VERSION ""

NS_ :

BS_:

BU_: WSGW VCM TBIOM RCIOM FCIOM CCIOM BPMU

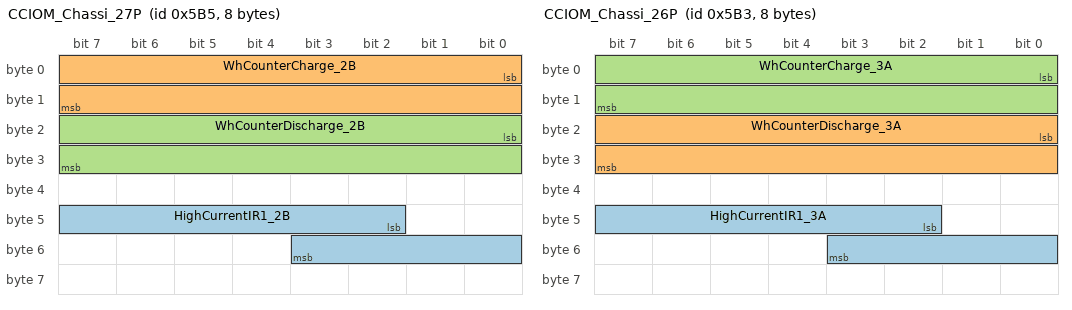
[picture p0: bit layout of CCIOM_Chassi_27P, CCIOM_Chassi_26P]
BO_ 1461 CCIOM_Chassi_27P: 8 CCIOM
 SG_ HighCurrentIR1_2B : 42|10@1+ (1E-005,0) [0|0.01023] "Ohm"  VCM
 SG_ WhCounterCharge_2B : 0|16@1+ (50,0) [0|3276750] "Wh"  VCM
 SG_ WhCounterDischarge_2B : 16|16@1+ (50,0) [0|3276750] "Wh"  VCM

BO_ 1459 CCIOM_Chassi_26P: 8 CCIOM
 SG_ HighCurrentIR1_3A : 42|10@1+ (1E-005,0) [0|0.01023] "Ohm"  VCM
 SG_ WhCounterDischarge_3A : 16|16@1+ (50,0) [0|3276750] "Wh"  VCM
 SG_ WhCounterCharge_3A : 0|16@1+ (50,0) [0|3276750] "Wh"  VCM

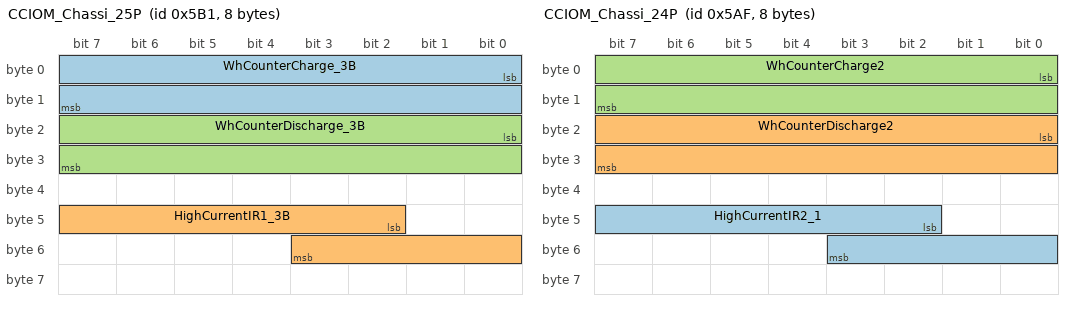
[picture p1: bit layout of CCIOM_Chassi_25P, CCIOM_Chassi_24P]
BO_ 1457 CCIOM_Chassi_25P: 8 CCIOM
 SG_ WhCounterCharge_3B : 0|16@1+ (50,0) [0|3276750] "Wh"  VCM
 SG_ HighCurrentIR1_3B : 42|10@1+ (1E-005,0) [0|0.01023] "Ohm"  VCM
 SG_ WhCounterDischarge_3B : 16|16@1+ (50,0) [0|3276750] "Wh"  VCM

BO_ 1455 CCIOM_Chassi_24P: 8 CCIOM
 SG_ HighCurrentIR2_1 : 42|10@1+ (1E-005,0) [0|0.01023] "Ohm"  VCM
 SG_ WhCounterDischarge2 : 16|16@1+ (50,0) [0|3276750] "Wh"  VCM
 SG_ WhCounterCharge2 : 0|16@1+ (50,0) [0|3276750] "Wh"  VCM

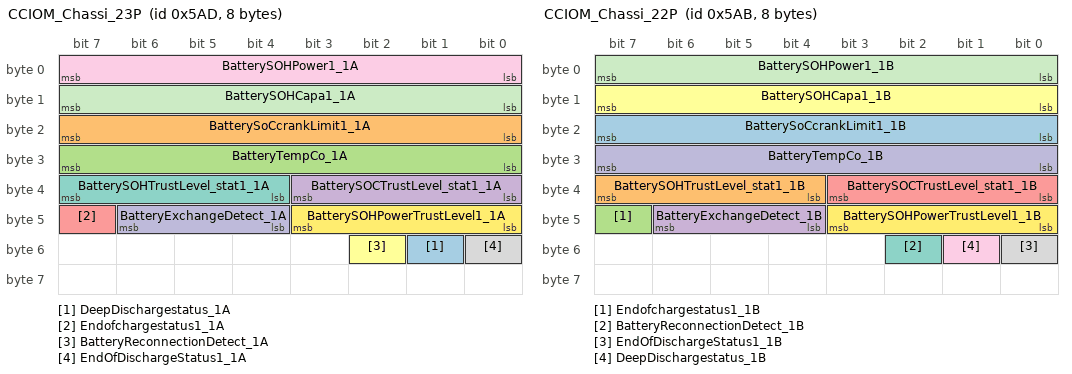
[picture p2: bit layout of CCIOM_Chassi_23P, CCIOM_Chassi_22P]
BO_ 1453 CCIOM_Chassi_23P: 8 CCIOM
 SG_ DeepDischargestatus_1A : 49|1@1+ (1,0) [0|0] ""  VCM
 SG_ BatterySoCcrankLimit1_1A : 16|8@1+ (1,0) [0|255] "Percent"  VCM
 SG_ BatteryTempCo_1A : 24|8@1+ (1,0) [0|255] "Percent"  VCM
 SG_ BatterySOCTrustLevel_stat1_1A : 32|4@1+ (1,0) [0|0] ""  VCM
 SG_ Endofchargestatus1_1A : 47|1@1+ (1,0) [0|0] ""  VCM
 SG_ BatteryReconnectionDetect_1A : 50|1@1+ (1,0) [0|0] ""  VCM
 SG_ BatterySOHTrustLevel_stat1_1A : 36|4@1+ (1,0) [0|0] ""  VCM
 SG_ EndOfDischargeStatus1_1A : 48|1@1+ (1,0) [0|0] ""  VCM
 SG_ BatterySOHPower1_1A : 0|8@1+ (0.1,0) [0|25.5] "V"  VCM
 SG_ BatteryExchangeDetect_1A : 44|3@1+ (1,0) [0|0] ""  VCM
 SG_ BatterySOHCapa1_1A : 8|8@1+ (0.5,0) [0|127.5] "Percent"  VCM
 SG_ BatterySOHPowerTrustLevel1_1A : 40|4@1+ (1,0) [0|0] ""  VCM

BO_ 1451 CCIOM_Chassi_22P: 8 CCIOM
 SG_ BatterySoCcrankLimit1_1B : 16|8@1+ (1,0) [0|255] "Percent"  VCM
 SG_ BatterySOHTrustLevel_stat1_1B : 36|4@1+ (1,0) [0|0] ""  VCM
 SG_ Endofchargestatus1_1B : 47|1@1+ (1,0) [0|0] ""  VCM
 SG_ BatteryExchangeDetect_1B : 44|3@1+ (1,0) [0|0] ""  VCM
 SG_ BatterySOCTrustLevel_stat1_1B : 32|4@1+ (1,0) [0|0] ""  VCM
 SG_ BatterySOHCapa1_1B : 8|8@1+ (0.5,0) [0|127.5] "Percent"  VCM
 SG_ BatteryReconnectionDetect_1B : 50|1@1+ (1,0) [0|0] ""  VCM
 SG_ EndOfDischargeStatus1_1B : 48|1@1+ (1,0) [0|0] ""  VCM
 SG_ DeepDischargestatus_1B : 49|1@1+ (1,0) [0|0] ""  VCM
 SG_ BatteryTempCo_1B : 24|8@1+ (1,0) [0|255] "Percent"  VCM
 SG_ BatterySOHPower1_1B : 0|8@1+ (0.1,0) [0|25.5] "V"  VCM
 SG_ BatterySOHPowerTrustLevel1_1B : 40|4@1+ (1,0) [0|0] ""  VCM

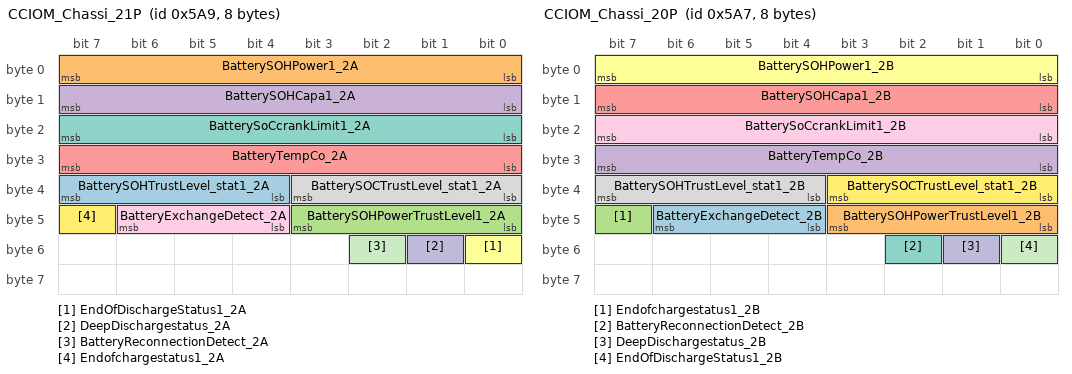
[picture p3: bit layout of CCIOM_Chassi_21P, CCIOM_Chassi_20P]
BO_ 1449 CCIOM_Chassi_21P: 8 CCIOM
 SG_ BatterySOHTrustLevel_stat1_2A : 36|4@1+ (1,0) [0|0] ""  VCM
 SG_ BatterySOHPower1_2A : 0|8@1+ (0.1,0) [0|25.5] "V"  VCM
 SG_ BatterySOHPowerTrustLevel1_2A : 40|4@1+ (1,0) [0|0] ""  VCM
 SG_ BatterySOHCapa1_2A : 8|8@1+ (0.5,0) [0|127.5] "Percent"  VCM
 SG_ BatteryTempCo_2A : 24|8@1+ (1,0) [0|255] "Percent"  VCM
 SG_ EndOfDischargeStatus1_2A : 48|1@1+ (1,0) [0|0] ""  VCM
 SG_ BatterySoCcrankLimit1_2A : 16|8@1+ (1,0) [0|255] "Percent"  VCM
 SG_ BatterySOCTrustLevel_stat1_2A : 32|4@1+ (1,0) [0|0] ""  VCM
 SG_ BatteryExchangeDetect_2A : 44|3@1+ (1,0) [0|0] ""  VCM
 SG_ DeepDischargestatus_2A : 49|1@1+ (1,0) [0|0] ""  VCM
 SG_ BatteryReconnectionDetect_2A : 50|1@1+ (1,0) [0|0] ""  VCM
 SG_ Endofchargestatus1_2A : 47|1@1+ (1,0) [0|0] ""  VCM

BO_ 1447 CCIOM_Chassi_20P: 8 CCIOM
 SG_ BatteryExchangeDetect_2B : 44|3@1+ (1,0) [0|0] ""  VCM
 SG_ BatterySOHPowerTrustLevel1_2B : 40|4@1+ (1,0) [0|0] ""  VCM
 SG_ Endofchargestatus1_2B : 47|1@1+ (1,0) [0|0] ""  VCM
 SG_ BatteryTempCo_2B : 24|8@1+ (1,0) [0|255] "Percent"  VCM
 SG_ BatterySOHCapa1_2B : 8|8@1+ (0.5,0) [0|127.5] "Percent"  VCM
 SG_ BatterySOHPower1_2B : 0|8@1+ (0.1,0) [0|25.5] "V"  VCM
 SG_ BatteryReconnectionDetect_2B : 50|1@1+ (1,0) [0|0] ""  VCM
 SG_ BatterySOHTrustLevel_stat1_2B : 36|4@1+ (1,0) [0|0] ""  VCM
 SG_ BatterySoCcrankLimit1_2B : 16|8@1+ (1,0) [0|255] "Percent"  VCM
 SG_ DeepDischargestatus_2B : 49|1@1+ (1,0) [0|0] ""  VCM
 SG_ EndOfDischargeStatus1_2B : 48|1@1+ (1,0) [0|0] ""  VCM
 SG_ BatterySOCTrustLevel_stat1_2B : 32|4@1+ (1,0) [0|0] ""  VCM

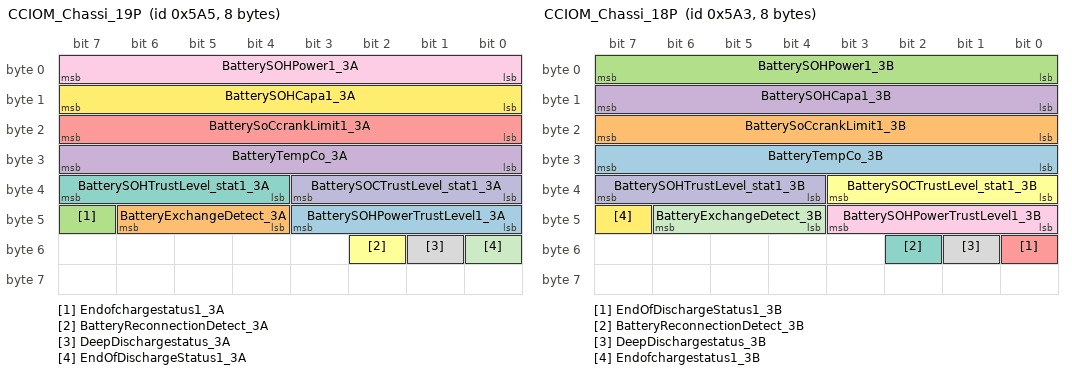
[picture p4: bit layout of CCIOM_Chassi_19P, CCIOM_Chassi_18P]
BO_ 1445 CCIOM_Chassi_19P: 8 CCIOM
 SG_ BatterySOHPowerTrustLevel1_3A : 40|4@1+ (1,0) [0|0] ""  VCM
 SG_ BatteryExchangeDetect_3A : 44|3@1+ (1,0) [0|0] ""  VCM
 SG_ Endofchargestatus1_3A : 47|1@1+ (1,0) [0|0] ""  VCM
 SG_ BatteryTempCo_3A : 24|8@1+ (1,0) [0|255] "Percent"  VCM
 SG_ BatterySoCcrankLimit1_3A : 16|8@1+ (1,0) [0|255] "Percent"  VCM
 SG_ BatteryReconnectionDetect_3A : 50|1@1+ (1,0) [0|0] ""  VCM
 SG_ BatterySOHTrustLevel_stat1_3A : 36|4@1+ (1,0) [0|0] ""  VCM
 SG_ DeepDischargestatus_3A : 49|1@1+ (1,0) [0|0] ""  VCM
 SG_ BatterySOHPower1_3A : 0|8@1+ (0.1,0) [0|25.5] "V"  VCM
 SG_ BatterySOCTrustLevel_stat1_3A : 32|4@1+ (1,0) [0|0] ""  VCM
 SG_ EndOfDischargeStatus1_3A : 48|1@1+ (1,0) [0|0] ""  VCM
 SG_ BatterySOHCapa1_3A : 8|8@1+ (0.5,0) [0|127.5] "Percent"  VCM

BO_ 1443 CCIOM_Chassi_18P: 8 CCIOM
 SG_ BatteryTempCo_3B : 24|8@1+ (1,0) [0|255] "Percent"  VCM
 SG_ BatterySoCcrankLimit1_3B : 16|8@1+ (1,0) [0|255] "Percent"  VCM
 SG_ BatterySOHPower1_3B : 0|8@1+ (0.1,0) [0|25.5] "V"  VCM
 SG_ BatterySOHCapa1_3B : 8|8@1+ (0.5,0) [0|127.5] "Percent"  VCM
 SG_ EndOfDischargeStatus1_3B : 48|1@1+ (1,0) [0|0] ""  VCM
 SG_ BatterySOCTrustLevel_stat1_3B : 32|4@1+ (1,0) [0|0] ""  VCM
 SG_ BatteryReconnectionDetect_3B : 50|1@1+ (1,0) [0|0] ""  VCM
 SG_ DeepDischargestatus_3B : 49|1@1+ (1,0) [0|0] ""  VCM
 SG_ BatterySOHPowerTrustLevel1_3B : 40|4@1+ (1,0) [0|0] ""  VCM
 SG_ BatterySOHTrustLevel_stat1_3B : 36|4@1+ (1,0) [0|0] ""  VCM
 SG_ BatteryExchangeDetect_3B : 44|3@1+ (1,0) [0|0] ""  VCM
 SG_ Endofchargestatus1_3B : 47|1@1+ (1,0) [0|0] ""  VCM

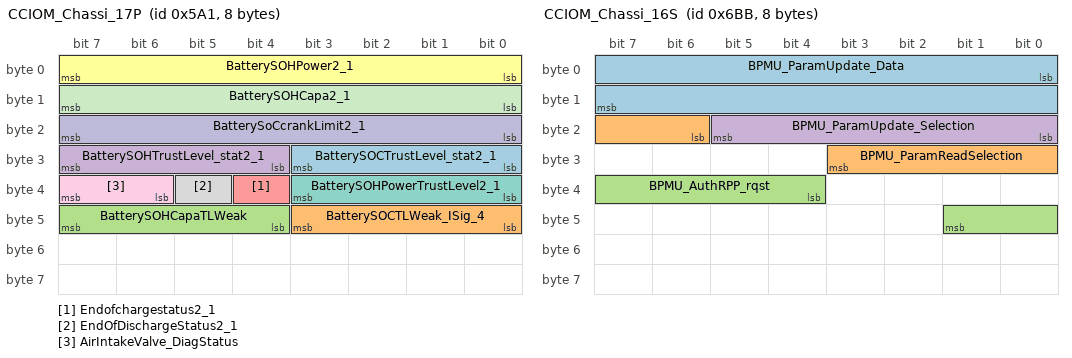
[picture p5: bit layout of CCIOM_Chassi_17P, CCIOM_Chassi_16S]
BO_ 1441 CCIOM_Chassi_17P: 8 CCIOM
 SG_ BatterySOCTrustLevel_stat2_1 : 24|4@1+ (1,0) [0|0] ""  VCM
 SG_ BatterySOCTLWeak_ISig_4 : 40|4@1+ (1,0) [0|0] ""  VCM
 SG_ BatterySOHCapaTLWeak : 44|4@1+ (1,0) [0|0] ""  VCM
 SG_ BatterySOHTrustLevel_stat2_1 : 28|4@1+ (1,0) [0|0] ""  VCM
 SG_ Endofchargestatus2_1 : 36|1@1+ (1,0) [0|0] ""  VCM
 SG_ BatterySOHPower2_1 : 0|8@1+ (0.1,0) [0|25.5] "V"  VCM
 SG_ BatterySOHPowerTrustLevel2_1 : 32|4@1+ (1,0) [0|0] ""  VCM
 SG_ EndOfDischargeStatus2_1 : 37|1@1+ (1,0) [0|0] ""  VCM
 SG_ AirIntakeValve_DiagStatus : 38|2@1+ (1,0) [0|0] ""  VCM
 SG_ BatterySoCcrankLimit2_1 : 16|8@1+ (1,0) [0|255] "Percent"  VCM
 SG_ BatterySOHCapa2_1 : 8|8@1+ (0.5,0) [0|127.5] "Percent"  VCM

BO_ 1723 CCIOM_Chassi_16S: 8 CCIOM
 SG_ BPMU_ParamUpdate_Data : 0|16@1+ (1,0) [0|0] ""  BPMU
 SG_ BPMU_ParamReadSelection : 22|6@1+ (1,0) [0|0] ""  BPMU
 SG_ BPMU_AuthRPP_rqst : 36|6@1+ (1,0) [0|0] ""  BPMU
 SG_ BPMU_ParamUpdate_Selection : 16|6@1+ (1,0) [0|0] ""  BPMU

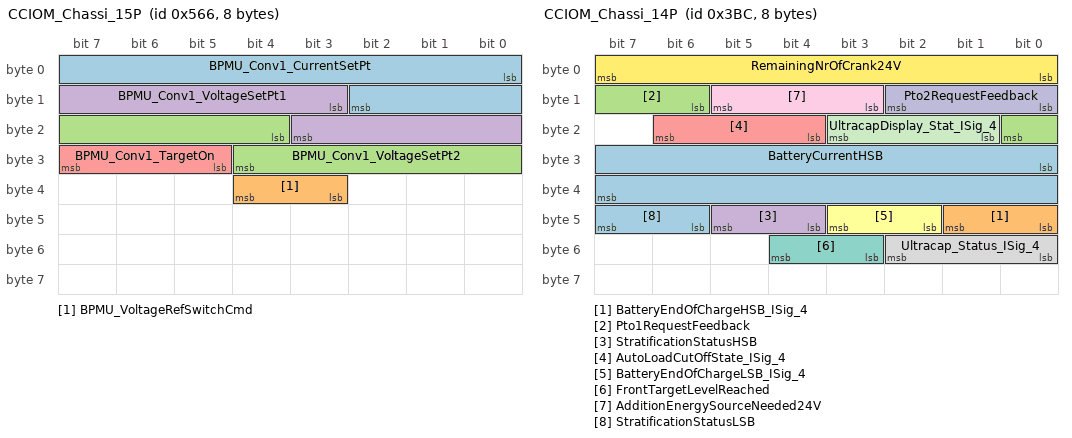
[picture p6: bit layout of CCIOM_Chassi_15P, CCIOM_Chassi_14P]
BO_ 1382 CCIOM_Chassi_15P: 8 CCIOM
 SG_ BPMU_Conv1_CurrentSetPt : 0|11@1+ (0.1,-100) [-100|104.7] "A"  BPMU
 SG_ BPMU_VoltageRefSwitchCmd : 35|2@1+ (1,0) [0|0] ""  BPMU
 SG_ BPMU_Conv1_VoltageSetPt2 : 20|9@1+ (0.1,0) [0|51.1] "V"  BPMU
 SG_ BPMU_Conv1_VoltageSetPt1 : 11|9@1+ (0.1,0) [0|51.1] "V"  BPMU
 SG_ BPMU_Conv1_TargetOn : 29|3@1+ (1,0) [0|0] ""  BPMU

BO_ 956 CCIOM_Chassi_14P: 8 CCIOM
 SG_ BatteryCurrentHSB : 24|16@1+ (0.05,-2000) [-2000|1276.75] "A"  VCM
 SG_ BatteryEndOfChargeHSB_ISig_4 : 40|2@1+ (1,0) [0|0] ""  VCM
 SG_ Pto1RequestFeedback : 14|3@1+ (1,0) [0|0] ""  VCM
 SG_ StratificationStatusHSB : 44|2@1+ (1,0) [0|0] ""  VCM
 SG_ AutoLoadCutOffState_ISig_4 : 20|3@1+ (1,0) [0|0] ""  VCM
 SG_ BatteryEndOfChargeLSB_ISig_4 : 42|2@1+ (1,0) [0|0] ""  VCM
 SG_ FrontTargetLevelReached : 51|2@1+ (1,0) [0|0] ""  RCIOM,VCM
 SG_ Ultracap_Status_ISig_4 : 48|3@1+ (1,0) [0|0] ""  VCM
 SG_ AdditionEnergySourceNeeded24V : 11|3@1+ (1,0) [0|0] ""  VCM
 SG_ Pto2RequestFeedback : 8|3@1+ (1,0) [0|0] ""  VCM
 SG_ UltracapDisplay_Stat_ISig_4 : 17|3@1+ (1,0) [0|0] ""  VCM
 SG_ RemainingNrOfCrank24V : 0|8@1+ (1,0) [0|255] "Count"  VCM
 SG_ StratificationStatusLSB : 46|2@1+ (1,0) [0|0] ""  VCM

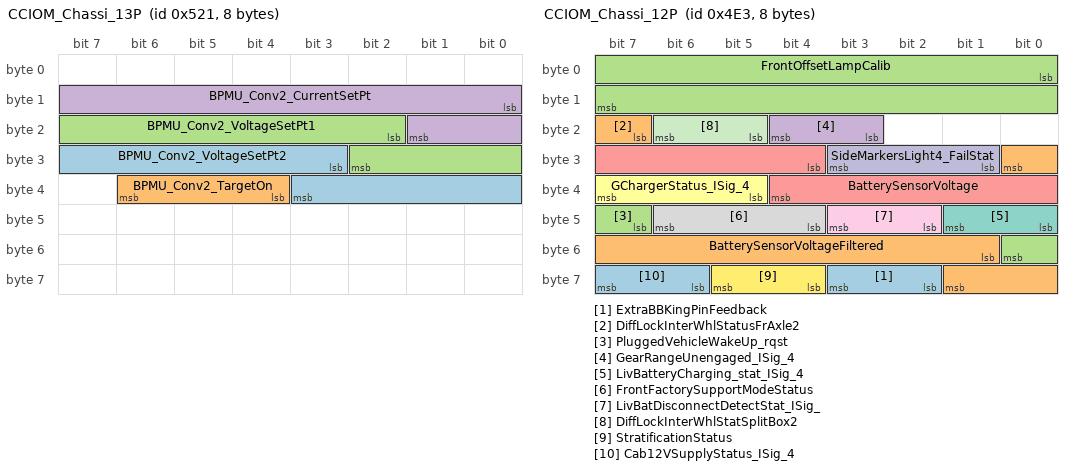
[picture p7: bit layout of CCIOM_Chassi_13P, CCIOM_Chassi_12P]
BO_ 1313 CCIOM_Chassi_13P: 8 CCIOM
 SG_ BPMU_Conv2_VoltageSetPt2 : 27|9@1+ (0.1,0) [0|51.1] "V"  BPMU
 SG_ BPMU_Conv2_TargetOn : 36|3@1+ (1,0) [0|0] ""  BPMU
 SG_ BPMU_Conv2_VoltageSetPt1 : 18|9@1+ (0.1,0) [0|51.1] "V"  BPMU
 SG_ BPMU_Conv2_CurrentSetPt : 8|10@1+ (0.1,-30) [-30|72.3] "A"  BPMU

BO_ 1251 CCIOM_Chassi_12P: 8 CCIOM
 SG_ ExtraBBKingPinFeedback : 58|2@1+ (1,0) [0|0] ""  VCM
 SG_ DiffLockInterWhlStatusFrAxle2 : 23|2@1+ (1,0) [0|0] ""  VCM
 SG_ PluggedVehicleWakeUp_rqst : 47|2@1+ (1,0) [0|0] ""  VCM
 SG_ GearRangeUnengaged_ISig_4 : 19|2@1+ (1,0) [0|0] ""  VCM
 SG_ BatterySensorVoltage : 28|9@1+ (0.1,0) [0|51.1] "V"  VCM
 SG_ GChargerStatus_ISig_4 : 37|3@1+ (1,0) [0|0] ""  VCM
 SG_ LivBatteryCharging_stat_ISig_4 : 40|2@1+ (1,0) [0|0] ""  VCM
 SG_ FrontFactorySupportModeStatus : 44|3@1+ (1,0) [0|0] ""  RCIOM,VCM
 SG_ LivBatDisconnectDetectStat_ISig_ : 42|2@1+ (1,0) [0|0] ""  VCM
 SG_ SideMarkersLight4_FailStat : 25|3@1+ (1,0) [0|0] ""  VCM
 SG_ DiffLockInterWhlStatSplitBox2 : 21|2@1+ (1,0) [0|0] ""  VCM
 SG_ StratificationStatus : 60|2@1+ (1,0) [0|0] ""  VCM
 SG_ Cab12VSupplyStatus_ISig_4 : 62|2@1+ (1,0) [0|0] ""  VCM
 SG_ BatterySensorVoltageFiltered : 49|9@1+ (0.1,0) [0|51.1] "V"  VCM
 SG_ FrontOffsetLampCalib : 0|16@1+ (0.1,-3200) [-3200|3353.5] "mm"  RCIOM,VCM

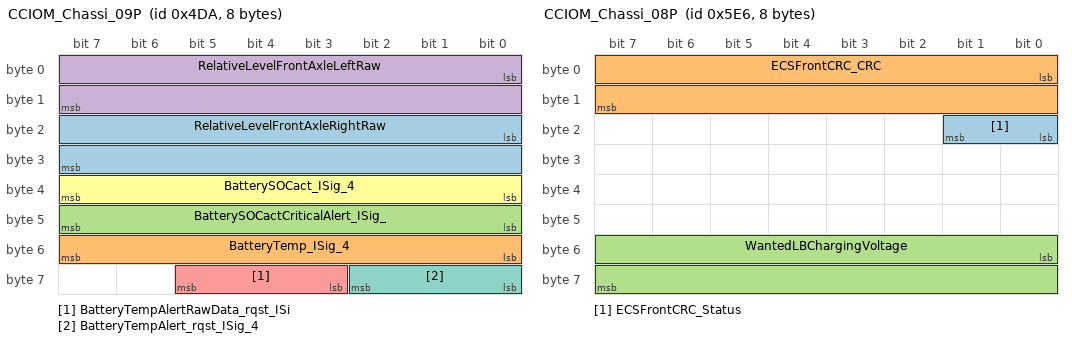
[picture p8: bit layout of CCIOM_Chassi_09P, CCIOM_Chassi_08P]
BO_ 1242 CCIOM_Chassi_09P: 8 CCIOM
 SG_ RelativeLevelFrontAxleRightRaw : 16|16@1+ (0.1,-3200) [-3200|3353.5] "mm"  VCM,RCIOM
 SG_ BatteryTemp_ISig_4 : 48|8@1+ (1,-45) [-45|210] "DegreeC"  VCM
 SG_ BatterySOCactCriticalAlert_ISig_ : 40|8@1+ (0.5,0) [0|127.5] "Percent"  VCM
 SG_ RelativeLevelFrontAxleLeftRaw : 0|16@1+ (0.1,-3200) [-3200|3353.5] "mm"  RCIOM,VCM
 SG_ BatteryTempAlertRawData_rqst_ISi : 59|3@1+ (1,0) [0|0] ""  VCM
 SG_ BatterySOCact_ISig_4 : 32|8@1+ (0.5,0) [0|127.5] "Percent"  VCM
 SG_ BatteryTempAlert_rqst_ISig_4 : 56|3@1+ (1,0) [0|0] ""  VCM

BO_ 1510 CCIOM_Chassi_08P: 8 CCIOM
 SG_ ECSFrontCRC_Status : 16|2@1+ (1,0) [0|0] ""  VCM,RCIOM
 SG_ ECSFrontCRC_CRC : 0|16@1+ (1,0) [0|65535] "NotApplicable"  VCM,RCIOM
 SG_ WantedLBChargingVoltage : 48|16@1+ (0.01,0) [0|655.35] "V"  VCM

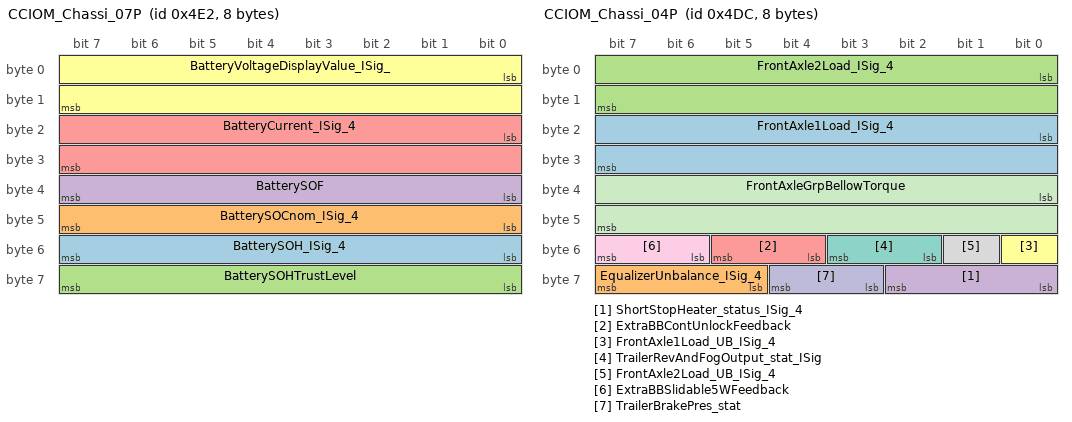
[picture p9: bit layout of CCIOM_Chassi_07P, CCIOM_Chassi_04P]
BO_ 1250 CCIOM_Chassi_07P: 8 CCIOM
 SG_ BatterySOH_ISig_4 : 48|8@1+ (0.5,0) [0|127.5] "Percent"  VCM
 SG_ BatterySOCnom_ISig_4 : 40|8@1+ (0.5,0) [0|127.5] "Percent"  VCM
 SG_ BatterySOHTrustLevel : 56|8@1+ (0.5,0) [0|127.5] "Percent"  VCM
 SG_ BatterySOF : 32|8@1+ (1,0) [0|255] "h"  VCM
 SG_ BatteryCurrent_ISig_4 : 16|16@1+ (0.05,-1600) [-1600|1676.75] "A"  VCM
 SG_ BatteryVoltageDisplayValue_ISig_ : 0|16@1+ (0.05,0) [0|3276.75] "V"  VCM

BO_ 823 CCIOM_Chassi_06P: 8 CCIOM
 SG_ DifferentialLockStateFrAxle1_UB_ : 31|1@1+ (1,0) [0|0] ""  VCM
 SG_ FrontLimpHomeTrigger : 24|3@1+ (1,0) [0|0] ""  VCM,RCIOM
 SG_ TransmLowRangeSenseSwitch_ISig_4 : 8|2@1+ (1,0) [0|0] ""  VCM
 SG_ ElectricalLoadReduction_rqst_ISi : 21|3@1+ (1,0) [0|0] ""  VCM,RCIOM
 SG_ TransmReverseDirectionSw_stat : 56|2@1+ (1,0) [0|0] ""  VCM
 SG_ FifthWheelLockingInformation_UB_ : 53|1@1+ (1,0) [0|0] ""  VCM,RCIOM
 SG_ ManTransmiOilTemp_ISig_4 : 32|16@1+ (0.03125,-273) [-273|1774.96875] "DegreeC"  VCM
 SG_ DirInd_MiddleSide_Status : 58|3@1+ (1,0) [0|0] ""  VCM
 SG_ BatterySOCAlert_rqst_ISig_4 : 16|3@1+ (1,0) [0|0] ""  VCM
 SG_ DoubleFrontAxleSteeringWarning_I : 2|2@1+ (1,0) [0|0] ""  VCM
 SG_ DifferentialLockStateCentral_ISi : 0|2@1+ (1,0) [0|0] ""  VCM
 SG_ FifthWheelLockingInformation_ISi : 12|4@1+ (1,0) [0|0] ""  RCIOM,VCM
 SG_ ElectricalLoadReduction_rqst_UB_ : 30|1@1+ (1,0) [0|0] ""  VCM,RCIOM
 SG_ DiffLockInterWhlStatusSplitBox : 54|2@1+ (1,0) [0|0] ""  VCM
 SG_ WrknLghtChassisOutpFalr_stat : 48|3@1+ (1,0) [0|0] ""  VCM
 SG_ DifferentialLockStateFrAxle1_ISi : 6|2@1+ (1,0) [0|0] ""  VCM
 SG_ GearSplit_Status_ISig_4 : 10|2@1+ (1,0) [0|0] ""  VCM
 SG_ ManTransmiOilTemp_UB_ISig_4 : 51|1@1+ (1,0) [0|0] ""  VCM
 SG_ LoadCutOffIndication_cmd_ISig_4 : 4|2@1+ (1,0) [0|0] ""  VCM
 SG_ FifthWheelHandleLock_ind : 27|2@1+ (1,0) [0|0] ""  VCM
 SG_ GearSplit_Status_UB_ISig_4 : 52|1@1+ (1,0) [0|0] ""  VCM
 SG_ BatteryCapacity_Ack_ISig_4 : 19|2@1+ (1,0) [0|0] ""  VCM

BO_ 1244 CCIOM_Chassi_04P: 8 CCIOM
 SG_ FrontAxle1Load_ISig_4 : 16|16@1+ (0.5,0) [0|32767.5] "kg"  RCIOM,VCM
 SG_ EqualizerUnbalance_ISig_4 : 61|3@1+ (1,0) [0|0] ""  VCM
 SG_ FrontAxle2Load_ISig_4 : 0|16@1+ (0.5,0) [0|32767.5] "kg"  RCIOM,VCM
 SG_ ShortStopHeater_status_ISig_4 : 56|3@1+ (1,0) [0|0] ""  VCM
 SG_ ExtraBBContUnlockFeedback : 52|2@1+ (1,0) [0|0] ""  VCM
 SG_ FrontAxle1Load_UB_ISig_4 : 48|1@1+ (1,0) [0|0] ""  RCIOM,VCM
 SG_ TrailerRevAndFogOutput_stat_ISig : 50|2@1+ (1,0) [0|0] ""  VCM,RCIOM
 SG_ FrontAxle2Load_UB_ISig_4 : 49|1@1+ (1,0) [0|0] ""  VCM,RCIOM
 SG_ ExtraBBSlidable5WFeedback : 54|2@1+ (1,0) [0|0] ""  VCM
 SG_ TrailerBrakePres_stat : 59|2@1+ (1,0) [0|0] ""  VCM
 SG_ FrontAxleGrpBellowTorque : 32|16@1+ (1000,-10000000) [-10000000|55535000] "Nm"  VCM,RCIOM

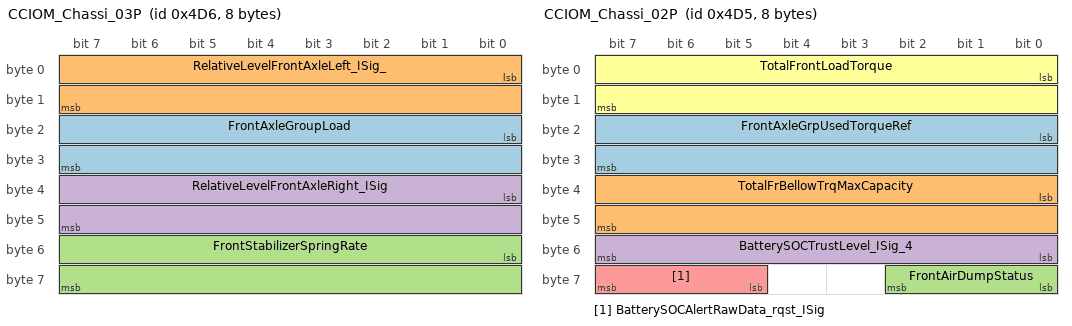
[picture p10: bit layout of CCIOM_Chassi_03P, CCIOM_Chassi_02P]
BO_ 1238 CCIOM_Chassi_03P: 8 CCIOM
 SG_ FrontAxleGroupLoad : 16|16@1+ (2,0) [0|131070] "kg"  RCIOM,VCM
 SG_ RelativeLevelFrontAxleLeft_ISig_ : 0|16@1+ (0.1,-3200) [-3200|3353.5] "mm"  RCIOM,VCM
 SG_ FrontStabilizerSpringRate : 48|16@1+ (1,0) [0|65535] "kNm_per_rad"  RCIOM,VCM
 SG_ RelativeLevelFrontAxleRight_ISig : 32|16@1+ (0.1,-3200) [-3200|3353.5] "mm"  VCM,RCIOM

BO_ 1237 CCIOM_Chassi_02P: 8 CCIOM
 SG_ FrontAxleGrpUsedTorqueRef : 16|16@1+ (1000,-10000000) [-10000000|55535000] "Nm"  VCM,RCIOM
 SG_ TotalFrBellowTrqMaxCapacity : 32|16@1+ (1000,-10000000) [-10000000|55535000] "Nm"  RCIOM,VCM
 SG_ FrontAirDumpStatus : 56|3@1+ (1,0) [0|0] ""  RCIOM,VCM
 SG_ BatterySOCTrustLevel_ISig_4 : 48|8@1+ (0.5,0) [0|127.5] "Percent"  VCM
 SG_ BatterySOCAlertRawData_rqst_ISig : 61|3@1+ (1,0) [0|0] ""  VCM
 SG_ TotalFrontLoadTorque : 0|16@1+ (1000,-10000000) [-10000000|55535000] "Nm"  RCIOM,VCM

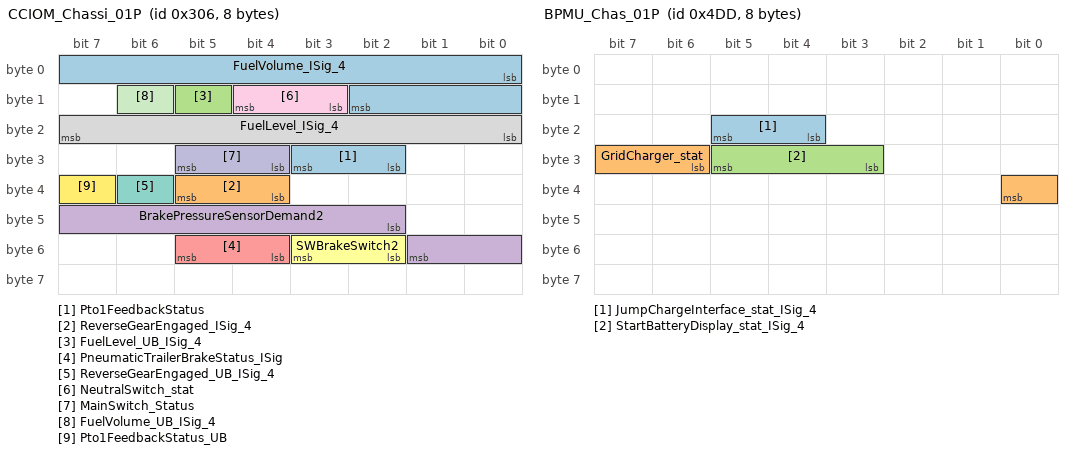
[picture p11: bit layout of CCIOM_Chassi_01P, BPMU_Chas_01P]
BO_ 774 CCIOM_Chassi_01P: 8 CCIOM
 SG_ Pto1FeedbackStatus : 26|2@1+ (1,0) [0|0] ""  VCM
 SG_ ReverseGearEngaged_ISig_4 : 36|2@1+ (1,0) [0|0] ""  VCM,WSGW,RCIOM
 SG_ FuelLevel_UB_ISig_4 : 13|1@1+ (1,0) [0|0] ""  VCM
 SG_ BrakePressureSensorDemand2 : 42|8@1+ (1,0) [0|255] "Percent"  RCIOM,VCM
 SG_ PneumaticTrailerBrakeStatus_ISig : 52|2@1+ (1,0) [0|0] ""  VCM,RCIOM
 SG_ SWBrakeSwitch2 : 50|2@1+ (1,0) [0|0] ""  VCM,RCIOM
 SG_ ReverseGearEngaged_UB_ISig_4 : 38|1@1+ (1,0) [0|0] ""  VCM,RCIOM
 SG_ FuelLevel_ISig_4 : 16|8@1+ (0.4,0) [0|102] "Percent"  VCM
 SG_ NeutralSwitch_stat : 11|2@1+ (1,0) [0|0] ""  VCM
 SG_ MainSwitch_Status : 28|2@1+ (1,0) [0|0] ""  VCM
 SG_ FuelVolume_UB_ISig_4 : 14|1@1+ (1,0) [0|0] ""  VCM
 SG_ Pto1FeedbackStatus_UB : 39|1@1+ (1,0) [0|0] ""  VCM
 SG_ FuelVolume_ISig_4 : 0|11@1+ (1,0) [0|2047] "l"  VCM

BO_ 1245 BPMU_Chas_01P: 8 VCM
 SG_ JumpChargeInterface_stat_ISig_4 : 20|2@1+ (1,0) [0|0] ""  CCIOM
 SG_ GridCharger_stat : 30|3@1+ (1,0) [0|0] ""  CCIOM
 SG_ StartBatteryDisplay_stat_ISig_4 : 27|3@1+ (1,0) [0|0] ""  CCIOM

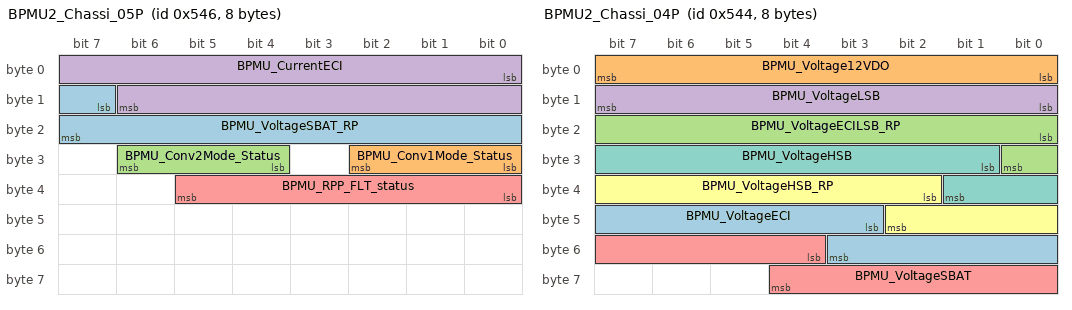
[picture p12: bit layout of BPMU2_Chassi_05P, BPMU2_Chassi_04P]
BO_ 1350 BPMU2_Chassi_05P: 8 BPMU
 SG_ BPMU_VoltageSBAT_RP : 15|9@1+ (0.1,0) [0|51.1] "V"  CCIOM
 SG_ BPMU_Conv1Mode_Status : 24|3@1+ (1,0) [0|0] ""  CCIOM
 SG_ BPMU_Conv2Mode_Status : 28|3@1+ (1,0) [0|0] ""  CCIOM
 SG_ BPMU_CurrentECI : 0|15@1+ (0.01,-150) [-150|177.67] "A"  CCIOM
 SG_ BPMU_RPP_FLT_status : 32|6@1+ (1,0) [0|63] "NotApplicable"  CCIOM

BO_ 1348 BPMU2_Chassi_04P: 8 BPMU
 SG_ BPMU_VoltageECI : 43|9@1+ (0.1,0) [0|51.1] "V"  CCIOM
 SG_ BPMU_Voltage12VDO : 0|8@1+ (0.1,0) [0|25.5] "V"  CCIOM
 SG_ BPMU_VoltageECILSB_RP : 16|9@1+ (0.1,0) [0|51.1] "V"  CCIOM
 SG_ BPMU_VoltageLSB : 8|8@1+ (0.1,0) [0|25.5] "V"  CCIOM
 SG_ BPMU_VoltageSBAT : 52|9@1+ (0.1,0) [0|51.1] "V"  CCIOM
 SG_ BPMU_VoltageHSB_RP : 34|9@1+ (0.1,0) [0|51.1] "V"  CCIOM
 SG_ BPMU_VoltageHSB : 25|9@1+ (0.1,0) [0|51.1] "V"  CCIOM

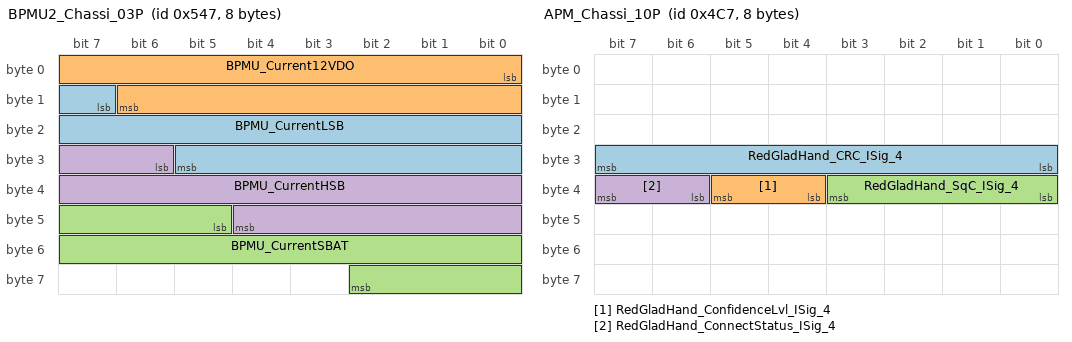
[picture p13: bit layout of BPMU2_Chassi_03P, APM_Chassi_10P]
BO_ 1351 BPMU2_Chassi_03P: 8 BPMU
 SG_ BPMU_CurrentLSB : 15|15@1+ (0.01,-150) [-150|177.67] "A"  CCIOM
 SG_ BPMU_Current12VDO : 0|15@1+ (0.01,-150) [-150|177.67] "A"  CCIOM
 SG_ BPMU_CurrentSBAT : 45|14@1+ (0.01,-50) [-50|113.83] "A"  CCIOM
 SG_ BPMU_CurrentHSB : 30|15@1+ (0.01,-150) [-150|177.67] "A"  CCIOM

BO_ 1252 BPMU2_Chassi_02P: 8 BPMU
 SG_ BPMU_FaultDiag2 : 32|32@1+ (1,0) [0|4294967295] "NotApplicable"  CCIOM
 SG_ BPMU_FaultDiag1 : 0|32@1+ (1,0) [0|4294967295] "NotApplicable"  CCIOM

BO_ 831 BPMU2_Chassi_01S: 8 BPMU
 SG_ BPMU_ParamRead_Data : 0|16@1+ (1,0) [0|0] ""  CCIOM
 SG_ BPMU_ParamRead_Selection : 16|6@1+ (1,0) [0|0] ""  CCIOM

BO_ 1730 AnmMsg_WSGW_C04: 8 WSGW
 SG_ AnmSig_WSGW_C04 : 0|32@1+ (1,0) [0|0] ""  VCM,RCIOM,FCIOM,CCIOM,TBIOM,BPMU

BO_ 1726 AnmMsg_VCM_C04: 8 VCM
 SG_ AnmSig_VCM_CAN04 : 0|32@1+ (1,0) [0|0] ""  FCIOM,CCIOM,BPMU,WSGW,TBIOM,RCIOM

BO_ 1725 AnmMsg_TBIOM_C04: 8 TBIOM
 SG_ AnmSig_TBIOM_CAN04 : 0|32@1+ (1,0) [0|0] ""  VCM,FCIOM,CCIOM,BPMU,RCIOM,WSGW

BO_ 1724 AnmMsg_RCIOM_C04: 8 RCIOM
 SG_ AnmSig_RCIOM_CAN04 : 0|32@1+ (1,0) [0|0] ""  VCM,WSGW,BPMU,FCIOM,CCIOM,TBIOM

BO_ 1729 AnmMsg_FCIOM_C04: 8 FCIOM
 SG_ AnmSig_FCIOM_CAN04 : 0|32@1+ (1,0) [0|0] ""  VCM,BPMU,CCIOM,WSGW,TBIOM,RCIOM

BO_ 1727 AnmMsg_CCIOM_C04: 8 CCIOM
 SG_ AnmSig_CCIOM_CAN04 : 0|32@1+ (1,0) [0|0] ""  BPMU,RCIOM,TBIOM,VCM,FCIOM,WSGW

BO_ 1728 AnmMsg_BPMU_C04: 8 BPMU
 SG_ AnmSig_BPMU_CAN04 : 0|32@1+ (1,0) [0|0] ""  TBIOM,FCIOM,WSGW,CCIOM,RCIOM,VCM

BO_ 1223 APM_Chassi_10P: 8 VCM
 SG_ RedGladHand_CRC_ISig_4 : 24|8@1+ (1,0) [0|255] ""  RCIOM
 SG_ RedGladHand_ConfidenceLvl_ISig_4 : 36|2@1+ (1,0) [0|0] ""  RCIOM
 SG_ RedGladHand_SqC_ISig_4 : 32|4@1+ (1,0) [0|14] "NotApplicable"  RCIOM
 SG_ RedGladHand_ConnectStatus_ISig_4 : 38|2@1+ (1,0) [0|0] ""  RCIOM

BO_ 822 APM_Chassi_04P: 8 VCM
 SG_ EPBPowerFeedRequest_ISig_4 : 32|2@1+ (1,0) [0|0] ""  CCIOM

BO_ 1345 APM_Chassi_02P: 8 VCM
 SG_ ServiceBrakeAirPrsCircuit1_ISig_ : 8|8@1+ (8,0) [0|2040] "kPa"  RCIOM

BO_ 949 APM_Chassi_01P: 8 VCM
 SG_ LowAirPressureAlert_ISig_4 : 18|2@1+ (1,0) [0|0] ""  RCIOM
 SG_ ParkBrakeActuationStatus_ISig_4 : 32|3@1+ (1,0) [0|0] ""  RCIOM,CCIOM

BA_DEF_ BO_  "GenMsgStartDelayTime" INT 0 0;
BA_DEF_ BO_  "GenMsgDelayTime" INT 0 0;
BA_DEF_ BO_  "GenMsgCycleTime" INT 0 0;
BA_DEF_ BO_  "GenMsgSendType" ENUM  "Cyclic","NotUsed","NotUsed","NotUsed","NotUsed","NotUsed","NotUsed","IfActive","NoMsgSendType","NotUsed";
BA_DEF_ SG_  "GenSigStartValue" INT 0 0;
BA_DEF_ SG_  "GenSigInactiveValue" INT 0 0;
BA_DEF_ SG_  "GenSigCycleTimeActive" INT 0 0;
BA_DEF_ SG_  "GenSigCycleTime" INT 0 0;
BA_DEF_ SG_  "GenSigSendType" ENUM  "Cyclic","OnWrite","OnWriteWithRepetition","OnChange","OnChangeWithRepetition","IfActive","IfActiveWithRepetition","NoSigSendType","NotUsed","NotUsed","NotUsed","NotUsed","NotUsed";
BA_DEF_ BO_  "VFrameFormat" ENUM  "StandardCAN","ExtendedCAN","reserved","J1939PG","reserved","reserved","reserved","reserved","reserved","reserved","reserved","reserved","reserved","reserved","StandardCAN_FD","ExtendedCAN_FD";
BA_DEF_ SG_  "SigType" ENUM  "Default","Range","RangeSigned","ASCII","Discrete","Control","ReferencePGN","DTC","StringDelimiter","StringLength","StringLengthControl";
BA_DEF_ SG_  "Platform_Vivis2_Sig" ENUM  "No","Yes";
BA_DEF_ SG_  "Platform_VMCU1_Sig" ENUM  "No","Yes";
BA_DEF_ BO_  "NmAsrMessage" ENUM  "No","Yes";
BA_DEF_ SG_  "NeedsUpdateBit" ENUM  "No","Yes";
BA_DEF_ SG_  "MmAnSignal" ENUM  "No","Yes";
BA_DEF_ SG_  "GenSigMaxLatency" INT 0 65535;
BA_DEF_ SG_  "GenSigILSupport" ENUM  "Yes","No";
BA_DEF_ BO_  "GenMsgILSupport" ENUM  "No","Yes";
BA_DEF_ SG_  "E2EProfile" STRING ;
BA_DEF_ SG_  "E2EDataLength" INT 0 65535;
BA_DEF_ SG_  "E2EDataId" INT 0 65535;
BA_DEF_ BO_  "DiagUUDTResponse" ENUM  "No","Yes";
BA_DEF_ BO_  "DiagState" ENUM  "No","Yes";
BA_DEF_ BO_  "DiagResponse" ENUM  "No","Yes";
BA_DEF_ BO_  "DiagRequest" ENUM  "No","Yes";
BA_DEF_ BO_  "DiagConnection" HEX 0 65535;
BA_DEF_ BO_  "CanTpFcFrameId" HEX 0 2147483647;
BA_DEF_ BO_  "CanTpBs" INT 0 255;
BA_DEF_ SG_  "SystemSignalLongSymbol" STRING ;
BA_DEF_REL_ BU_SG_REL_  "GenSigTimeoutTime" INT 0 65535;
BA_DEF_REL_ BU_SG_REL_  "GenSigFirstTimeoutTime" INT 0 65535;
BA_DEF_DEF_  "GenMsgStartDelayTime" 0;
BA_DEF_DEF_  "GenMsgDelayTime" 0;
BA_DEF_DEF_  "GenMsgCycleTime" 0;
BA_DEF_DEF_  "GenMsgSendType" "Cyclic";
BA_DEF_DEF_  "GenSigStartValue" 0;
BA_DEF_DEF_  "GenSigInactiveValue" 0;
BA_DEF_DEF_  "GenSigCycleTimeActive" 0;
BA_DEF_DEF_  "GenSigCycleTime" 0;
BA_DEF_DEF_  "GenSigSendType" "Cyclic";
BA_DEF_DEF_  "VFrameFormat" "ExtendedCAN";
BA_DEF_DEF_  "SigType" "Default";
BA_DEF_DEF_  "Platform_Vivis2_Sig" "No";
BA_DEF_DEF_  "Platform_VMCU1_Sig" "No";
BA_DEF_DEF_  "NmAsrMessage" "No";
BA_DEF_DEF_  "NeedsUpdateBit" "No";
BA_DEF_DEF_  "MmAnSignal" "No";
BA_DEF_DEF_  "GenSigMaxLatency" 0;
BA_DEF_DEF_  "GenSigILSupport" "Yes";
BA_DEF_DEF_  "GenMsgILSupport" "Yes";
BA_DEF_DEF_  "E2EProfile" "none";
BA_DEF_DEF_  "E2EDataLength" 0;
BA_DEF_DEF_  "E2EDataId" 0;
BA_DEF_DEF_  "DiagUUDTResponse" "No";
BA_DEF_DEF_  "DiagState" "No";
BA_DEF_DEF_  "DiagResponse" "No";
BA_DEF_DEF_  "DiagRequest" "No";
BA_DEF_DEF_  "DiagConnection" 0;
BA_DEF_DEF_  "CanTpFcFrameId" 2147483647;
BA_DEF_DEF_  "CanTpBs" 255;
BA_DEF_DEF_REL_ "GenSigTimeoutTime" 0;
BA_DEF_DEF_REL_ "GenSigFirstTimeoutTime" 0;
BA_DEF_DEF_  "SystemSignalLongSymbol" "";
BA_ "VFrameFormat" BO_ 1461 0;
BA_ "GenMsgCycleTime" BO_ 1461 1000;
BA_ "GenMsgStartDelayTime" BO_ 1461 195;
BA_ "VFrameFormat" BO_ 1459 0;
BA_ "GenMsgCycleTime" BO_ 1459 1000;
BA_ "GenMsgStartDelayTime" BO_ 1459 180;
BA_ "VFrameFormat" BO_ 1457 0;
BA_ "GenMsgCycleTime" BO_ 1457 1000;
BA_ "GenMsgStartDelayTime" BO_ 1457 165;
BA_ "VFrameFormat" BO_ 1455 0;
BA_ "GenMsgCycleTime" BO_ 1455 1000;
BA_ "GenMsgStartDelayTime" BO_ 1455 150;
BA_ "VFrameFormat" BO_ 1453 0;
BA_ "GenMsgCycleTime" BO_ 1453 1000;
BA_ "GenMsgStartDelayTime" BO_ 1453 135;
BA_ "VFrameFormat" BO_ 1451 0;
BA_ "GenMsgCycleTime" BO_ 1451 1000;
BA_ "GenMsgStartDelayTime" BO_ 1451 120;
BA_ "VFrameFormat" BO_ 1449 0;
BA_ "GenMsgCycleTime" BO_ 1449 1000;
BA_ "GenMsgStartDelayTime" BO_ 1449 105;
BA_ "VFrameFormat" BO_ 1447 0;
BA_ "GenMsgCycleTime" BO_ 1447 1000;
BA_ "GenMsgStartDelayTime" BO_ 1447 90;
BA_ "VFrameFormat" BO_ 1445 0;
BA_ "GenMsgCycleTime" BO_ 1445 1000;
BA_ "GenMsgStartDelayTime" BO_ 1445 75;
BA_ "VFrameFormat" BO_ 1443 0;
BA_ "GenMsgCycleTime" BO_ 1443 1000;
BA_ "GenMsgStartDelayTime" BO_ 1443 60;
BA_ "VFrameFormat" BO_ 1441 0;
BA_ "GenMsgCycleTime" BO_ 1441 1000;
BA_ "GenMsgStartDelayTime" BO_ 1441 50;
BA_ "VFrameFormat" BO_ 1723 0;
BA_ "GenMsgSendType" BO_ 1723 8;
BA_ "GenMsgDelayTime" BO_ 1723 50;
BA_ "VFrameFormat" BO_ 1382 0;
BA_ "GenMsgCycleTime" BO_ 1382 200;
BA_ "GenMsgStartDelayTime" BO_ 1382 120;
BA_ "VFrameFormat" BO_ 956 0;
BA_ "GenMsgCycleTime" BO_ 956 100;
BA_ "GenMsgStartDelayTime" BO_ 956 50;
BA_ "VFrameFormat" BO_ 1313 0;
BA_ "GenMsgCycleTime" BO_ 1313 200;
BA_ "GenMsgStartDelayTime" BO_ 1313 15;
BA_ "VFrameFormat" BO_ 1251 0;
BA_ "GenMsgCycleTime" BO_ 1251 100;
BA_ "GenMsgStartDelayTime" BO_ 1251 40;
BA_ "VFrameFormat" BO_ 1242 0;
BA_ "GenMsgCycleTime" BO_ 1242 50;
BA_ "GenMsgStartDelayTime" BO_ 1242 25;
BA_ "VFrameFormat" BO_ 1510 0;
BA_ "GenMsgCycleTime" BO_ 1510 2000;
BA_ "GenMsgStartDelayTime" BO_ 1510 230;
BA_ "VFrameFormat" BO_ 1250 0;
BA_ "GenMsgCycleTime" BO_ 1250 100;
BA_ "GenMsgStartDelayTime" BO_ 1250 30;
BA_ "VFrameFormat" BO_ 823 0;
BA_ "GenMsgCycleTime" BO_ 823 30;
BA_ "GenMsgStartDelayTime" BO_ 823 5;
BA_ "VFrameFormat" BO_ 1244 0;
BA_ "GenMsgCycleTime" BO_ 1244 100;
BA_ "GenMsgStartDelayTime" BO_ 1244 10;
BA_ "VFrameFormat" BO_ 1238 0;
BA_ "GenMsgCycleTime" BO_ 1238 50;
BA_ "GenMsgStartDelayTime" BO_ 1238 15;
BA_ "VFrameFormat" BO_ 1237 0;
BA_ "GenMsgCycleTime" BO_ 1237 50;
BA_ "GenMsgStartDelayTime" BO_ 1237 5;
BA_ "VFrameFormat" BO_ 774 0;
BA_ "GenMsgCycleTime" BO_ 774 25;
BA_ "GenMsgStartDelayTime" BO_ 774 5;
BA_ "VFrameFormat" BO_ 1245 0;
BA_ "GenMsgCycleTime" BO_ 1245 100;
BA_ "GenMsgStartDelayTime" BO_ 1245 30;
BA_ "VFrameFormat" BO_ 1350 0;
BA_ "GenMsgCycleTime" BO_ 1350 250;
BA_ "GenMsgStartDelayTime" BO_ 1350 50;
BA_ "VFrameFormat" BO_ 1348 0;
BA_ "GenMsgCycleTime" BO_ 1348 250;
BA_ "GenMsgStartDelayTime" BO_ 1348 35;
BA_ "VFrameFormat" BO_ 1351 0;
BA_ "GenMsgCycleTime" BO_ 1351 250;
BA_ "GenMsgStartDelayTime" BO_ 1351 10;
BA_ "VFrameFormat" BO_ 1252 0;
BA_ "GenMsgCycleTime" BO_ 1252 100;
BA_ "GenMsgStartDelayTime" BO_ 1252 5;
BA_ "VFrameFormat" BO_ 831 0;
BA_ "GenMsgSendType" BO_ 831 8;
BA_ "GenMsgStartDelayTime" BO_ 831 50;
BA_ "VFrameFormat" BO_ 1730 0;
BA_ "GenMsgCycleTime" BO_ 1730 100;
BA_ "VFrameFormat" BO_ 1726 0;
BA_ "GenMsgCycleTime" BO_ 1726 100;
BA_ "VFrameFormat" BO_ 1725 0;
BA_ "GenMsgCycleTime" BO_ 1725 100;
BA_ "VFrameFormat" BO_ 1724 0;
BA_ "GenMsgCycleTime" BO_ 1724 100;
BA_ "VFrameFormat" BO_ 1729 0;
BA_ "GenMsgCycleTime" BO_ 1729 100;
BA_ "VFrameFormat" BO_ 1727 0;
BA_ "GenMsgCycleTime" BO_ 1727 100;
BA_ "VFrameFormat" BO_ 1728 0;
BA_ "GenMsgCycleTime" BO_ 1728 100;
BA_ "VFrameFormat" BO_ 1223 0;
BA_ "GenMsgCycleTime" BO_ 1223 100;
BA_ "GenMsgStartDelayTime" BO_ 1223 25;
BA_ "VFrameFormat" BO_ 822 0;
BA_ "GenMsgCycleTime" BO_ 822 30;
BA_ "GenMsgStartDelayTime" BO_ 822 10;
BA_ "VFrameFormat" BO_ 1345 0;
BA_ "GenMsgCycleTime" BO_ 1345 250;
BA_ "GenMsgStartDelayTime" BO_ 1345 15;
BA_ "VFrameFormat" BO_ 949 0;
BA_ "GenMsgCycleTime" BO_ 949 50;
BA_ "GenMsgStartDelayTime" BO_ 949 10;
BA_ "GenSigCycleTime" SG_ 1461 HighCurrentIR1_2B 100;
BA_ "GenSigCycleTimeActive" SG_ 1461 HighCurrentIR1_2B 100;
BA_ "GenSigStartValue" SG_ 1461 HighCurrentIR1_2B 1023;
BA_ "GenSigMaxLatency" SG_ 1461 HighCurrentIR1_2B 1015;
BA_ "Platform_Vivis2_Sig" SG_ 1461 HighCurrentIR1_2B 1;
BA_ "GenSigCycleTime" SG_ 1461 WhCounterCharge_2B 100;
BA_ "GenSigCycleTimeActive" SG_ 1461 WhCounterCharge_2B 100;
BA_ "GenSigStartValue" SG_ 1461 WhCounterCharge_2B 65535;
BA_ "GenSigMaxLatency" SG_ 1461 WhCounterCharge_2B 1015;
BA_ "Platform_Vivis2_Sig" SG_ 1461 WhCounterCharge_2B 1;
BA_ "GenSigCycleTime" SG_ 1461 WhCounterDischarge_2B 100;
BA_ "GenSigCycleTimeActive" SG_ 1461 WhCounterDischarge_2B 100;
BA_ "GenSigStartValue" SG_ 1461 WhCounterDischarge_2B 65535;
BA_ "GenSigMaxLatency" SG_ 1461 WhCounterDischarge_2B 1015;
BA_ "Platform_Vivis2_Sig" SG_ 1461 WhCounterDischarge_2B 1;
BA_ "GenSigCycleTime" SG_ 1459 HighCurrentIR1_3A 100;
BA_ "GenSigCycleTimeActive" SG_ 1459 HighCurrentIR1_3A 100;
BA_ "GenSigStartValue" SG_ 1459 HighCurrentIR1_3A 1023;
BA_ "GenSigMaxLatency" SG_ 1459 HighCurrentIR1_3A 1016;
BA_ "Platform_Vivis2_Sig" SG_ 1459 HighCurrentIR1_3A 1;
BA_ "GenSigCycleTime" SG_ 1459 WhCounterDischarge_3A 100;
BA_ "GenSigCycleTimeActive" SG_ 1459 WhCounterDischarge_3A 100;
BA_ "GenSigStartValue" SG_ 1459 WhCounterDischarge_3A 65535;
BA_ "GenSigMaxLatency" SG_ 1459 WhCounterDischarge_3A 1016;
BA_ "Platform_Vivis2_Sig" SG_ 1459 WhCounterDischarge_3A 1;
BA_ "GenSigCycleTime" SG_ 1459 WhCounterCharge_3A 100;
BA_ "GenSigCycleTimeActive" SG_ 1459 WhCounterCharge_3A 100;
BA_ "GenSigStartValue" SG_ 1459 WhCounterCharge_3A 65535;
BA_ "GenSigMaxLatency" SG_ 1459 WhCounterCharge_3A 1016;
BA_ "Platform_Vivis2_Sig" SG_ 1459 WhCounterCharge_3A 1;
BA_ "GenSigCycleTime" SG_ 1457 WhCounterCharge_3B 100;
BA_ "GenSigCycleTimeActive" SG_ 1457 WhCounterCharge_3B 100;
BA_ "GenSigStartValue" SG_ 1457 WhCounterCharge_3B 65535;
BA_ "GenSigMaxLatency" SG_ 1457 WhCounterCharge_3B 1017;
BA_ "Platform_Vivis2_Sig" SG_ 1457 WhCounterCharge_3B 1;
BA_ "GenSigCycleTime" SG_ 1457 HighCurrentIR1_3B 100;
BA_ "GenSigCycleTimeActive" SG_ 1457 HighCurrentIR1_3B 100;
BA_ "GenSigStartValue" SG_ 1457 HighCurrentIR1_3B 1023;
BA_ "GenSigMaxLatency" SG_ 1457 HighCurrentIR1_3B 1017;
BA_ "Platform_Vivis2_Sig" SG_ 1457 HighCurrentIR1_3B 1;
BA_ "GenSigCycleTime" SG_ 1457 WhCounterDischarge_3B 100;
BA_ "GenSigCycleTimeActive" SG_ 1457 WhCounterDischarge_3B 100;
BA_ "GenSigStartValue" SG_ 1457 WhCounterDischarge_3B 65535;
BA_ "GenSigMaxLatency" SG_ 1457 WhCounterDischarge_3B 1017;
BA_ "Platform_Vivis2_Sig" SG_ 1457 WhCounterDischarge_3B 1;
BA_ "GenSigCycleTime" SG_ 1455 HighCurrentIR2_1 100;
BA_ "GenSigCycleTimeActive" SG_ 1455 HighCurrentIR2_1 100;
BA_ "GenSigStartValue" SG_ 1455 HighCurrentIR2_1 1023;
BA_ "GenSigMaxLatency" SG_ 1455 HighCurrentIR2_1 1080;
BA_ "Platform_Vivis2_Sig" SG_ 1455 HighCurrentIR2_1 1;
BA_ "GenSigCycleTime" SG_ 1455 WhCounterDischarge2 100;
BA_ "GenSigCycleTimeActive" SG_ 1455 WhCounterDischarge2 100;
BA_ "GenSigStartValue" SG_ 1455 WhCounterDischarge2 65535;
BA_ "GenSigMaxLatency" SG_ 1455 WhCounterDischarge2 1018;
BA_ "Platform_Vivis2_Sig" SG_ 1455 WhCounterDischarge2 1;
BA_ "GenSigCycleTime" SG_ 1455 WhCounterCharge2 100;
BA_ "GenSigCycleTimeActive" SG_ 1455 WhCounterCharge2 100;
BA_ "GenSigStartValue" SG_ 1455 WhCounterCharge2 65535;
BA_ "GenSigMaxLatency" SG_ 1455 WhCounterCharge2 1018;
BA_ "Platform_Vivis2_Sig" SG_ 1455 WhCounterCharge2 1;
BA_ "GenSigCycleTime" SG_ 1453 DeepDischargestatus_1A 100;
BA_ "GenSigCycleTimeActive" SG_ 1453 DeepDischargestatus_1A 100;
BA_ "GenSigMaxLatency" SG_ 1453 DeepDischargestatus_1A 1020;
BA_ "Platform_Vivis2_Sig" SG_ 1453 DeepDischargestatus_1A 1;
BA_ "GenSigCycleTime" SG_ 1453 BatterySoCcrankLimit1_1A 100;
BA_ "GenSigCycleTimeActive" SG_ 1453 BatterySoCcrankLimit1_1A 100;
BA_ "GenSigStartValue" SG_ 1453 BatterySoCcrankLimit1_1A 255;
BA_ "GenSigMaxLatency" SG_ 1453 BatterySoCcrankLimit1_1A 1020;
BA_ "Platform_Vivis2_Sig" SG_ 1453 BatterySoCcrankLimit1_1A 1;
BA_ "GenSigCycleTime" SG_ 1453 BatteryTempCo_1A 100;
BA_ "GenSigCycleTimeActive" SG_ 1453 BatteryTempCo_1A 100;
BA_ "GenSigStartValue" SG_ 1453 BatteryTempCo_1A 255;
BA_ "GenSigMaxLatency" SG_ 1453 BatteryTempCo_1A 1020;
BA_ "Platform_Vivis2_Sig" SG_ 1453 BatteryTempCo_1A 1;
BA_ "GenSigCycleTime" SG_ 1453 BatterySOCTrustLevel_stat1_1A 100;
BA_ "GenSigCycleTimeActive" SG_ 1453 BatterySOCTrustLevel_stat1_1A 100;
BA_ "GenSigStartValue" SG_ 1453 BatterySOCTrustLevel_stat1_1A 15;
BA_ "GenSigMaxLatency" SG_ 1453 BatterySOCTrustLevel_stat1_1A 1020;
BA_ "Platform_Vivis2_Sig" SG_ 1453 BatterySOCTrustLevel_stat1_1A 1;
BA_ "GenSigCycleTime" SG_ 1453 Endofchargestatus1_1A 100;
BA_ "GenSigCycleTimeActive" SG_ 1453 Endofchargestatus1_1A 100;
BA_ "GenSigMaxLatency" SG_ 1453 Endofchargestatus1_1A 1020;
BA_ "Platform_Vivis2_Sig" SG_ 1453 Endofchargestatus1_1A 1;
BA_ "GenSigCycleTime" SG_ 1453 BatteryReconnectionDetect_1A 100;
BA_ "GenSigCycleTimeActive" SG_ 1453 BatteryReconnectionDetect_1A 100;
BA_ "GenSigMaxLatency" SG_ 1453 BatteryReconnectionDetect_1A 1020;
BA_ "Platform_Vivis2_Sig" SG_ 1453 BatteryReconnectionDetect_1A 1;
BA_ "GenSigCycleTime" SG_ 1453 BatterySOHTrustLevel_stat1_1A 100;
BA_ "GenSigCycleTimeActive" SG_ 1453 BatterySOHTrustLevel_stat1_1A 100;
BA_ "GenSigStartValue" SG_ 1453 BatterySOHTrustLevel_stat1_1A 15;
BA_ "GenSigMaxLatency" SG_ 1453 BatterySOHTrustLevel_stat1_1A 1020;
BA_ "Platform_Vivis2_Sig" SG_ 1453 BatterySOHTrustLevel_stat1_1A 1;
BA_ "GenSigCycleTime" SG_ 1453 EndOfDischargeStatus1_1A 100;
BA_ "GenSigCycleTimeActive" SG_ 1453 EndOfDischargeStatus1_1A 100;
BA_ "GenSigMaxLatency" SG_ 1453 EndOfDischargeStatus1_1A 1020;
BA_ "Platform_Vivis2_Sig" SG_ 1453 EndOfDischargeStatus1_1A 1;
BA_ "GenSigCycleTime" SG_ 1453 BatterySOHPower1_1A 100;
BA_ "GenSigCycleTimeActive" SG_ 1453 BatterySOHPower1_1A 100;
BA_ "GenSigStartValue" SG_ 1453 BatterySOHPower1_1A 255;
BA_ "GenSigMaxLatency" SG_ 1453 BatterySOHPower1_1A 1020;
BA_ "Platform_Vivis2_Sig" SG_ 1453 BatterySOHPower1_1A 1;
BA_ "GenSigCycleTime" SG_ 1453 BatteryExchangeDetect_1A 100;
BA_ "GenSigCycleTimeActive" SG_ 1453 BatteryExchangeDetect_1A 100;
BA_ "GenSigStartValue" SG_ 1453 BatteryExchangeDetect_1A 7;
BA_ "GenSigMaxLatency" SG_ 1453 BatteryExchangeDetect_1A 1020;
BA_ "Platform_Vivis2_Sig" SG_ 1453 BatteryExchangeDetect_1A 1;
BA_ "GenSigCycleTime" SG_ 1453 BatterySOHCapa1_1A 100;
BA_ "GenSigCycleTimeActive" SG_ 1453 BatterySOHCapa1_1A 100;
BA_ "GenSigStartValue" SG_ 1453 BatterySOHCapa1_1A 255;
BA_ "GenSigMaxLatency" SG_ 1453 BatterySOHCapa1_1A 1020;
BA_ "Platform_Vivis2_Sig" SG_ 1453 BatterySOHCapa1_1A 1;
BA_ "GenSigCycleTime" SG_ 1453 BatterySOHPowerTrustLevel1_1A 100;
BA_ "GenSigCycleTimeActive" SG_ 1453 BatterySOHPowerTrustLevel1_1A 100;
BA_ "GenSigStartValue" SG_ 1453 BatterySOHPowerTrustLevel1_1A 15;
BA_ "GenSigMaxLatency" SG_ 1453 BatterySOHPowerTrustLevel1_1A 1020;
BA_ "Platform_Vivis2_Sig" SG_ 1453 BatterySOHPowerTrustLevel1_1A 1;
BA_ "GenSigCycleTime" SG_ 1451 BatterySoCcrankLimit1_1B 100;
BA_ "GenSigCycleTimeActive" SG_ 1451 BatterySoCcrankLimit1_1B 100;
BA_ "GenSigStartValue" SG_ 1451 BatterySoCcrankLimit1_1B 255;
BA_ "GenSigMaxLatency" SG_ 1451 BatterySoCcrankLimit1_1B 1030;
BA_ "Platform_Vivis2_Sig" SG_ 1451 BatterySoCcrankLimit1_1B 1;
BA_ "GenSigCycleTime" SG_ 1451 BatterySOHTrustLevel_stat1_1B 100;
BA_ "GenSigCycleTimeActive" SG_ 1451 BatterySOHTrustLevel_stat1_1B 100;
BA_ "GenSigStartValue" SG_ 1451 BatterySOHTrustLevel_stat1_1B 15;
BA_ "GenSigMaxLatency" SG_ 1451 BatterySOHTrustLevel_stat1_1B 1030;
BA_ "Platform_Vivis2_Sig" SG_ 1451 BatterySOHTrustLevel_stat1_1B 1;
BA_ "GenSigCycleTime" SG_ 1451 Endofchargestatus1_1B 100;
BA_ "GenSigCycleTimeActive" SG_ 1451 Endofchargestatus1_1B 100;
BA_ "GenSigMaxLatency" SG_ 1451 Endofchargestatus1_1B 1030;
BA_ "Platform_Vivis2_Sig" SG_ 1451 Endofchargestatus1_1B 1;
BA_ "GenSigCycleTime" SG_ 1451 BatteryExchangeDetect_1B 100;
BA_ "GenSigCycleTimeActive" SG_ 1451 BatteryExchangeDetect_1B 100;
BA_ "GenSigStartValue" SG_ 1451 BatteryExchangeDetect_1B 7;
BA_ "GenSigMaxLatency" SG_ 1451 BatteryExchangeDetect_1B 1030;
BA_ "Platform_Vivis2_Sig" SG_ 1451 BatteryExchangeDetect_1B 1;
BA_ "GenSigCycleTime" SG_ 1451 BatterySOCTrustLevel_stat1_1B 100;
BA_ "GenSigCycleTimeActive" SG_ 1451 BatterySOCTrustLevel_stat1_1B 100;
BA_ "GenSigStartValue" SG_ 1451 BatterySOCTrustLevel_stat1_1B 15;
BA_ "GenSigMaxLatency" SG_ 1451 BatterySOCTrustLevel_stat1_1B 1030;
BA_ "Platform_Vivis2_Sig" SG_ 1451 BatterySOCTrustLevel_stat1_1B 1;
BA_ "GenSigCycleTime" SG_ 1451 BatterySOHCapa1_1B 100;
BA_ "GenSigCycleTimeActive" SG_ 1451 BatterySOHCapa1_1B 100;
BA_ "GenSigStartValue" SG_ 1451 BatterySOHCapa1_1B 255;
BA_ "GenSigMaxLatency" SG_ 1451 BatterySOHCapa1_1B 1030;
BA_ "Platform_Vivis2_Sig" SG_ 1451 BatterySOHCapa1_1B 1;
BA_ "GenSigCycleTime" SG_ 1451 BatteryReconnectionDetect_1B 100;
BA_ "GenSigCycleTimeActive" SG_ 1451 BatteryReconnectionDetect_1B 100;
BA_ "GenSigMaxLatency" SG_ 1451 BatteryReconnectionDetect_1B 1030;
BA_ "Platform_Vivis2_Sig" SG_ 1451 BatteryReconnectionDetect_1B 1;
BA_ "GenSigCycleTime" SG_ 1451 EndOfDischargeStatus1_1B 100;
BA_ "GenSigCycleTimeActive" SG_ 1451 EndOfDischargeStatus1_1B 100;
BA_ "GenSigMaxLatency" SG_ 1451 EndOfDischargeStatus1_1B 1030;
BA_ "Platform_Vivis2_Sig" SG_ 1451 EndOfDischargeStatus1_1B 1;
BA_ "GenSigCycleTime" SG_ 1451 DeepDischargestatus_1B 100;
BA_ "GenSigCycleTimeActive" SG_ 1451 DeepDischargestatus_1B 100;
BA_ "GenSigMaxLatency" SG_ 1451 DeepDischargestatus_1B 1030;
BA_ "Platform_Vivis2_Sig" SG_ 1451 DeepDischargestatus_1B 1;
BA_ "GenSigCycleTime" SG_ 1451 BatteryTempCo_1B 100;
BA_ "GenSigCycleTimeActive" SG_ 1451 BatteryTempCo_1B 100;
BA_ "GenSigStartValue" SG_ 1451 BatteryTempCo_1B 255;
BA_ "GenSigMaxLatency" SG_ 1451 BatteryTempCo_1B 1030;
BA_ "Platform_Vivis2_Sig" SG_ 1451 BatteryTempCo_1B 1;
BA_ "GenSigCycleTime" SG_ 1451 BatterySOHPower1_1B 100;
BA_ "GenSigCycleTimeActive" SG_ 1451 BatterySOHPower1_1B 100;
BA_ "GenSigStartValue" SG_ 1451 BatterySOHPower1_1B 255;
BA_ "GenSigMaxLatency" SG_ 1451 BatterySOHPower1_1B 1030;
BA_ "Platform_Vivis2_Sig" SG_ 1451 BatterySOHPower1_1B 1;
BA_ "GenSigCycleTime" SG_ 1451 BatterySOHPowerTrustLevel1_1B 100;
BA_ "GenSigCycleTimeActive" SG_ 1451 BatterySOHPowerTrustLevel1_1B 100;
BA_ "GenSigStartValue" SG_ 1451 BatterySOHPowerTrustLevel1_1B 15;
BA_ "GenSigMaxLatency" SG_ 1451 BatterySOHPowerTrustLevel1_1B 1030;
BA_ "Platform_Vivis2_Sig" SG_ 1451 BatterySOHPowerTrustLevel1_1B 1;
BA_ "GenSigCycleTime" SG_ 1449 BatterySOHTrustLevel_stat1_2A 100;
BA_ "GenSigCycleTimeActive" SG_ 1449 BatterySOHTrustLevel_stat1_2A 100;
BA_ "GenSigStartValue" SG_ 1449 BatterySOHTrustLevel_stat1_2A 15;
BA_ "GenSigMaxLatency" SG_ 1449 BatterySOHTrustLevel_stat1_2A 1040;
BA_ "Platform_Vivis2_Sig" SG_ 1449 BatterySOHTrustLevel_stat1_2A 1;
BA_ "GenSigCycleTime" SG_ 1449 BatterySOHPower1_2A 100;
BA_ "GenSigCycleTimeActive" SG_ 1449 BatterySOHPower1_2A 100;
BA_ "GenSigStartValue" SG_ 1449 BatterySOHPower1_2A 255;
BA_ "GenSigMaxLatency" SG_ 1449 BatterySOHPower1_2A 1040;
BA_ "Platform_Vivis2_Sig" SG_ 1449 BatterySOHPower1_2A 1;
BA_ "GenSigCycleTime" SG_ 1449 BatterySOHPowerTrustLevel1_2A 100;
BA_ "GenSigCycleTimeActive" SG_ 1449 BatterySOHPowerTrustLevel1_2A 100;
BA_ "GenSigStartValue" SG_ 1449 BatterySOHPowerTrustLevel1_2A 15;
BA_ "GenSigMaxLatency" SG_ 1449 BatterySOHPowerTrustLevel1_2A 1040;
BA_ "Platform_Vivis2_Sig" SG_ 1449 BatterySOHPowerTrustLevel1_2A 1;
BA_ "GenSigCycleTime" SG_ 1449 BatterySOHCapa1_2A 100;
BA_ "GenSigCycleTimeActive" SG_ 1449 BatterySOHCapa1_2A 100;
BA_ "GenSigStartValue" SG_ 1449 BatterySOHCapa1_2A 255;
BA_ "GenSigMaxLatency" SG_ 1449 BatterySOHCapa1_2A 1040;
BA_ "Platform_Vivis2_Sig" SG_ 1449 BatterySOHCapa1_2A 1;
BA_ "GenSigCycleTime" SG_ 1449 BatteryTempCo_2A 100;
BA_ "GenSigCycleTimeActive" SG_ 1449 BatteryTempCo_2A 100;
BA_ "GenSigStartValue" SG_ 1449 BatteryTempCo_2A 255;
BA_ "GenSigMaxLatency" SG_ 1449 BatteryTempCo_2A 1040;
BA_ "Platform_Vivis2_Sig" SG_ 1449 BatteryTempCo_2A 1;
BA_ "GenSigCycleTime" SG_ 1449 EndOfDischargeStatus1_2A 100;
BA_ "GenSigCycleTimeActive" SG_ 1449 EndOfDischargeStatus1_2A 100;
BA_ "GenSigMaxLatency" SG_ 1449 EndOfDischargeStatus1_2A 1040;
BA_ "Platform_Vivis2_Sig" SG_ 1449 EndOfDischargeStatus1_2A 1;
BA_ "GenSigCycleTime" SG_ 1449 BatterySoCcrankLimit1_2A 100;
BA_ "GenSigCycleTimeActive" SG_ 1449 BatterySoCcrankLimit1_2A 100;
BA_ "GenSigStartValue" SG_ 1449 BatterySoCcrankLimit1_2A 255;
BA_ "GenSigMaxLatency" SG_ 1449 BatterySoCcrankLimit1_2A 1040;
BA_ "Platform_Vivis2_Sig" SG_ 1449 BatterySoCcrankLimit1_2A 1;
BA_ "GenSigCycleTime" SG_ 1449 BatterySOCTrustLevel_stat1_2A 100;
BA_ "GenSigCycleTimeActive" SG_ 1449 BatterySOCTrustLevel_stat1_2A 100;
BA_ "GenSigStartValue" SG_ 1449 BatterySOCTrustLevel_stat1_2A 15;
BA_ "GenSigMaxLatency" SG_ 1449 BatterySOCTrustLevel_stat1_2A 1040;
BA_ "Platform_Vivis2_Sig" SG_ 1449 BatterySOCTrustLevel_stat1_2A 1;
BA_ "GenSigCycleTime" SG_ 1449 BatteryExchangeDetect_2A 100;
BA_ "GenSigCycleTimeActive" SG_ 1449 BatteryExchangeDetect_2A 100;
BA_ "GenSigStartValue" SG_ 1449 BatteryExchangeDetect_2A 7;
BA_ "GenSigMaxLatency" SG_ 1449 BatteryExchangeDetect_2A 1040;
BA_ "Platform_Vivis2_Sig" SG_ 1449 BatteryExchangeDetect_2A 1;
BA_ "GenSigCycleTime" SG_ 1449 DeepDischargestatus_2A 100;
BA_ "GenSigCycleTimeActive" SG_ 1449 DeepDischargestatus_2A 100;
BA_ "GenSigMaxLatency" SG_ 1449 DeepDischargestatus_2A 1040;
BA_ "Platform_Vivis2_Sig" SG_ 1449 DeepDischargestatus_2A 1;
BA_ "GenSigCycleTime" SG_ 1449 BatteryReconnectionDetect_2A 100;
BA_ "GenSigCycleTimeActive" SG_ 1449 BatteryReconnectionDetect_2A 100;
BA_ "GenSigMaxLatency" SG_ 1449 BatteryReconnectionDetect_2A 1040;
BA_ "Platform_Vivis2_Sig" SG_ 1449 BatteryReconnectionDetect_2A 1;
BA_ "GenSigCycleTime" SG_ 1449 Endofchargestatus1_2A 100;
BA_ "GenSigCycleTimeActive" SG_ 1449 Endofchargestatus1_2A 100;
BA_ "GenSigMaxLatency" SG_ 1449 Endofchargestatus1_2A 1040;
BA_ "Platform_Vivis2_Sig" SG_ 1449 Endofchargestatus1_2A 1;
BA_ "GenSigCycleTime" SG_ 1447 BatteryExchangeDetect_2B 100;
BA_ "GenSigCycleTimeActive" SG_ 1447 BatteryExchangeDetect_2B 100;
BA_ "GenSigStartValue" SG_ 1447 BatteryExchangeDetect_2B 7;
BA_ "GenSigMaxLatency" SG_ 1447 BatteryExchangeDetect_2B 1050;
BA_ "Platform_Vivis2_Sig" SG_ 1447 BatteryExchangeDetect_2B 1;
BA_ "GenSigCycleTime" SG_ 1447 BatterySOHPowerTrustLevel1_2B 100;
BA_ "GenSigCycleTimeActive" SG_ 1447 BatterySOHPowerTrustLevel1_2B 100;
BA_ "GenSigStartValue" SG_ 1447 BatterySOHPowerTrustLevel1_2B 15;
BA_ "GenSigMaxLatency" SG_ 1447 BatterySOHPowerTrustLevel1_2B 1050;
BA_ "Platform_Vivis2_Sig" SG_ 1447 BatterySOHPowerTrustLevel1_2B 1;
BA_ "GenSigCycleTime" SG_ 1447 Endofchargestatus1_2B 100;
BA_ "GenSigCycleTimeActive" SG_ 1447 Endofchargestatus1_2B 100;
BA_ "GenSigMaxLatency" SG_ 1447 Endofchargestatus1_2B 1050;
BA_ "Platform_Vivis2_Sig" SG_ 1447 Endofchargestatus1_2B 1;
BA_ "GenSigCycleTime" SG_ 1447 BatteryTempCo_2B 100;
BA_ "GenSigCycleTimeActive" SG_ 1447 BatteryTempCo_2B 100;
BA_ "GenSigStartValue" SG_ 1447 BatteryTempCo_2B 255;
BA_ "GenSigMaxLatency" SG_ 1447 BatteryTempCo_2B 1050;
BA_ "Platform_Vivis2_Sig" SG_ 1447 BatteryTempCo_2B 1;
BA_ "GenSigCycleTime" SG_ 1447 BatterySOHCapa1_2B 100;
BA_ "GenSigCycleTimeActive" SG_ 1447 BatterySOHCapa1_2B 100;
BA_ "GenSigStartValue" SG_ 1447 BatterySOHCapa1_2B 255;
BA_ "GenSigMaxLatency" SG_ 1447 BatterySOHCapa1_2B 1050;
BA_ "Platform_Vivis2_Sig" SG_ 1447 BatterySOHCapa1_2B 1;
BA_ "GenSigCycleTime" SG_ 1447 BatterySOHPower1_2B 100;
BA_ "GenSigCycleTimeActive" SG_ 1447 BatterySOHPower1_2B 100;
BA_ "GenSigStartValue" SG_ 1447 BatterySOHPower1_2B 255;
BA_ "GenSigMaxLatency" SG_ 1447 BatterySOHPower1_2B 1050;
BA_ "Platform_Vivis2_Sig" SG_ 1447 BatterySOHPower1_2B 1;
BA_ "GenSigCycleTime" SG_ 1447 BatteryReconnectionDetect_2B 100;
BA_ "GenSigCycleTimeActive" SG_ 1447 BatteryReconnectionDetect_2B 100;
BA_ "GenSigMaxLatency" SG_ 1447 BatteryReconnectionDetect_2B 1050;
BA_ "Platform_Vivis2_Sig" SG_ 1447 BatteryReconnectionDetect_2B 1;
BA_ "GenSigCycleTime" SG_ 1447 BatterySOHTrustLevel_stat1_2B 100;
BA_ "GenSigCycleTimeActive" SG_ 1447 BatterySOHTrustLevel_stat1_2B 100;
BA_ "GenSigStartValue" SG_ 1447 BatterySOHTrustLevel_stat1_2B 15;
BA_ "GenSigMaxLatency" SG_ 1447 BatterySOHTrustLevel_stat1_2B 1050;
BA_ "Platform_Vivis2_Sig" SG_ 1447 BatterySOHTrustLevel_stat1_2B 1;
BA_ "GenSigCycleTime" SG_ 1447 BatterySoCcrankLimit1_2B 100;
BA_ "GenSigCycleTimeActive" SG_ 1447 BatterySoCcrankLimit1_2B 100;
BA_ "GenSigStartValue" SG_ 1447 BatterySoCcrankLimit1_2B 255;
BA_ "GenSigMaxLatency" SG_ 1447 BatterySoCcrankLimit1_2B 1050;
BA_ "Platform_Vivis2_Sig" SG_ 1447 BatterySoCcrankLimit1_2B 1;
BA_ "GenSigCycleTime" SG_ 1447 DeepDischargestatus_2B 100;
BA_ "GenSigCycleTimeActive" SG_ 1447 DeepDischargestatus_2B 100;
BA_ "GenSigMaxLatency" SG_ 1447 DeepDischargestatus_2B 1050;
BA_ "Platform_Vivis2_Sig" SG_ 1447 DeepDischargestatus_2B 1;
BA_ "GenSigCycleTime" SG_ 1447 EndOfDischargeStatus1_2B 100;
BA_ "GenSigCycleTimeActive" SG_ 1447 EndOfDischargeStatus1_2B 100;
BA_ "GenSigMaxLatency" SG_ 1447 EndOfDischargeStatus1_2B 1050;
BA_ "Platform_Vivis2_Sig" SG_ 1447 EndOfDischargeStatus1_2B 1;
BA_ "GenSigCycleTime" SG_ 1447 BatterySOCTrustLevel_stat1_2B 100;
BA_ "GenSigCycleTimeActive" SG_ 1447 BatterySOCTrustLevel_stat1_2B 100;
BA_ "GenSigStartValue" SG_ 1447 BatterySOCTrustLevel_stat1_2B 15;
BA_ "GenSigMaxLatency" SG_ 1447 BatterySOCTrustLevel_stat1_2B 1050;
BA_ "Platform_Vivis2_Sig" SG_ 1447 BatterySOCTrustLevel_stat1_2B 1;
BA_ "GenSigCycleTime" SG_ 1445 BatterySOHPowerTrustLevel1_3A 100;
BA_ "GenSigCycleTimeActive" SG_ 1445 BatterySOHPowerTrustLevel1_3A 100;
BA_ "GenSigStartValue" SG_ 1445 BatterySOHPowerTrustLevel1_3A 15;
BA_ "GenSigMaxLatency" SG_ 1445 BatterySOHPowerTrustLevel1_3A 1060;
BA_ "Platform_Vivis2_Sig" SG_ 1445 BatterySOHPowerTrustLevel1_3A 1;
BA_ "GenSigCycleTime" SG_ 1445 BatteryExchangeDetect_3A 100;
BA_ "GenSigCycleTimeActive" SG_ 1445 BatteryExchangeDetect_3A 100;
BA_ "GenSigStartValue" SG_ 1445 BatteryExchangeDetect_3A 7;
BA_ "GenSigMaxLatency" SG_ 1445 BatteryExchangeDetect_3A 1060;
BA_ "Platform_Vivis2_Sig" SG_ 1445 BatteryExchangeDetect_3A 1;
BA_ "GenSigCycleTime" SG_ 1445 Endofchargestatus1_3A 100;
BA_ "GenSigCycleTimeActive" SG_ 1445 Endofchargestatus1_3A 100;
BA_ "GenSigMaxLatency" SG_ 1445 Endofchargestatus1_3A 1060;
BA_ "Platform_Vivis2_Sig" SG_ 1445 Endofchargestatus1_3A 1;
BA_ "GenSigCycleTime" SG_ 1445 BatteryTempCo_3A 100;
BA_ "GenSigCycleTimeActive" SG_ 1445 BatteryTempCo_3A 100;
BA_ "GenSigStartValue" SG_ 1445 BatteryTempCo_3A 255;
BA_ "GenSigMaxLatency" SG_ 1445 BatteryTempCo_3A 1060;
BA_ "Platform_Vivis2_Sig" SG_ 1445 BatteryTempCo_3A 1;
BA_ "GenSigCycleTime" SG_ 1445 BatterySoCcrankLimit1_3A 100;
BA_ "GenSigCycleTimeActive" SG_ 1445 BatterySoCcrankLimit1_3A 100;
BA_ "GenSigStartValue" SG_ 1445 BatterySoCcrankLimit1_3A 255;
BA_ "GenSigMaxLatency" SG_ 1445 BatterySoCcrankLimit1_3A 1060;
BA_ "Platform_Vivis2_Sig" SG_ 1445 BatterySoCcrankLimit1_3A 1;
BA_ "GenSigCycleTime" SG_ 1445 BatteryReconnectionDetect_3A 100;
BA_ "GenSigCycleTimeActive" SG_ 1445 BatteryReconnectionDetect_3A 100;
BA_ "GenSigMaxLatency" SG_ 1445 BatteryReconnectionDetect_3A 1060;
BA_ "Platform_Vivis2_Sig" SG_ 1445 BatteryReconnectionDetect_3A 1;
BA_ "GenSigCycleTime" SG_ 1445 BatterySOHTrustLevel_stat1_3A 100;
BA_ "GenSigCycleTimeActive" SG_ 1445 BatterySOHTrustLevel_stat1_3A 100;
BA_ "GenSigStartValue" SG_ 1445 BatterySOHTrustLevel_stat1_3A 15;
BA_ "GenSigMaxLatency" SG_ 1445 BatterySOHTrustLevel_stat1_3A 1060;
BA_ "Platform_Vivis2_Sig" SG_ 1445 BatterySOHTrustLevel_stat1_3A 1;
BA_ "GenSigCycleTime" SG_ 1445 DeepDischargestatus_3A 100;
BA_ "GenSigCycleTimeActive" SG_ 1445 DeepDischargestatus_3A 100;
BA_ "GenSigMaxLatency" SG_ 1445 DeepDischargestatus_3A 1060;
BA_ "Platform_Vivis2_Sig" SG_ 1445 DeepDischargestatus_3A 1;
BA_ "GenSigCycleTime" SG_ 1445 BatterySOHPower1_3A 100;
BA_ "GenSigCycleTimeActive" SG_ 1445 BatterySOHPower1_3A 100;
BA_ "GenSigStartValue" SG_ 1445 BatterySOHPower1_3A 255;
BA_ "GenSigMaxLatency" SG_ 1445 BatterySOHPower1_3A 1060;
BA_ "Platform_Vivis2_Sig" SG_ 1445 BatterySOHPower1_3A 1;
BA_ "GenSigCycleTime" SG_ 1445 BatterySOCTrustLevel_stat1_3A 100;
BA_ "GenSigCycleTimeActive" SG_ 1445 BatterySOCTrustLevel_stat1_3A 100;
BA_ "GenSigStartValue" SG_ 1445 BatterySOCTrustLevel_stat1_3A 15;
BA_ "GenSigMaxLatency" SG_ 1445 BatterySOCTrustLevel_stat1_3A 1060;
BA_ "Platform_Vivis2_Sig" SG_ 1445 BatterySOCTrustLevel_stat1_3A 1;
BA_ "GenSigCycleTime" SG_ 1445 EndOfDischargeStatus1_3A 100;
BA_ "GenSigCycleTimeActive" SG_ 1445 EndOfDischargeStatus1_3A 100;
BA_ "GenSigMaxLatency" SG_ 1445 EndOfDischargeStatus1_3A 1060;
BA_ "Platform_Vivis2_Sig" SG_ 1445 EndOfDischargeStatus1_3A 1;
BA_ "GenSigCycleTime" SG_ 1445 BatterySOHCapa1_3A 100;
BA_ "GenSigCycleTimeActive" SG_ 1445 BatterySOHCapa1_3A 100;
BA_ "GenSigStartValue" SG_ 1445 BatterySOHCapa1_3A 255;
BA_ "GenSigMaxLatency" SG_ 1445 BatterySOHCapa1_3A 1060;
BA_ "Platform_Vivis2_Sig" SG_ 1445 BatterySOHCapa1_3A 1;
BA_ "GenSigCycleTime" SG_ 1443 BatteryTempCo_3B 100;
BA_ "GenSigCycleTimeActive" SG_ 1443 BatteryTempCo_3B 100;
BA_ "GenSigStartValue" SG_ 1443 BatteryTempCo_3B 255;
BA_ "GenSigMaxLatency" SG_ 1443 BatteryTempCo_3B 1070;
BA_ "Platform_Vivis2_Sig" SG_ 1443 BatteryTempCo_3B 1;
BA_ "GenSigCycleTime" SG_ 1443 BatterySoCcrankLimit1_3B 100;
BA_ "GenSigCycleTimeActive" SG_ 1443 BatterySoCcrankLimit1_3B 100;
BA_ "GenSigStartValue" SG_ 1443 BatterySoCcrankLimit1_3B 255;
BA_ "GenSigMaxLatency" SG_ 1443 BatterySoCcrankLimit1_3B 1070;
BA_ "Platform_Vivis2_Sig" SG_ 1443 BatterySoCcrankLimit1_3B 1;
BA_ "GenSigCycleTime" SG_ 1443 BatterySOHPower1_3B 100;
BA_ "GenSigCycleTimeActive" SG_ 1443 BatterySOHPower1_3B 100;
BA_ "GenSigStartValue" SG_ 1443 BatterySOHPower1_3B 255;
BA_ "GenSigMaxLatency" SG_ 1443 BatterySOHPower1_3B 1070;
BA_ "Platform_Vivis2_Sig" SG_ 1443 BatterySOHPower1_3B 1;
BA_ "GenSigCycleTime" SG_ 1443 BatterySOHCapa1_3B 100;
BA_ "GenSigCycleTimeActive" SG_ 1443 BatterySOHCapa1_3B 100;
BA_ "GenSigStartValue" SG_ 1443 BatterySOHCapa1_3B 255;
BA_ "GenSigMaxLatency" SG_ 1443 BatterySOHCapa1_3B 1070;
BA_ "Platform_Vivis2_Sig" SG_ 1443 BatterySOHCapa1_3B 1;
BA_ "GenSigCycleTime" SG_ 1443 EndOfDischargeStatus1_3B 100;
BA_ "GenSigCycleTimeActive" SG_ 1443 EndOfDischargeStatus1_3B 100;
BA_ "GenSigMaxLatency" SG_ 1443 EndOfDischargeStatus1_3B 1070;
BA_ "Platform_Vivis2_Sig" SG_ 1443 EndOfDischargeStatus1_3B 1;
BA_ "GenSigCycleTime" SG_ 1443 BatterySOCTrustLevel_stat1_3B 100;
BA_ "GenSigCycleTimeActive" SG_ 1443 BatterySOCTrustLevel_stat1_3B 100;
BA_ "GenSigStartValue" SG_ 1443 BatterySOCTrustLevel_stat1_3B 15;
BA_ "GenSigMaxLatency" SG_ 1443 BatterySOCTrustLevel_stat1_3B 1070;
BA_ "Platform_Vivis2_Sig" SG_ 1443 BatterySOCTrustLevel_stat1_3B 1;
BA_ "GenSigCycleTime" SG_ 1443 BatteryReconnectionDetect_3B 100;
BA_ "GenSigCycleTimeActive" SG_ 1443 BatteryReconnectionDetect_3B 100;
BA_ "GenSigMaxLatency" SG_ 1443 BatteryReconnectionDetect_3B 1070;
BA_ "Platform_Vivis2_Sig" SG_ 1443 BatteryReconnectionDetect_3B 1;
BA_ "GenSigCycleTime" SG_ 1443 DeepDischargestatus_3B 100;
BA_ "GenSigCycleTimeActive" SG_ 1443 DeepDischargestatus_3B 100;
BA_ "GenSigMaxLatency" SG_ 1443 DeepDischargestatus_3B 1070;
BA_ "Platform_Vivis2_Sig" SG_ 1443 DeepDischargestatus_3B 1;
BA_ "GenSigCycleTime" SG_ 1443 BatterySOHPowerTrustLevel1_3B 100;
BA_ "GenSigCycleTimeActive" SG_ 1443 BatterySOHPowerTrustLevel1_3B 100;
BA_ "GenSigStartValue" SG_ 1443 BatterySOHPowerTrustLevel1_3B 15;
BA_ "GenSigMaxLatency" SG_ 1443 BatterySOHPowerTrustLevel1_3B 1070;
BA_ "Platform_Vivis2_Sig" SG_ 1443 BatterySOHPowerTrustLevel1_3B 1;
BA_ "GenSigCycleTime" SG_ 1443 BatterySOHTrustLevel_stat1_3B 100;
BA_ "GenSigCycleTimeActive" SG_ 1443 BatterySOHTrustLevel_stat1_3B 100;
BA_ "GenSigStartValue" SG_ 1443 BatterySOHTrustLevel_stat1_3B 15;
BA_ "GenSigMaxLatency" SG_ 1443 BatterySOHTrustLevel_stat1_3B 1070;
BA_ "Platform_Vivis2_Sig" SG_ 1443 BatterySOHTrustLevel_stat1_3B 1;
BA_ "GenSigCycleTime" SG_ 1443 BatteryExchangeDetect_3B 100;
BA_ "GenSigCycleTimeActive" SG_ 1443 BatteryExchangeDetect_3B 100;
BA_ "GenSigStartValue" SG_ 1443 BatteryExchangeDetect_3B 7;
BA_ "GenSigMaxLatency" SG_ 1443 BatteryExchangeDetect_3B 1070;
BA_ "Platform_Vivis2_Sig" SG_ 1443 BatteryExchangeDetect_3B 1;
BA_ "GenSigCycleTime" SG_ 1443 Endofchargestatus1_3B 100;
BA_ "GenSigCycleTimeActive" SG_ 1443 Endofchargestatus1_3B 100;
BA_ "GenSigMaxLatency" SG_ 1443 Endofchargestatus1_3B 1070;
BA_ "Platform_Vivis2_Sig" SG_ 1443 Endofchargestatus1_3B 1;
BA_ "GenSigCycleTime" SG_ 1441 BatterySOCTrustLevel_stat2_1 100;
BA_ "GenSigCycleTimeActive" SG_ 1441 BatterySOCTrustLevel_stat2_1 100;
BA_ "GenSigStartValue" SG_ 1441 BatterySOCTrustLevel_stat2_1 15;
BA_ "GenSigMaxLatency" SG_ 1441 BatterySOCTrustLevel_stat2_1 1080;
BA_ "Platform_Vivis2_Sig" SG_ 1441 BatterySOCTrustLevel_stat2_1 1;
BA_ "GenSigCycleTime" SG_ 1441 BatterySOCTLWeak_ISig_4 100;
BA_ "GenSigCycleTimeActive" SG_ 1441 BatterySOCTLWeak_ISig_4 100;
BA_ "GenSigStartValue" SG_ 1441 BatterySOCTLWeak_ISig_4 15;
BA_ "Platform_Vivis2_Sig" SG_ 1441 BatterySOCTLWeak_ISig_4 1;
BA_ "GenSigCycleTime" SG_ 1441 BatterySOHCapaTLWeak 100;
BA_ "GenSigCycleTimeActive" SG_ 1441 BatterySOHCapaTLWeak 100;
BA_ "GenSigStartValue" SG_ 1441 BatterySOHCapaTLWeak 15;
BA_ "Platform_Vivis2_Sig" SG_ 1441 BatterySOHCapaTLWeak 1;
BA_ "GenSigCycleTime" SG_ 1441 BatterySOHTrustLevel_stat2_1 100;
BA_ "GenSigCycleTimeActive" SG_ 1441 BatterySOHTrustLevel_stat2_1 100;
BA_ "GenSigStartValue" SG_ 1441 BatterySOHTrustLevel_stat2_1 15;
BA_ "GenSigMaxLatency" SG_ 1441 BatterySOHTrustLevel_stat2_1 1080;
BA_ "Platform_Vivis2_Sig" SG_ 1441 BatterySOHTrustLevel_stat2_1 1;
BA_ "GenSigCycleTime" SG_ 1441 Endofchargestatus2_1 100;
BA_ "GenSigCycleTimeActive" SG_ 1441 Endofchargestatus2_1 100;
BA_ "GenSigMaxLatency" SG_ 1441 Endofchargestatus2_1 1080;
BA_ "Platform_Vivis2_Sig" SG_ 1441 Endofchargestatus2_1 1;
BA_ "GenSigCycleTime" SG_ 1441 BatterySOHPower2_1 100;
BA_ "GenSigCycleTimeActive" SG_ 1441 BatterySOHPower2_1 100;
BA_ "GenSigStartValue" SG_ 1441 BatterySOHPower2_1 255;
BA_ "GenSigMaxLatency" SG_ 1441 BatterySOHPower2_1 1080;
BA_ "Platform_Vivis2_Sig" SG_ 1441 BatterySOHPower2_1 1;
BA_ "GenSigCycleTime" SG_ 1441 BatterySOHPowerTrustLevel2_1 100;
BA_ "GenSigCycleTimeActive" SG_ 1441 BatterySOHPowerTrustLevel2_1 100;
BA_ "GenSigStartValue" SG_ 1441 BatterySOHPowerTrustLevel2_1 15;
BA_ "GenSigMaxLatency" SG_ 1441 BatterySOHPowerTrustLevel2_1 1080;
BA_ "Platform_Vivis2_Sig" SG_ 1441 BatterySOHPowerTrustLevel2_1 1;
BA_ "GenSigCycleTime" SG_ 1441 EndOfDischargeStatus2_1 100;
BA_ "GenSigCycleTimeActive" SG_ 1441 EndOfDischargeStatus2_1 100;
BA_ "GenSigMaxLatency" SG_ 1441 EndOfDischargeStatus2_1 1080;
BA_ "Platform_Vivis2_Sig" SG_ 1441 EndOfDischargeStatus2_1 1;
BA_ "GenSigCycleTime" SG_ 1441 AirIntakeValve_DiagStatus 100;
BA_ "GenSigCycleTimeActive" SG_ 1441 AirIntakeValve_DiagStatus 100;
BA_ "GenSigStartValue" SG_ 1441 AirIntakeValve_DiagStatus 3;
BA_ "Platform_Vivis2_Sig" SG_ 1441 AirIntakeValve_DiagStatus 1;
BA_ "GenSigCycleTime" SG_ 1441 BatterySoCcrankLimit2_1 100;
BA_ "GenSigCycleTimeActive" SG_ 1441 BatterySoCcrankLimit2_1 100;
BA_ "GenSigStartValue" SG_ 1441 BatterySoCcrankLimit2_1 255;
BA_ "GenSigMaxLatency" SG_ 1441 BatterySoCcrankLimit2_1 1080;
BA_ "Platform_Vivis2_Sig" SG_ 1441 BatterySoCcrankLimit2_1 1;
BA_ "GenSigCycleTime" SG_ 1441 BatterySOHCapa2_1 100;
BA_ "GenSigCycleTimeActive" SG_ 1441 BatterySOHCapa2_1 100;
BA_ "GenSigStartValue" SG_ 1441 BatterySOHCapa2_1 255;
BA_ "GenSigMaxLatency" SG_ 1441 BatterySOHCapa2_1 1080;
BA_ "Platform_Vivis2_Sig" SG_ 1441 BatterySOHCapa2_1 1;
BA_ "GenSigSendType" SG_ 1723 BPMU_ParamUpdate_Data 1;
BA_ "GenSigStartValue" SG_ 1723 BPMU_ParamUpdate_Data 65535;
BA_ "GenSigMaxLatency" SG_ 1723 BPMU_ParamUpdate_Data 100;
BA_ "Platform_Vivis2_Sig" SG_ 1723 BPMU_ParamUpdate_Data 1;
BA_ "GenSigSendType" SG_ 1723 BPMU_ParamReadSelection 1;
BA_ "GenSigStartValue" SG_ 1723 BPMU_ParamReadSelection 63;
BA_ "GenSigMaxLatency" SG_ 1723 BPMU_ParamReadSelection 100;
BA_ "Platform_Vivis2_Sig" SG_ 1723 BPMU_ParamReadSelection 1;
BA_ "GenSigSendType" SG_ 1723 BPMU_AuthRPP_rqst 1;
BA_ "GenSigStartValue" SG_ 1723 BPMU_AuthRPP_rqst 63;
BA_ "GenSigMaxLatency" SG_ 1723 BPMU_AuthRPP_rqst 100;
BA_ "Platform_Vivis2_Sig" SG_ 1723 BPMU_AuthRPP_rqst 1;
BA_ "GenSigSendType" SG_ 1723 BPMU_ParamUpdate_Selection 1;
BA_ "GenSigStartValue" SG_ 1723 BPMU_ParamUpdate_Selection 63;
BA_ "GenSigMaxLatency" SG_ 1723 BPMU_ParamUpdate_Selection 100;
BA_ "Platform_Vivis2_Sig" SG_ 1723 BPMU_ParamUpdate_Selection 1;
BA_ "GenSigCycleTime" SG_ 1382 BPMU_Conv1_CurrentSetPt 100;
BA_ "GenSigCycleTimeActive" SG_ 1382 BPMU_Conv1_CurrentSetPt 100;
BA_ "GenSigStartValue" SG_ 1382 BPMU_Conv1_CurrentSetPt 2047;
BA_ "GenSigMaxLatency" SG_ 1382 BPMU_Conv1_CurrentSetPt 100;
BA_ "Platform_Vivis2_Sig" SG_ 1382 BPMU_Conv1_CurrentSetPt 1;
BA_ "GenSigCycleTime" SG_ 1382 BPMU_VoltageRefSwitchCmd 100;
BA_ "GenSigCycleTimeActive" SG_ 1382 BPMU_VoltageRefSwitchCmd 100;
BA_ "GenSigStartValue" SG_ 1382 BPMU_VoltageRefSwitchCmd 3;
BA_ "Platform_Vivis2_Sig" SG_ 1382 BPMU_VoltageRefSwitchCmd 1;
BA_ "GenSigCycleTime" SG_ 1382 BPMU_Conv1_VoltageSetPt2 100;
BA_ "GenSigCycleTimeActive" SG_ 1382 BPMU_Conv1_VoltageSetPt2 100;
BA_ "GenSigStartValue" SG_ 1382 BPMU_Conv1_VoltageSetPt2 511;
BA_ "GenSigMaxLatency" SG_ 1382 BPMU_Conv1_VoltageSetPt2 100;
BA_ "Platform_Vivis2_Sig" SG_ 1382 BPMU_Conv1_VoltageSetPt2 1;
BA_ "GenSigCycleTime" SG_ 1382 BPMU_Conv1_VoltageSetPt1 100;
BA_ "GenSigCycleTimeActive" SG_ 1382 BPMU_Conv1_VoltageSetPt1 100;
BA_ "GenSigStartValue" SG_ 1382 BPMU_Conv1_VoltageSetPt1 511;
BA_ "GenSigMaxLatency" SG_ 1382 BPMU_Conv1_VoltageSetPt1 100;
BA_ "Platform_Vivis2_Sig" SG_ 1382 BPMU_Conv1_VoltageSetPt1 1;
BA_ "GenSigCycleTime" SG_ 1382 BPMU_Conv1_TargetOn 100;
BA_ "GenSigCycleTimeActive" SG_ 1382 BPMU_Conv1_TargetOn 100;
BA_ "GenSigStartValue" SG_ 1382 BPMU_Conv1_TargetOn 7;
BA_ "GenSigMaxLatency" SG_ 1382 BPMU_Conv1_TargetOn 100;
BA_ "Platform_Vivis2_Sig" SG_ 1382 BPMU_Conv1_TargetOn 1;
BA_ "GenSigCycleTime" SG_ 956 BatteryCurrentHSB 100;
BA_ "GenSigCycleTimeActive" SG_ 956 BatteryCurrentHSB 100;
BA_ "GenSigStartValue" SG_ 956 BatteryCurrentHSB 65535;
BA_ "Platform_Vivis2_Sig" SG_ 956 BatteryCurrentHSB 1;
BA_ "GenSigCycleTime" SG_ 956 BatteryEndOfChargeHSB_ISig_4 100;
BA_ "GenSigCycleTimeActive" SG_ 956 BatteryEndOfChargeHSB_ISig_4 100;
BA_ "GenSigStartValue" SG_ 956 BatteryEndOfChargeHSB_ISig_4 3;
BA_ "Platform_Vivis2_Sig" SG_ 956 BatteryEndOfChargeHSB_ISig_4 1;
BA_ "GenSigCycleTime" SG_ 956 Pto1RequestFeedback 100;
BA_ "GenSigCycleTimeActive" SG_ 956 Pto1RequestFeedback 100;
BA_ "GenSigStartValue" SG_ 956 Pto1RequestFeedback 7;
BA_ "GenSigMaxLatency" SG_ 956 Pto1RequestFeedback 50;
BA_ "Platform_Vivis2_Sig" SG_ 956 Pto1RequestFeedback 1;
BA_ "GenSigCycleTime" SG_ 956 StratificationStatusHSB 100;
BA_ "GenSigCycleTimeActive" SG_ 956 StratificationStatusHSB 100;
BA_ "GenSigStartValue" SG_ 956 StratificationStatusHSB 3;
BA_ "Platform_Vivis2_Sig" SG_ 956 StratificationStatusHSB 1;
BA_ "GenSigCycleTime" SG_ 956 AutoLoadCutOffState_ISig_4 100;
BA_ "GenSigCycleTimeActive" SG_ 956 AutoLoadCutOffState_ISig_4 100;
BA_ "GenSigStartValue" SG_ 956 AutoLoadCutOffState_ISig_4 7;
BA_ "Platform_Vivis2_Sig" SG_ 956 AutoLoadCutOffState_ISig_4 1;
BA_ "GenSigCycleTime" SG_ 956 BatteryEndOfChargeLSB_ISig_4 100;
BA_ "GenSigCycleTimeActive" SG_ 956 BatteryEndOfChargeLSB_ISig_4 100;
BA_ "GenSigStartValue" SG_ 956 BatteryEndOfChargeLSB_ISig_4 3;
BA_ "Platform_Vivis2_Sig" SG_ 956 BatteryEndOfChargeLSB_ISig_4 1;
BA_ "GenSigCycleTime" SG_ 956 FrontTargetLevelReached 100;
BA_ "GenSigCycleTimeActive" SG_ 956 FrontTargetLevelReached 100;
BA_ "GenSigStartValue" SG_ 956 FrontTargetLevelReached 3;
BA_ "GenSigCycleTime" SG_ 956 Ultracap_Status_ISig_4 100;
BA_ "GenSigCycleTimeActive" SG_ 956 Ultracap_Status_ISig_4 100;
BA_ "GenSigStartValue" SG_ 956 Ultracap_Status_ISig_4 7;
BA_ "Platform_Vivis2_Sig" SG_ 956 Ultracap_Status_ISig_4 1;
BA_ "GenSigCycleTime" SG_ 956 AdditionEnergySourceNeeded24V 100;
BA_ "GenSigCycleTimeActive" SG_ 956 AdditionEnergySourceNeeded24V 100;
BA_ "GenSigStartValue" SG_ 956 AdditionEnergySourceNeeded24V 7;
BA_ "GenSigMaxLatency" SG_ 956 AdditionEnergySourceNeeded24V 101;
BA_ "Platform_Vivis2_Sig" SG_ 956 AdditionEnergySourceNeeded24V 1;
BA_ "GenSigCycleTime" SG_ 956 Pto2RequestFeedback 100;
BA_ "GenSigCycleTimeActive" SG_ 956 Pto2RequestFeedback 100;
BA_ "GenSigStartValue" SG_ 956 Pto2RequestFeedback 7;
BA_ "GenSigMaxLatency" SG_ 956 Pto2RequestFeedback 50;
BA_ "Platform_Vivis2_Sig" SG_ 956 Pto2RequestFeedback 1;
BA_ "GenSigCycleTime" SG_ 956 UltracapDisplay_Stat_ISig_4 100;
BA_ "GenSigCycleTimeActive" SG_ 956 UltracapDisplay_Stat_ISig_4 100;
BA_ "GenSigStartValue" SG_ 956 UltracapDisplay_Stat_ISig_4 7;
BA_ "Platform_Vivis2_Sig" SG_ 956 UltracapDisplay_Stat_ISig_4 1;
BA_ "GenSigCycleTime" SG_ 956 RemainingNrOfCrank24V 100;
BA_ "GenSigCycleTimeActive" SG_ 956 RemainingNrOfCrank24V 100;
BA_ "GenSigStartValue" SG_ 956 RemainingNrOfCrank24V 255;
BA_ "GenSigMaxLatency" SG_ 956 RemainingNrOfCrank24V 101;
BA_ "Platform_Vivis2_Sig" SG_ 956 RemainingNrOfCrank24V 1;
BA_ "GenSigCycleTime" SG_ 956 StratificationStatusLSB 100;
BA_ "GenSigCycleTimeActive" SG_ 956 StratificationStatusLSB 100;
BA_ "GenSigStartValue" SG_ 956 StratificationStatusLSB 3;
BA_ "Platform_Vivis2_Sig" SG_ 956 StratificationStatusLSB 1;
BA_ "GenSigCycleTime" SG_ 1313 BPMU_Conv2_VoltageSetPt2 100;
BA_ "GenSigCycleTimeActive" SG_ 1313 BPMU_Conv2_VoltageSetPt2 100;
BA_ "GenSigStartValue" SG_ 1313 BPMU_Conv2_VoltageSetPt2 511;
BA_ "GenSigMaxLatency" SG_ 1313 BPMU_Conv2_VoltageSetPt2 100;
BA_ "Platform_Vivis2_Sig" SG_ 1313 BPMU_Conv2_VoltageSetPt2 1;
BA_ "GenSigCycleTime" SG_ 1313 BPMU_Conv2_TargetOn 100;
BA_ "GenSigCycleTimeActive" SG_ 1313 BPMU_Conv2_TargetOn 100;
BA_ "GenSigStartValue" SG_ 1313 BPMU_Conv2_TargetOn 7;
BA_ "GenSigMaxLatency" SG_ 1313 BPMU_Conv2_TargetOn 100;
BA_ "Platform_Vivis2_Sig" SG_ 1313 BPMU_Conv2_TargetOn 1;
BA_ "GenSigCycleTime" SG_ 1313 BPMU_Conv2_VoltageSetPt1 100;
BA_ "GenSigCycleTimeActive" SG_ 1313 BPMU_Conv2_VoltageSetPt1 100;
BA_ "GenSigStartValue" SG_ 1313 BPMU_Conv2_VoltageSetPt1 511;
BA_ "GenSigMaxLatency" SG_ 1313 BPMU_Conv2_VoltageSetPt1 100;
BA_ "Platform_Vivis2_Sig" SG_ 1313 BPMU_Conv2_VoltageSetPt1 1;
BA_ "GenSigCycleTime" SG_ 1313 BPMU_Conv2_CurrentSetPt 100;
BA_ "GenSigCycleTimeActive" SG_ 1313 BPMU_Conv2_CurrentSetPt 100;
BA_ "GenSigStartValue" SG_ 1313 BPMU_Conv2_CurrentSetPt 1023;
BA_ "GenSigMaxLatency" SG_ 1313 BPMU_Conv2_CurrentSetPt 100;
BA_ "Platform_Vivis2_Sig" SG_ 1313 BPMU_Conv2_CurrentSetPt 1;
BA_ "GenSigCycleTime" SG_ 1251 ExtraBBKingPinFeedback 100;
BA_ "GenSigCycleTimeActive" SG_ 1251 ExtraBBKingPinFeedback 100;
BA_ "GenSigStartValue" SG_ 1251 ExtraBBKingPinFeedback 3;
BA_ "Platform_Vivis2_Sig" SG_ 1251 ExtraBBKingPinFeedback 1;
BA_ "GenSigCycleTime" SG_ 1251 DiffLockInterWhlStatusFrAxle2 100;
BA_ "GenSigCycleTimeActive" SG_ 1251 DiffLockInterWhlStatusFrAxle2 100;
BA_ "GenSigStartValue" SG_ 1251 DiffLockInterWhlStatusFrAxle2 3;
BA_ "Platform_VMCU1_Sig" SG_ 1251 DiffLockInterWhlStatusFrAxle2 1;
BA_ "Platform_Vivis2_Sig" SG_ 1251 DiffLockInterWhlStatusFrAxle2 1;
BA_ "GenSigCycleTime" SG_ 1251 PluggedVehicleWakeUp_rqst 100;
BA_ "GenSigCycleTimeActive" SG_ 1251 PluggedVehicleWakeUp_rqst 100;
BA_ "GenSigStartValue" SG_ 1251 PluggedVehicleWakeUp_rqst 3;
BA_ "Platform_Vivis2_Sig" SG_ 1251 PluggedVehicleWakeUp_rqst 1;
BA_ "GenSigCycleTime" SG_ 1251 GearRangeUnengaged_ISig_4 100;
BA_ "GenSigCycleTimeActive" SG_ 1251 GearRangeUnengaged_ISig_4 100;
BA_ "GenSigStartValue" SG_ 1251 GearRangeUnengaged_ISig_4 3;
BA_ "Platform_VMCU1_Sig" SG_ 1251 GearRangeUnengaged_ISig_4 1;
BA_ "Platform_Vivis2_Sig" SG_ 1251 GearRangeUnengaged_ISig_4 1;
BA_ "GenSigCycleTime" SG_ 1251 BatterySensorVoltage 100;
BA_ "GenSigCycleTimeActive" SG_ 1251 BatterySensorVoltage 100;
BA_ "GenSigStartValue" SG_ 1251 BatterySensorVoltage 511;
BA_ "Platform_Vivis2_Sig" SG_ 1251 BatterySensorVoltage 1;
BA_ "GenSigCycleTime" SG_ 1251 GChargerStatus_ISig_4 100;
BA_ "GenSigCycleTimeActive" SG_ 1251 GChargerStatus_ISig_4 100;
BA_ "GenSigStartValue" SG_ 1251 GChargerStatus_ISig_4 7;
BA_ "Platform_Vivis2_Sig" SG_ 1251 GChargerStatus_ISig_4 1;
BA_ "GenSigCycleTime" SG_ 1251 LivBatteryCharging_stat_ISig_4 100;
BA_ "GenSigCycleTimeActive" SG_ 1251 LivBatteryCharging_stat_ISig_4 100;
BA_ "GenSigStartValue" SG_ 1251 LivBatteryCharging_stat_ISig_4 3;
BA_ "Platform_Vivis2_Sig" SG_ 1251 LivBatteryCharging_stat_ISig_4 1;
BA_ "GenSigCycleTime" SG_ 1251 FrontFactorySupportModeStatus 100;
BA_ "GenSigCycleTimeActive" SG_ 1251 FrontFactorySupportModeStatus 100;
BA_ "GenSigStartValue" SG_ 1251 FrontFactorySupportModeStatus 7;
BA_ "Platform_Vivis2_Sig" SG_ 1251 FrontFactorySupportModeStatus 1;
BA_ "GenSigCycleTime" SG_ 1251 LivBatDisconnectDetectStat_ISig_ 100;
BA_ "GenSigCycleTimeActive" SG_ 1251 LivBatDisconnectDetectStat_ISig_ 100;
BA_ "GenSigStartValue" SG_ 1251 LivBatDisconnectDetectStat_ISig_ 3;
BA_ "Platform_Vivis2_Sig" SG_ 1251 LivBatDisconnectDetectStat_ISig_ 1;
BA_ "SystemSignalLongSymbol" SG_ 1251 LivBatDisconnectDetectStat_ISig_ "LivBatDisconnectDetectStat_ISig_4";
BA_ "GenSigCycleTime" SG_ 1251 SideMarkersLight4_FailStat 100;
BA_ "GenSigCycleTimeActive" SG_ 1251 SideMarkersLight4_FailStat 100;
BA_ "GenSigStartValue" SG_ 1251 SideMarkersLight4_FailStat 7;
BA_ "Platform_VMCU1_Sig" SG_ 1251 SideMarkersLight4_FailStat 1;
BA_ "Platform_Vivis2_Sig" SG_ 1251 SideMarkersLight4_FailStat 1;
BA_ "GenSigCycleTime" SG_ 1251 DiffLockInterWhlStatSplitBox2 100;
BA_ "GenSigCycleTimeActive" SG_ 1251 DiffLockInterWhlStatSplitBox2 100;
BA_ "GenSigStartValue" SG_ 1251 DiffLockInterWhlStatSplitBox2 3;
BA_ "Platform_VMCU1_Sig" SG_ 1251 DiffLockInterWhlStatSplitBox2 1;
BA_ "Platform_Vivis2_Sig" SG_ 1251 DiffLockInterWhlStatSplitBox2 1;
BA_ "GenSigCycleTime" SG_ 1251 StratificationStatus 100;
BA_ "GenSigCycleTimeActive" SG_ 1251 StratificationStatus 100;
BA_ "GenSigStartValue" SG_ 1251 StratificationStatus 3;
BA_ "Platform_Vivis2_Sig" SG_ 1251 StratificationStatus 1;
BA_ "GenSigCycleTime" SG_ 1251 Cab12VSupplyStatus_ISig_4 100;
BA_ "GenSigCycleTimeActive" SG_ 1251 Cab12VSupplyStatus_ISig_4 100;
BA_ "GenSigStartValue" SG_ 1251 Cab12VSupplyStatus_ISig_4 3;
BA_ "Platform_Vivis2_Sig" SG_ 1251 Cab12VSupplyStatus_ISig_4 1;
BA_ "GenSigCycleTime" SG_ 1251 BatterySensorVoltageFiltered 100;
BA_ "GenSigCycleTimeActive" SG_ 1251 BatterySensorVoltageFiltered 100;
BA_ "GenSigStartValue" SG_ 1251 BatterySensorVoltageFiltered 511;
BA_ "Platform_Vivis2_Sig" SG_ 1251 BatterySensorVoltageFiltered 1;
BA_ "GenSigCycleTime" SG_ 1251 FrontOffsetLampCalib 100;
BA_ "GenSigCycleTimeActive" SG_ 1251 FrontOffsetLampCalib 100;
BA_ "GenSigStartValue" SG_ 1251 FrontOffsetLampCalib 65535;
BA_ "Platform_VMCU1_Sig" SG_ 1251 FrontOffsetLampCalib 1;
BA_ "Platform_Vivis2_Sig" SG_ 1251 FrontOffsetLampCalib 1;
BA_ "GenSigCycleTime" SG_ 1242 RelativeLevelFrontAxleRightRaw 100;
BA_ "GenSigCycleTimeActive" SG_ 1242 RelativeLevelFrontAxleRightRaw 100;
BA_ "GenSigStartValue" SG_ 1242 RelativeLevelFrontAxleRightRaw 65535;
BA_ "Platform_VMCU1_Sig" SG_ 1242 RelativeLevelFrontAxleRightRaw 1;
BA_ "Platform_Vivis2_Sig" SG_ 1242 RelativeLevelFrontAxleRightRaw 1;
BA_ "GenSigCycleTime" SG_ 1242 BatteryTemp_ISig_4 100;
BA_ "GenSigCycleTimeActive" SG_ 1242 BatteryTemp_ISig_4 100;
BA_ "GenSigStartValue" SG_ 1242 BatteryTemp_ISig_4 255;
BA_ "Platform_VMCU1_Sig" SG_ 1242 BatteryTemp_ISig_4 1;
BA_ "Platform_Vivis2_Sig" SG_ 1242 BatteryTemp_ISig_4 1;
BA_ "GenSigCycleTime" SG_ 1242 BatterySOCactCriticalAlert_ISig_ 100;
BA_ "GenSigCycleTimeActive" SG_ 1242 BatterySOCactCriticalAlert_ISig_ 100;
BA_ "GenSigStartValue" SG_ 1242 BatterySOCactCriticalAlert_ISig_ 255;
BA_ "Platform_VMCU1_Sig" SG_ 1242 BatterySOCactCriticalAlert_ISig_ 1;
BA_ "Platform_Vivis2_Sig" SG_ 1242 BatterySOCactCriticalAlert_ISig_ 1;
BA_ "SystemSignalLongSymbol" SG_ 1242 BatterySOCactCriticalAlert_ISig_ "BatterySOCactCriticalAlert_ISig_4";
BA_ "GenSigCycleTime" SG_ 1242 RelativeLevelFrontAxleLeftRaw 100;
BA_ "GenSigCycleTimeActive" SG_ 1242 RelativeLevelFrontAxleLeftRaw 100;
BA_ "GenSigStartValue" SG_ 1242 RelativeLevelFrontAxleLeftRaw 65535;
BA_ "Platform_VMCU1_Sig" SG_ 1242 RelativeLevelFrontAxleLeftRaw 1;
BA_ "Platform_Vivis2_Sig" SG_ 1242 RelativeLevelFrontAxleLeftRaw 1;
BA_ "GenSigCycleTime" SG_ 1242 BatteryTempAlertRawData_rqst_ISi 100;
BA_ "GenSigCycleTimeActive" SG_ 1242 BatteryTempAlertRawData_rqst_ISi 100;
BA_ "GenSigStartValue" SG_ 1242 BatteryTempAlertRawData_rqst_ISi 7;
BA_ "Platform_VMCU1_Sig" SG_ 1242 BatteryTempAlertRawData_rqst_ISi 1;
BA_ "Platform_Vivis2_Sig" SG_ 1242 BatteryTempAlertRawData_rqst_ISi 1;
BA_ "SystemSignalLongSymbol" SG_ 1242 BatteryTempAlertRawData_rqst_ISi "BatteryTempAlertRawData_rqst_ISig_4";
BA_ "GenSigCycleTime" SG_ 1242 BatterySOCact_ISig_4 100;
BA_ "GenSigCycleTimeActive" SG_ 1242 BatterySOCact_ISig_4 100;
BA_ "GenSigStartValue" SG_ 1242 BatterySOCact_ISig_4 255;
BA_ "Platform_VMCU1_Sig" SG_ 1242 BatterySOCact_ISig_4 1;
BA_ "Platform_Vivis2_Sig" SG_ 1242 BatterySOCact_ISig_4 1;
BA_ "GenSigCycleTime" SG_ 1242 BatteryTempAlert_rqst_ISig_4 100;
BA_ "GenSigCycleTimeActive" SG_ 1242 BatteryTempAlert_rqst_ISig_4 100;
BA_ "GenSigStartValue" SG_ 1242 BatteryTempAlert_rqst_ISig_4 7;
BA_ "Platform_VMCU1_Sig" SG_ 1242 BatteryTempAlert_rqst_ISig_4 1;
BA_ "Platform_Vivis2_Sig" SG_ 1242 BatteryTempAlert_rqst_ISig_4 1;
BA_ "GenSigCycleTime" SG_ 1510 ECSFrontCRC_Status 100;
BA_ "GenSigCycleTimeActive" SG_ 1510 ECSFrontCRC_Status 100;
BA_ "GenSigStartValue" SG_ 1510 ECSFrontCRC_Status 3;
BA_ "Platform_VMCU1_Sig" SG_ 1510 ECSFrontCRC_Status 1;
BA_ "Platform_Vivis2_Sig" SG_ 1510 ECSFrontCRC_Status 1;
BA_ "GenSigCycleTime" SG_ 1510 ECSFrontCRC_CRC 100;
BA_ "GenSigCycleTimeActive" SG_ 1510 ECSFrontCRC_CRC 100;
BA_ "GenSigStartValue" SG_ 1510 ECSFrontCRC_CRC 65535;
BA_ "Platform_VMCU1_Sig" SG_ 1510 ECSFrontCRC_CRC 1;
BA_ "Platform_Vivis2_Sig" SG_ 1510 ECSFrontCRC_CRC 1;
BA_ "GenSigCycleTime" SG_ 1510 WantedLBChargingVoltage 100;
BA_ "GenSigCycleTimeActive" SG_ 1510 WantedLBChargingVoltage 100;
BA_ "GenSigStartValue" SG_ 1510 WantedLBChargingVoltage 65535;
BA_ "Platform_VMCU1_Sig" SG_ 1510 WantedLBChargingVoltage 1;
BA_ "Platform_Vivis2_Sig" SG_ 1510 WantedLBChargingVoltage 1;
BA_ "GenSigCycleTime" SG_ 1250 BatterySOH_ISig_4 100;
BA_ "GenSigCycleTimeActive" SG_ 1250 BatterySOH_ISig_4 100;
BA_ "GenSigStartValue" SG_ 1250 BatterySOH_ISig_4 255;
BA_ "GenSigMaxLatency" SG_ 1250 BatterySOH_ISig_4 35;
BA_ "Platform_VMCU1_Sig" SG_ 1250 BatterySOH_ISig_4 1;
BA_ "Platform_Vivis2_Sig" SG_ 1250 BatterySOH_ISig_4 1;
BA_ "GenSigCycleTime" SG_ 1250 BatterySOCnom_ISig_4 100;
BA_ "GenSigCycleTimeActive" SG_ 1250 BatterySOCnom_ISig_4 100;
BA_ "GenSigStartValue" SG_ 1250 BatterySOCnom_ISig_4 255;
BA_ "GenSigMaxLatency" SG_ 1250 BatterySOCnom_ISig_4 35;
BA_ "Platform_VMCU1_Sig" SG_ 1250 BatterySOCnom_ISig_4 1;
BA_ "Platform_Vivis2_Sig" SG_ 1250 BatterySOCnom_ISig_4 1;
BA_ "GenSigCycleTime" SG_ 1250 BatterySOHTrustLevel 100;
BA_ "GenSigCycleTimeActive" SG_ 1250 BatterySOHTrustLevel 100;
BA_ "GenSigStartValue" SG_ 1250 BatterySOHTrustLevel 255;
BA_ "GenSigMaxLatency" SG_ 1250 BatterySOHTrustLevel 35;
BA_ "Platform_VMCU1_Sig" SG_ 1250 BatterySOHTrustLevel 1;
BA_ "Platform_Vivis2_Sig" SG_ 1250 BatterySOHTrustLevel 1;
BA_ "GenSigCycleTime" SG_ 1250 BatterySOF 100;
BA_ "GenSigCycleTimeActive" SG_ 1250 BatterySOF 100;
BA_ "GenSigStartValue" SG_ 1250 BatterySOF 255;
BA_ "Platform_VMCU1_Sig" SG_ 1250 BatterySOF 1;
BA_ "Platform_Vivis2_Sig" SG_ 1250 BatterySOF 1;
BA_ "GenSigCycleTime" SG_ 1250 BatteryCurrent_ISig_4 100;
BA_ "GenSigCycleTimeActive" SG_ 1250 BatteryCurrent_ISig_4 100;
BA_ "GenSigStartValue" SG_ 1250 BatteryCurrent_ISig_4 65535;
BA_ "GenSigMaxLatency" SG_ 1250 BatteryCurrent_ISig_4 35;
BA_ "Platform_VMCU1_Sig" SG_ 1250 BatteryCurrent_ISig_4 1;
BA_ "Platform_Vivis2_Sig" SG_ 1250 BatteryCurrent_ISig_4 1;
BA_ "GenSigCycleTime" SG_ 1250 BatteryVoltageDisplayValue_ISig_ 100;
BA_ "GenSigCycleTimeActive" SG_ 1250 BatteryVoltageDisplayValue_ISig_ 100;
BA_ "GenSigStartValue" SG_ 1250 BatteryVoltageDisplayValue_ISig_ 65535;
BA_ "GenSigMaxLatency" SG_ 1250 BatteryVoltageDisplayValue_ISig_ 35;
BA_ "Platform_VMCU1_Sig" SG_ 1250 BatteryVoltageDisplayValue_ISig_ 1;
BA_ "Platform_Vivis2_Sig" SG_ 1250 BatteryVoltageDisplayValue_ISig_ 1;
BA_ "SystemSignalLongSymbol" SG_ 1250 BatteryVoltageDisplayValue_ISig_ "BatteryVoltageDisplayValue_ISig_4";
BA_ "GenSigSendType" SG_ 823 DifferentialLockStateFrAxle1_UB_ 7;
BA_ "Platform_VMCU1_Sig" SG_ 823 DifferentialLockStateFrAxle1_UB_ 1;
BA_ "Platform_Vivis2_Sig" SG_ 823 DifferentialLockStateFrAxle1_UB_ 1;
BA_ "SystemSignalLongSymbol" SG_ 823 DifferentialLockStateFrAxle1_UB_ "DifferentialLockStateFrAxle1_UB_ISig_4";
BA_ "GenSigCycleTime" SG_ 823 FrontLimpHomeTrigger 100;
BA_ "GenSigCycleTimeActive" SG_ 823 FrontLimpHomeTrigger 100;
BA_ "GenSigStartValue" SG_ 823 FrontLimpHomeTrigger 7;
BA_ "GenSigMaxLatency" SG_ 823 FrontLimpHomeTrigger 35;
BA_ "Platform_VMCU1_Sig" SG_ 823 FrontLimpHomeTrigger 1;
BA_ "Platform_Vivis2_Sig" SG_ 823 FrontLimpHomeTrigger 1;
BA_ "GenSigCycleTime" SG_ 823 TransmLowRangeSenseSwitch_ISig_4 100;
BA_ "GenSigCycleTimeActive" SG_ 823 TransmLowRangeSenseSwitch_ISig_4 100;
BA_ "GenSigStartValue" SG_ 823 TransmLowRangeSenseSwitch_ISig_4 3;
BA_ "GenSigMaxLatency" SG_ 823 TransmLowRangeSenseSwitch_ISig_4 35;
BA_ "Platform_VMCU1_Sig" SG_ 823 TransmLowRangeSenseSwitch_ISig_4 1;
BA_ "Platform_Vivis2_Sig" SG_ 823 TransmLowRangeSenseSwitch_ISig_4 1;
BA_ "GenSigCycleTime" SG_ 823 ElectricalLoadReduction_rqst_ISi 100;
BA_ "GenSigCycleTimeActive" SG_ 823 ElectricalLoadReduction_rqst_ISi 100;
BA_ "GenSigInactiveValue" SG_ 823 ElectricalLoadReduction_rqst_ISi 7;
BA_ "GenSigStartValue" SG_ 823 ElectricalLoadReduction_rqst_ISi 7;
BA_ "GenSigMaxLatency" SG_ 823 ElectricalLoadReduction_rqst_ISi 35;
BA_ "NeedsUpdateBit" SG_ 823 ElectricalLoadReduction_rqst_ISi 1;
BA_ "Platform_VMCU1_Sig" SG_ 823 ElectricalLoadReduction_rqst_ISi 1;
BA_ "Platform_Vivis2_Sig" SG_ 823 ElectricalLoadReduction_rqst_ISi 1;
BA_ "SystemSignalLongSymbol" SG_ 823 ElectricalLoadReduction_rqst_ISi "ElectricalLoadReduction_rqst_ISig_4";
BA_ "GenSigCycleTime" SG_ 823 TransmReverseDirectionSw_stat 100;
BA_ "GenSigCycleTimeActive" SG_ 823 TransmReverseDirectionSw_stat 100;
BA_ "GenSigStartValue" SG_ 823 TransmReverseDirectionSw_stat 3;
BA_ "Platform_VMCU1_Sig" SG_ 823 TransmReverseDirectionSw_stat 1;
BA_ "Platform_Vivis2_Sig" SG_ 823 TransmReverseDirectionSw_stat 1;
BA_ "GenSigSendType" SG_ 823 FifthWheelLockingInformation_UB_ 7;
BA_ "Platform_VMCU1_Sig" SG_ 823 FifthWheelLockingInformation_UB_ 1;
BA_ "Platform_Vivis2_Sig" SG_ 823 FifthWheelLockingInformation_UB_ 1;
BA_ "SystemSignalLongSymbol" SG_ 823 FifthWheelLockingInformation_UB_ "FifthWheelLockingInformation_UB_ISig_4";
BA_ "GenSigCycleTime" SG_ 823 ManTransmiOilTemp_ISig_4 100;
BA_ "GenSigCycleTimeActive" SG_ 823 ManTransmiOilTemp_ISig_4 100;
BA_ "GenSigStartValue" SG_ 823 ManTransmiOilTemp_ISig_4 65535;
BA_ "GenSigMaxLatency" SG_ 823 ManTransmiOilTemp_ISig_4 35;
BA_ "NeedsUpdateBit" SG_ 823 ManTransmiOilTemp_ISig_4 1;
BA_ "Platform_VMCU1_Sig" SG_ 823 ManTransmiOilTemp_ISig_4 1;
BA_ "Platform_Vivis2_Sig" SG_ 823 ManTransmiOilTemp_ISig_4 1;
BA_ "GenSigCycleTime" SG_ 823 DirInd_MiddleSide_Status 100;
BA_ "GenSigCycleTimeActive" SG_ 823 DirInd_MiddleSide_Status 100;
BA_ "GenSigStartValue" SG_ 823 DirInd_MiddleSide_Status 7;
BA_ "Platform_VMCU1_Sig" SG_ 823 DirInd_MiddleSide_Status 1;
BA_ "Platform_Vivis2_Sig" SG_ 823 DirInd_MiddleSide_Status 1;
BA_ "GenSigCycleTime" SG_ 823 BatterySOCAlert_rqst_ISig_4 100;
BA_ "GenSigCycleTimeActive" SG_ 823 BatterySOCAlert_rqst_ISig_4 100;
BA_ "GenSigStartValue" SG_ 823 BatterySOCAlert_rqst_ISig_4 7;
BA_ "GenSigMaxLatency" SG_ 823 BatterySOCAlert_rqst_ISig_4 35;
BA_ "Platform_VMCU1_Sig" SG_ 823 BatterySOCAlert_rqst_ISig_4 1;
BA_ "Platform_Vivis2_Sig" SG_ 823 BatterySOCAlert_rqst_ISig_4 1;
BA_ "GenSigCycleTime" SG_ 823 DoubleFrontAxleSteeringWarning_I 100;
BA_ "GenSigCycleTimeActive" SG_ 823 DoubleFrontAxleSteeringWarning_I 100;
BA_ "GenSigStartValue" SG_ 823 DoubleFrontAxleSteeringWarning_I 3;
BA_ "Platform_Vivis2_Sig" SG_ 823 DoubleFrontAxleSteeringWarning_I 1;
BA_ "SystemSignalLongSymbol" SG_ 823 DoubleFrontAxleSteeringWarning_I "DoubleFrontAxleSteeringWarning_ISig_4";
BA_ "GenSigCycleTime" SG_ 823 DifferentialLockStateCentral_ISi 100;
BA_ "GenSigCycleTimeActive" SG_ 823 DifferentialLockStateCentral_ISi 100;
BA_ "GenSigStartValue" SG_ 823 DifferentialLockStateCentral_ISi 3;
BA_ "GenSigMaxLatency" SG_ 823 DifferentialLockStateCentral_ISi 35;
BA_ "Platform_VMCU1_Sig" SG_ 823 DifferentialLockStateCentral_ISi 1;
BA_ "Platform_Vivis2_Sig" SG_ 823 DifferentialLockStateCentral_ISi 1;
BA_ "SystemSignalLongSymbol" SG_ 823 DifferentialLockStateCentral_ISi "DifferentialLockStateCentral_ISig_4";
BA_ "GenSigCycleTime" SG_ 823 FifthWheelLockingInformation_ISi 100;
BA_ "GenSigCycleTimeActive" SG_ 823 FifthWheelLockingInformation_ISi 100;
BA_ "GenSigStartValue" SG_ 823 FifthWheelLockingInformation_ISi 15;
BA_ "GenSigMaxLatency" SG_ 823 FifthWheelLockingInformation_ISi 35;
BA_ "NeedsUpdateBit" SG_ 823 FifthWheelLockingInformation_ISi 1;
BA_ "Platform_VMCU1_Sig" SG_ 823 FifthWheelLockingInformation_ISi 1;
BA_ "Platform_Vivis2_Sig" SG_ 823 FifthWheelLockingInformation_ISi 1;
BA_ "SystemSignalLongSymbol" SG_ 823 FifthWheelLockingInformation_ISi "FifthWheelLockingInformation_ISig_4";
BA_ "GenSigSendType" SG_ 823 ElectricalLoadReduction_rqst_UB_ 7;
BA_ "Platform_VMCU1_Sig" SG_ 823 ElectricalLoadReduction_rqst_UB_ 1;
BA_ "Platform_Vivis2_Sig" SG_ 823 ElectricalLoadReduction_rqst_UB_ 1;
BA_ "SystemSignalLongSymbol" SG_ 823 ElectricalLoadReduction_rqst_UB_ "ElectricalLoadReduction_rqst_UB_ISig_4";
BA_ "GenSigCycleTime" SG_ 823 DiffLockInterWhlStatusSplitBox 100;
BA_ "GenSigCycleTimeActive" SG_ 823 DiffLockInterWhlStatusSplitBox 100;
BA_ "GenSigStartValue" SG_ 823 DiffLockInterWhlStatusSplitBox 3;
BA_ "Platform_VMCU1_Sig" SG_ 823 DiffLockInterWhlStatusSplitBox 1;
BA_ "Platform_Vivis2_Sig" SG_ 823 DiffLockInterWhlStatusSplitBox 1;
BA_ "GenSigCycleTime" SG_ 823 WrknLghtChassisOutpFalr_stat 100;
BA_ "GenSigCycleTimeActive" SG_ 823 WrknLghtChassisOutpFalr_stat 100;
BA_ "GenSigInactiveValue" SG_ 823 WrknLghtChassisOutpFalr_stat 7;
BA_ "GenSigStartValue" SG_ 823 WrknLghtChassisOutpFalr_stat 7;
BA_ "GenSigMaxLatency" SG_ 823 WrknLghtChassisOutpFalr_stat 35;
BA_ "Platform_VMCU1_Sig" SG_ 823 WrknLghtChassisOutpFalr_stat 1;
BA_ "Platform_Vivis2_Sig" SG_ 823 WrknLghtChassisOutpFalr_stat 1;
BA_ "GenSigCycleTime" SG_ 823 DifferentialLockStateFrAxle1_ISi 100;
BA_ "GenSigCycleTimeActive" SG_ 823 DifferentialLockStateFrAxle1_ISi 100;
BA_ "GenSigStartValue" SG_ 823 DifferentialLockStateFrAxle1_ISi 3;
BA_ "GenSigMaxLatency" SG_ 823 DifferentialLockStateFrAxle1_ISi 35;
BA_ "NeedsUpdateBit" SG_ 823 DifferentialLockStateFrAxle1_ISi 1;
BA_ "Platform_VMCU1_Sig" SG_ 823 DifferentialLockStateFrAxle1_ISi 1;
BA_ "Platform_Vivis2_Sig" SG_ 823 DifferentialLockStateFrAxle1_ISi 1;
BA_ "SystemSignalLongSymbol" SG_ 823 DifferentialLockStateFrAxle1_ISi "DifferentialLockStateFrAxle1_ISig_4";
BA_ "GenSigCycleTime" SG_ 823 GearSplit_Status_ISig_4 100;
BA_ "GenSigCycleTimeActive" SG_ 823 GearSplit_Status_ISig_4 100;
BA_ "GenSigStartValue" SG_ 823 GearSplit_Status_ISig_4 3;
BA_ "GenSigMaxLatency" SG_ 823 GearSplit_Status_ISig_4 35;
BA_ "NeedsUpdateBit" SG_ 823 GearSplit_Status_ISig_4 1;
BA_ "Platform_VMCU1_Sig" SG_ 823 GearSplit_Status_ISig_4 1;
BA_ "Platform_Vivis2_Sig" SG_ 823 GearSplit_Status_ISig_4 1;
BA_ "GenSigSendType" SG_ 823 ManTransmiOilTemp_UB_ISig_4 7;
BA_ "Platform_VMCU1_Sig" SG_ 823 ManTransmiOilTemp_UB_ISig_4 1;
BA_ "Platform_Vivis2_Sig" SG_ 823 ManTransmiOilTemp_UB_ISig_4 1;
BA_ "GenSigCycleTime" SG_ 823 LoadCutOffIndication_cmd_ISig_4 100;
BA_ "GenSigCycleTimeActive" SG_ 823 LoadCutOffIndication_cmd_ISig_4 100;
BA_ "GenSigStartValue" SG_ 823 LoadCutOffIndication_cmd_ISig_4 3;
BA_ "GenSigMaxLatency" SG_ 823 LoadCutOffIndication_cmd_ISig_4 35;
BA_ "Platform_VMCU1_Sig" SG_ 823 LoadCutOffIndication_cmd_ISig_4 1;
BA_ "Platform_Vivis2_Sig" SG_ 823 LoadCutOffIndication_cmd_ISig_4 1;
BA_ "GenSigCycleTime" SG_ 823 FifthWheelHandleLock_ind 100;
BA_ "GenSigCycleTimeActive" SG_ 823 FifthWheelHandleLock_ind 100;
BA_ "GenSigStartValue" SG_ 823 FifthWheelHandleLock_ind 3;
BA_ "Platform_VMCU1_Sig" SG_ 823 FifthWheelHandleLock_ind 1;
BA_ "Platform_Vivis2_Sig" SG_ 823 FifthWheelHandleLock_ind 1;
BA_ "GenSigSendType" SG_ 823 GearSplit_Status_UB_ISig_4 7;
BA_ "Platform_VMCU1_Sig" SG_ 823 GearSplit_Status_UB_ISig_4 1;
BA_ "Platform_Vivis2_Sig" SG_ 823 GearSplit_Status_UB_ISig_4 1;
BA_ "GenSigCycleTime" SG_ 823 BatteryCapacity_Ack_ISig_4 100;
BA_ "GenSigCycleTimeActive" SG_ 823 BatteryCapacity_Ack_ISig_4 100;
BA_ "GenSigStartValue" SG_ 823 BatteryCapacity_Ack_ISig_4 3;
BA_ "GenSigMaxLatency" SG_ 823 BatteryCapacity_Ack_ISig_4 35;
BA_ "Platform_VMCU1_Sig" SG_ 823 BatteryCapacity_Ack_ISig_4 1;
BA_ "Platform_Vivis2_Sig" SG_ 823 BatteryCapacity_Ack_ISig_4 1;
BA_ "GenSigCycleTime" SG_ 1244 FrontAxle1Load_ISig_4 100;
BA_ "GenSigCycleTimeActive" SG_ 1244 FrontAxle1Load_ISig_4 100;
BA_ "GenSigStartValue" SG_ 1244 FrontAxle1Load_ISig_4 65535;
BA_ "GenSigMaxLatency" SG_ 1244 FrontAxle1Load_ISig_4 255;
BA_ "NeedsUpdateBit" SG_ 1244 FrontAxle1Load_ISig_4 1;
BA_ "Platform_VMCU1_Sig" SG_ 1244 FrontAxle1Load_ISig_4 1;
BA_ "Platform_Vivis2_Sig" SG_ 1244 FrontAxle1Load_ISig_4 1;
BA_ "GenSigCycleTime" SG_ 1244 EqualizerUnbalance_ISig_4 100;
BA_ "GenSigCycleTimeActive" SG_ 1244 EqualizerUnbalance_ISig_4 100;
BA_ "GenSigStartValue" SG_ 1244 EqualizerUnbalance_ISig_4 7;
BA_ "Platform_Vivis2_Sig" SG_ 1244 EqualizerUnbalance_ISig_4 1;
BA_ "GenSigCycleTime" SG_ 1244 FrontAxle2Load_ISig_4 100;
BA_ "GenSigCycleTimeActive" SG_ 1244 FrontAxle2Load_ISig_4 100;
BA_ "GenSigStartValue" SG_ 1244 FrontAxle2Load_ISig_4 65535;
BA_ "GenSigMaxLatency" SG_ 1244 FrontAxle2Load_ISig_4 255;
BA_ "NeedsUpdateBit" SG_ 1244 FrontAxle2Load_ISig_4 1;
BA_ "Platform_VMCU1_Sig" SG_ 1244 FrontAxle2Load_ISig_4 1;
BA_ "Platform_Vivis2_Sig" SG_ 1244 FrontAxle2Load_ISig_4 1;
BA_ "GenSigCycleTime" SG_ 1244 ShortStopHeater_status_ISig_4 100;
BA_ "GenSigCycleTimeActive" SG_ 1244 ShortStopHeater_status_ISig_4 100;
BA_ "GenSigStartValue" SG_ 1244 ShortStopHeater_status_ISig_4 7;
BA_ "Platform_VMCU1_Sig" SG_ 1244 ShortStopHeater_status_ISig_4 1;
BA_ "Platform_Vivis2_Sig" SG_ 1244 ShortStopHeater_status_ISig_4 1;
BA_ "GenSigCycleTime" SG_ 1244 ExtraBBContUnlockFeedback 100;
BA_ "GenSigCycleTimeActive" SG_ 1244 ExtraBBContUnlockFeedback 100;
BA_ "GenSigStartValue" SG_ 1244 ExtraBBContUnlockFeedback 3;
BA_ "Platform_VMCU1_Sig" SG_ 1244 ExtraBBContUnlockFeedback 1;
BA_ "Platform_Vivis2_Sig" SG_ 1244 ExtraBBContUnlockFeedback 1;
BA_ "GenSigSendType" SG_ 1244 FrontAxle1Load_UB_ISig_4 7;
BA_ "Platform_VMCU1_Sig" SG_ 1244 FrontAxle1Load_UB_ISig_4 1;
BA_ "Platform_Vivis2_Sig" SG_ 1244 FrontAxle1Load_UB_ISig_4 1;
BA_ "GenSigCycleTime" SG_ 1244 TrailerRevAndFogOutput_stat_ISig 100;
BA_ "GenSigCycleTimeActive" SG_ 1244 TrailerRevAndFogOutput_stat_ISig 100;
BA_ "GenSigStartValue" SG_ 1244 TrailerRevAndFogOutput_stat_ISig 3;
BA_ "Platform_VMCU1_Sig" SG_ 1244 TrailerRevAndFogOutput_stat_ISig 1;
BA_ "Platform_Vivis2_Sig" SG_ 1244 TrailerRevAndFogOutput_stat_ISig 1;
BA_ "SystemSignalLongSymbol" SG_ 1244 TrailerRevAndFogOutput_stat_ISig "TrailerRevAndFogOutput_stat_ISig_4";
BA_ "GenSigSendType" SG_ 1244 FrontAxle2Load_UB_ISig_4 7;
BA_ "Platform_VMCU1_Sig" SG_ 1244 FrontAxle2Load_UB_ISig_4 1;
BA_ "Platform_Vivis2_Sig" SG_ 1244 FrontAxle2Load_UB_ISig_4 1;
BA_ "GenSigCycleTime" SG_ 1244 ExtraBBSlidable5WFeedback 100;
BA_ "GenSigCycleTimeActive" SG_ 1244 ExtraBBSlidable5WFeedback 100;
BA_ "GenSigStartValue" SG_ 1244 ExtraBBSlidable5WFeedback 3;
BA_ "Platform_VMCU1_Sig" SG_ 1244 ExtraBBSlidable5WFeedback 1;
BA_ "Platform_Vivis2_Sig" SG_ 1244 ExtraBBSlidable5WFeedback 1;
BA_ "GenSigCycleTime" SG_ 1244 TrailerBrakePres_stat 100;
BA_ "GenSigCycleTimeActive" SG_ 1244 TrailerBrakePres_stat 100;
BA_ "GenSigStartValue" SG_ 1244 TrailerBrakePres_stat 3;
BA_ "Platform_VMCU1_Sig" SG_ 1244 TrailerBrakePres_stat 1;
BA_ "Platform_Vivis2_Sig" SG_ 1244 TrailerBrakePres_stat 1;
BA_ "GenSigCycleTime" SG_ 1244 FrontAxleGrpBellowTorque 100;
BA_ "GenSigCycleTimeActive" SG_ 1244 FrontAxleGrpBellowTorque 100;
BA_ "GenSigStartValue" SG_ 1244 FrontAxleGrpBellowTorque 65535;
BA_ "Platform_VMCU1_Sig" SG_ 1244 FrontAxleGrpBellowTorque 1;
BA_ "Platform_Vivis2_Sig" SG_ 1244 FrontAxleGrpBellowTorque 1;
BA_ "GenSigCycleTime" SG_ 1238 FrontAxleGroupLoad 100;
BA_ "GenSigCycleTimeActive" SG_ 1238 FrontAxleGroupLoad 100;
BA_ "GenSigStartValue" SG_ 1238 FrontAxleGroupLoad 65535;
BA_ "GenSigMaxLatency" SG_ 1238 FrontAxleGroupLoad 108;
BA_ "Platform_VMCU1_Sig" SG_ 1238 FrontAxleGroupLoad 1;
BA_ "Platform_Vivis2_Sig" SG_ 1238 FrontAxleGroupLoad 1;
BA_ "GenSigCycleTime" SG_ 1238 RelativeLevelFrontAxleLeft_ISig_ 100;
BA_ "GenSigCycleTimeActive" SG_ 1238 RelativeLevelFrontAxleLeft_ISig_ 100;
BA_ "GenSigStartValue" SG_ 1238 RelativeLevelFrontAxleLeft_ISig_ 65535;
BA_ "GenSigMaxLatency" SG_ 1238 RelativeLevelFrontAxleLeft_ISig_ 108;
BA_ "Platform_VMCU1_Sig" SG_ 1238 RelativeLevelFrontAxleLeft_ISig_ 1;
BA_ "Platform_Vivis2_Sig" SG_ 1238 RelativeLevelFrontAxleLeft_ISig_ 1;
BA_ "SystemSignalLongSymbol" SG_ 1238 RelativeLevelFrontAxleLeft_ISig_ "RelativeLevelFrontAxleLeft_ISig_4";
BA_ "GenSigCycleTime" SG_ 1238 FrontStabilizerSpringRate 100;
BA_ "GenSigCycleTimeActive" SG_ 1238 FrontStabilizerSpringRate 100;
BA_ "GenSigStartValue" SG_ 1238 FrontStabilizerSpringRate 65535;
BA_ "GenSigMaxLatency" SG_ 1238 FrontStabilizerSpringRate 108;
BA_ "Platform_VMCU1_Sig" SG_ 1238 FrontStabilizerSpringRate 1;
BA_ "Platform_Vivis2_Sig" SG_ 1238 FrontStabilizerSpringRate 1;
BA_ "GenSigCycleTime" SG_ 1238 RelativeLevelFrontAxleRight_ISig 100;
BA_ "GenSigCycleTimeActive" SG_ 1238 RelativeLevelFrontAxleRight_ISig 100;
BA_ "GenSigStartValue" SG_ 1238 RelativeLevelFrontAxleRight_ISig 65535;
BA_ "GenSigMaxLatency" SG_ 1238 RelativeLevelFrontAxleRight_ISig 108;
BA_ "Platform_VMCU1_Sig" SG_ 1238 RelativeLevelFrontAxleRight_ISig 1;
BA_ "Platform_Vivis2_Sig" SG_ 1238 RelativeLevelFrontAxleRight_ISig 1;
BA_ "SystemSignalLongSymbol" SG_ 1238 RelativeLevelFrontAxleRight_ISig "RelativeLevelFrontAxleRight_ISig_4";
BA_ "GenSigCycleTime" SG_ 1237 FrontAxleGrpUsedTorqueRef 100;
BA_ "GenSigCycleTimeActive" SG_ 1237 FrontAxleGrpUsedTorqueRef 100;
BA_ "GenSigStartValue" SG_ 1237 FrontAxleGrpUsedTorqueRef 65535;
BA_ "Platform_VMCU1_Sig" SG_ 1237 FrontAxleGrpUsedTorqueRef 1;
BA_ "Platform_Vivis2_Sig" SG_ 1237 FrontAxleGrpUsedTorqueRef 1;
BA_ "GenSigCycleTime" SG_ 1237 TotalFrBellowTrqMaxCapacity 100;
BA_ "GenSigCycleTimeActive" SG_ 1237 TotalFrBellowTrqMaxCapacity 100;
BA_ "GenSigStartValue" SG_ 1237 TotalFrBellowTrqMaxCapacity 65535;
BA_ "GenSigMaxLatency" SG_ 1237 TotalFrBellowTrqMaxCapacity 107;
BA_ "Platform_VMCU1_Sig" SG_ 1237 TotalFrBellowTrqMaxCapacity 1;
BA_ "Platform_Vivis2_Sig" SG_ 1237 TotalFrBellowTrqMaxCapacity 1;
BA_ "GenSigCycleTime" SG_ 1237 FrontAirDumpStatus 100;
BA_ "GenSigCycleTimeActive" SG_ 1237 FrontAirDumpStatus 100;
BA_ "GenSigStartValue" SG_ 1237 FrontAirDumpStatus 7;
BA_ "Platform_Vivis2_Sig" SG_ 1237 FrontAirDumpStatus 1;
BA_ "GenSigCycleTime" SG_ 1237 BatterySOCTrustLevel_ISig_4 100;
BA_ "GenSigCycleTimeActive" SG_ 1237 BatterySOCTrustLevel_ISig_4 100;
BA_ "GenSigStartValue" SG_ 1237 BatterySOCTrustLevel_ISig_4 255;
BA_ "Platform_VMCU1_Sig" SG_ 1237 BatterySOCTrustLevel_ISig_4 1;
BA_ "Platform_Vivis2_Sig" SG_ 1237 BatterySOCTrustLevel_ISig_4 1;
BA_ "GenSigCycleTime" SG_ 1237 BatterySOCAlertRawData_rqst_ISig 100;
BA_ "GenSigCycleTimeActive" SG_ 1237 BatterySOCAlertRawData_rqst_ISig 100;
BA_ "GenSigStartValue" SG_ 1237 BatterySOCAlertRawData_rqst_ISig 7;
BA_ "Platform_VMCU1_Sig" SG_ 1237 BatterySOCAlertRawData_rqst_ISig 1;
BA_ "Platform_Vivis2_Sig" SG_ 1237 BatterySOCAlertRawData_rqst_ISig 1;
BA_ "SystemSignalLongSymbol" SG_ 1237 BatterySOCAlertRawData_rqst_ISig "BatterySOCAlertRawData_rqst_ISig_4";
BA_ "GenSigCycleTime" SG_ 1237 TotalFrontLoadTorque 100;
BA_ "GenSigCycleTimeActive" SG_ 1237 TotalFrontLoadTorque 100;
BA_ "GenSigStartValue" SG_ 1237 TotalFrontLoadTorque 65535;
BA_ "GenSigMaxLatency" SG_ 1237 TotalFrontLoadTorque 107;
BA_ "Platform_VMCU1_Sig" SG_ 1237 TotalFrontLoadTorque 1;
BA_ "Platform_Vivis2_Sig" SG_ 1237 TotalFrontLoadTorque 1;
BA_ "GenSigCycleTime" SG_ 774 Pto1FeedbackStatus 100;
BA_ "GenSigCycleTimeActive" SG_ 774 Pto1FeedbackStatus 100;
BA_ "GenSigStartValue" SG_ 774 Pto1FeedbackStatus 3;
BA_ "GenSigMaxLatency" SG_ 774 Pto1FeedbackStatus 27;
BA_ "NeedsUpdateBit" SG_ 774 Pto1FeedbackStatus 1;
BA_ "Platform_VMCU1_Sig" SG_ 774 Pto1FeedbackStatus 1;
BA_ "Platform_Vivis2_Sig" SG_ 774 Pto1FeedbackStatus 1;
BA_ "GenSigCycleTime" SG_ 774 ReverseGearEngaged_ISig_4 100;
BA_ "GenSigCycleTimeActive" SG_ 774 ReverseGearEngaged_ISig_4 100;
BA_ "GenSigStartValue" SG_ 774 ReverseGearEngaged_ISig_4 3;
BA_ "GenSigMaxLatency" SG_ 774 ReverseGearEngaged_ISig_4 27;
BA_ "NeedsUpdateBit" SG_ 774 ReverseGearEngaged_ISig_4 1;
BA_ "Platform_VMCU1_Sig" SG_ 774 ReverseGearEngaged_ISig_4 1;
BA_ "Platform_Vivis2_Sig" SG_ 774 ReverseGearEngaged_ISig_4 1;
BA_ "GenSigSendType" SG_ 774 FuelLevel_UB_ISig_4 7;
BA_ "Platform_VMCU1_Sig" SG_ 774 FuelLevel_UB_ISig_4 1;
BA_ "Platform_Vivis2_Sig" SG_ 774 FuelLevel_UB_ISig_4 1;
BA_ "GenSigCycleTime" SG_ 774 BrakePressureSensorDemand2 100;
BA_ "GenSigCycleTimeActive" SG_ 774 BrakePressureSensorDemand2 100;
BA_ "GenSigStartValue" SG_ 774 BrakePressureSensorDemand2 255;
BA_ "Platform_VMCU1_Sig" SG_ 774 BrakePressureSensorDemand2 1;
BA_ "Platform_Vivis2_Sig" SG_ 774 BrakePressureSensorDemand2 1;
BA_ "GenSigCycleTime" SG_ 774 PneumaticTrailerBrakeStatus_ISig 100;
BA_ "GenSigCycleTimeActive" SG_ 774 PneumaticTrailerBrakeStatus_ISig 100;
BA_ "GenSigStartValue" SG_ 774 PneumaticTrailerBrakeStatus_ISig 3;
BA_ "Platform_Vivis2_Sig" SG_ 774 PneumaticTrailerBrakeStatus_ISig 1;
BA_ "SystemSignalLongSymbol" SG_ 774 PneumaticTrailerBrakeStatus_ISig "PneumaticTrailerBrakeStatus_ISig_4";
BA_ "GenSigCycleTime" SG_ 774 SWBrakeSwitch2 100;
BA_ "GenSigCycleTimeActive" SG_ 774 SWBrakeSwitch2 100;
BA_ "GenSigStartValue" SG_ 774 SWBrakeSwitch2 3;
BA_ "Platform_VMCU1_Sig" SG_ 774 SWBrakeSwitch2 1;
BA_ "Platform_Vivis2_Sig" SG_ 774 SWBrakeSwitch2 1;
BA_ "GenSigSendType" SG_ 774 ReverseGearEngaged_UB_ISig_4 7;
BA_ "Platform_VMCU1_Sig" SG_ 774 ReverseGearEngaged_UB_ISig_4 1;
BA_ "Platform_Vivis2_Sig" SG_ 774 ReverseGearEngaged_UB_ISig_4 1;
BA_ "GenSigCycleTime" SG_ 774 FuelLevel_ISig_4 100;
BA_ "GenSigCycleTimeActive" SG_ 774 FuelLevel_ISig_4 100;
BA_ "GenSigStartValue" SG_ 774 FuelLevel_ISig_4 255;
BA_ "GenSigMaxLatency" SG_ 774 FuelLevel_ISig_4 27;
BA_ "NeedsUpdateBit" SG_ 774 FuelLevel_ISig_4 1;
BA_ "Platform_VMCU1_Sig" SG_ 774 FuelLevel_ISig_4 1;
BA_ "Platform_Vivis2_Sig" SG_ 774 FuelLevel_ISig_4 1;
BA_ "GenSigCycleTime" SG_ 774 NeutralSwitch_stat 100;
BA_ "GenSigCycleTimeActive" SG_ 774 NeutralSwitch_stat 100;
BA_ "GenSigStartValue" SG_ 774 NeutralSwitch_stat 3;
BA_ "GenSigCycleTime" SG_ 774 MainSwitch_Status 100;
BA_ "GenSigCycleTimeActive" SG_ 774 MainSwitch_Status 100;
BA_ "GenSigStartValue" SG_ 774 MainSwitch_Status 3;
BA_ "GenSigMaxLatency" SG_ 774 MainSwitch_Status 27;
BA_ "Platform_VMCU1_Sig" SG_ 774 MainSwitch_Status 1;
BA_ "Platform_Vivis2_Sig" SG_ 774 MainSwitch_Status 1;
BA_ "GenSigSendType" SG_ 774 FuelVolume_UB_ISig_4 7;
BA_ "Platform_VMCU1_Sig" SG_ 774 FuelVolume_UB_ISig_4 1;
BA_ "Platform_Vivis2_Sig" SG_ 774 FuelVolume_UB_ISig_4 1;
BA_ "GenSigSendType" SG_ 774 Pto1FeedbackStatus_UB 7;
BA_ "Platform_VMCU1_Sig" SG_ 774 Pto1FeedbackStatus_UB 1;
BA_ "Platform_Vivis2_Sig" SG_ 774 Pto1FeedbackStatus_UB 1;
BA_ "GenSigCycleTime" SG_ 774 FuelVolume_ISig_4 100;
BA_ "GenSigCycleTimeActive" SG_ 774 FuelVolume_ISig_4 100;
BA_ "GenSigStartValue" SG_ 774 FuelVolume_ISig_4 2047;
BA_ "NeedsUpdateBit" SG_ 774 FuelVolume_ISig_4 1;
BA_ "Platform_VMCU1_Sig" SG_ 774 FuelVolume_ISig_4 1;
BA_ "Platform_Vivis2_Sig" SG_ 774 FuelVolume_ISig_4 1;
BA_ "GenSigCycleTime" SG_ 1245 JumpChargeInterface_stat_ISig_4 100;
BA_ "GenSigCycleTimeActive" SG_ 1245 JumpChargeInterface_stat_ISig_4 100;
BA_ "GenSigStartValue" SG_ 1245 JumpChargeInterface_stat_ISig_4 3;
BA_ "GenSigMaxLatency" SG_ 1245 JumpChargeInterface_stat_ISig_4 100;
BA_ "Platform_VMCU1_Sig" SG_ 1245 JumpChargeInterface_stat_ISig_4 1;
BA_ "Platform_Vivis2_Sig" SG_ 1245 JumpChargeInterface_stat_ISig_4 1;
BA_ "GenSigCycleTime" SG_ 1245 GridCharger_stat 100;
BA_ "GenSigCycleTimeActive" SG_ 1245 GridCharger_stat 100;
BA_ "GenSigStartValue" SG_ 1245 GridCharger_stat 7;
BA_ "GenSigMaxLatency" SG_ 1245 GridCharger_stat 100;
BA_ "Platform_VMCU1_Sig" SG_ 1245 GridCharger_stat 1;
BA_ "Platform_Vivis2_Sig" SG_ 1245 GridCharger_stat 1;
BA_ "GenSigCycleTime" SG_ 1245 StartBatteryDisplay_stat_ISig_4 100;
BA_ "GenSigCycleTimeActive" SG_ 1245 StartBatteryDisplay_stat_ISig_4 100;
BA_ "GenSigStartValue" SG_ 1245 StartBatteryDisplay_stat_ISig_4 7;
BA_ "GenSigMaxLatency" SG_ 1245 StartBatteryDisplay_stat_ISig_4 100;
BA_ "Platform_VMCU1_Sig" SG_ 1245 StartBatteryDisplay_stat_ISig_4 1;
BA_ "Platform_Vivis2_Sig" SG_ 1245 StartBatteryDisplay_stat_ISig_4 1;
BA_ "GenSigCycleTime" SG_ 1350 BPMU_VoltageSBAT_RP 100;
BA_ "GenSigCycleTimeActive" SG_ 1350 BPMU_VoltageSBAT_RP 100;
BA_ "GenSigStartValue" SG_ 1350 BPMU_VoltageSBAT_RP 511;
BA_ "GenSigMaxLatency" SG_ 1350 BPMU_VoltageSBAT_RP 100;
BA_ "Platform_Vivis2_Sig" SG_ 1350 BPMU_VoltageSBAT_RP 1;
BA_ "GenSigCycleTime" SG_ 1350 BPMU_Conv1Mode_Status 100;
BA_ "GenSigCycleTimeActive" SG_ 1350 BPMU_Conv1Mode_Status 100;
BA_ "GenSigStartValue" SG_ 1350 BPMU_Conv1Mode_Status 7;
BA_ "GenSigMaxLatency" SG_ 1350 BPMU_Conv1Mode_Status 100;
BA_ "Platform_Vivis2_Sig" SG_ 1350 BPMU_Conv1Mode_Status 1;
BA_ "GenSigCycleTime" SG_ 1350 BPMU_Conv2Mode_Status 100;
BA_ "GenSigCycleTimeActive" SG_ 1350 BPMU_Conv2Mode_Status 100;
BA_ "GenSigStartValue" SG_ 1350 BPMU_Conv2Mode_Status 7;
BA_ "GenSigMaxLatency" SG_ 1350 BPMU_Conv2Mode_Status 100;
BA_ "Platform_Vivis2_Sig" SG_ 1350 BPMU_Conv2Mode_Status 1;
BA_ "GenSigCycleTime" SG_ 1350 BPMU_CurrentECI 100;
BA_ "GenSigCycleTimeActive" SG_ 1350 BPMU_CurrentECI 100;
BA_ "GenSigStartValue" SG_ 1350 BPMU_CurrentECI 32767;
BA_ "GenSigMaxLatency" SG_ 1350 BPMU_CurrentECI 100;
BA_ "Platform_Vivis2_Sig" SG_ 1350 BPMU_CurrentECI 1;
BA_ "GenSigCycleTime" SG_ 1350 BPMU_RPP_FLT_status 100;
BA_ "GenSigCycleTimeActive" SG_ 1350 BPMU_RPP_FLT_status 100;
BA_ "GenSigStartValue" SG_ 1350 BPMU_RPP_FLT_status 63;
BA_ "GenSigMaxLatency" SG_ 1350 BPMU_RPP_FLT_status 100;
BA_ "Platform_Vivis2_Sig" SG_ 1350 BPMU_RPP_FLT_status 1;
BA_ "GenSigCycleTime" SG_ 1348 BPMU_VoltageECI 100;
BA_ "GenSigCycleTimeActive" SG_ 1348 BPMU_VoltageECI 100;
BA_ "GenSigStartValue" SG_ 1348 BPMU_VoltageECI 511;
BA_ "GenSigMaxLatency" SG_ 1348 BPMU_VoltageECI 100;
BA_ "Platform_Vivis2_Sig" SG_ 1348 BPMU_VoltageECI 1;
BA_ "GenSigCycleTime" SG_ 1348 BPMU_Voltage12VDO 100;
BA_ "GenSigCycleTimeActive" SG_ 1348 BPMU_Voltage12VDO 100;
BA_ "GenSigStartValue" SG_ 1348 BPMU_Voltage12VDO 255;
BA_ "GenSigMaxLatency" SG_ 1348 BPMU_Voltage12VDO 100;
BA_ "Platform_Vivis2_Sig" SG_ 1348 BPMU_Voltage12VDO 1;
BA_ "GenSigCycleTime" SG_ 1348 BPMU_VoltageECILSB_RP 100;
BA_ "GenSigCycleTimeActive" SG_ 1348 BPMU_VoltageECILSB_RP 100;
BA_ "GenSigStartValue" SG_ 1348 BPMU_VoltageECILSB_RP 511;
BA_ "GenSigMaxLatency" SG_ 1348 BPMU_VoltageECILSB_RP 100;
BA_ "Platform_Vivis2_Sig" SG_ 1348 BPMU_VoltageECILSB_RP 1;
BA_ "GenSigCycleTime" SG_ 1348 BPMU_VoltageLSB 100;
BA_ "GenSigCycleTimeActive" SG_ 1348 BPMU_VoltageLSB 100;
BA_ "GenSigStartValue" SG_ 1348 BPMU_VoltageLSB 255;
BA_ "GenSigMaxLatency" SG_ 1348 BPMU_VoltageLSB 100;
BA_ "Platform_Vivis2_Sig" SG_ 1348 BPMU_VoltageLSB 1;
BA_ "GenSigCycleTime" SG_ 1348 BPMU_VoltageSBAT 100;
BA_ "GenSigCycleTimeActive" SG_ 1348 BPMU_VoltageSBAT 100;
BA_ "GenSigStartValue" SG_ 1348 BPMU_VoltageSBAT 511;
BA_ "GenSigMaxLatency" SG_ 1348 BPMU_VoltageSBAT 100;
BA_ "Platform_Vivis2_Sig" SG_ 1348 BPMU_VoltageSBAT 1;
BA_ "GenSigCycleTime" SG_ 1348 BPMU_VoltageHSB_RP 100;
BA_ "GenSigCycleTimeActive" SG_ 1348 BPMU_VoltageHSB_RP 100;
BA_ "GenSigStartValue" SG_ 1348 BPMU_VoltageHSB_RP 511;
BA_ "GenSigMaxLatency" SG_ 1348 BPMU_VoltageHSB_RP 100;
BA_ "Platform_Vivis2_Sig" SG_ 1348 BPMU_VoltageHSB_RP 1;
BA_ "GenSigCycleTime" SG_ 1348 BPMU_VoltageHSB 100;
BA_ "GenSigCycleTimeActive" SG_ 1348 BPMU_VoltageHSB 100;
BA_ "GenSigStartValue" SG_ 1348 BPMU_VoltageHSB 511;
BA_ "GenSigMaxLatency" SG_ 1348 BPMU_VoltageHSB 100;
BA_ "Platform_Vivis2_Sig" SG_ 1348 BPMU_VoltageHSB 1;
BA_ "GenSigCycleTime" SG_ 1351 BPMU_CurrentLSB 100;
BA_ "GenSigCycleTimeActive" SG_ 1351 BPMU_CurrentLSB 100;
BA_ "GenSigStartValue" SG_ 1351 BPMU_CurrentLSB 32767;
BA_ "GenSigMaxLatency" SG_ 1351 BPMU_CurrentLSB 100;
BA_ "Platform_Vivis2_Sig" SG_ 1351 BPMU_CurrentLSB 1;
BA_ "GenSigCycleTime" SG_ 1351 BPMU_Current12VDO 100;
BA_ "GenSigCycleTimeActive" SG_ 1351 BPMU_Current12VDO 100;
BA_ "GenSigStartValue" SG_ 1351 BPMU_Current12VDO 32767;
BA_ "GenSigMaxLatency" SG_ 1351 BPMU_Current12VDO 100;
BA_ "Platform_Vivis2_Sig" SG_ 1351 BPMU_Current12VDO 1;
BA_ "GenSigCycleTime" SG_ 1351 BPMU_CurrentSBAT 100;
BA_ "GenSigCycleTimeActive" SG_ 1351 BPMU_CurrentSBAT 100;
BA_ "GenSigStartValue" SG_ 1351 BPMU_CurrentSBAT 16383;
BA_ "GenSigMaxLatency" SG_ 1351 BPMU_CurrentSBAT 100;
BA_ "Platform_Vivis2_Sig" SG_ 1351 BPMU_CurrentSBAT 1;
BA_ "GenSigCycleTime" SG_ 1351 BPMU_CurrentHSB 100;
BA_ "GenSigCycleTimeActive" SG_ 1351 BPMU_CurrentHSB 100;
BA_ "GenSigStartValue" SG_ 1351 BPMU_CurrentHSB 32767;
BA_ "GenSigMaxLatency" SG_ 1351 BPMU_CurrentHSB 100;
BA_ "Platform_Vivis2_Sig" SG_ 1351 BPMU_CurrentHSB 1;
BA_ "GenSigCycleTime" SG_ 1252 BPMU_FaultDiag2 100;
BA_ "GenSigCycleTimeActive" SG_ 1252 BPMU_FaultDiag2 100;
BA_ "GenSigStartValue" SG_ 1252 BPMU_FaultDiag2 4294967295;
BA_ "GenSigMaxLatency" SG_ 1252 BPMU_FaultDiag2 100;
BA_ "Platform_Vivis2_Sig" SG_ 1252 BPMU_FaultDiag2 1;
BA_ "GenSigCycleTime" SG_ 1252 BPMU_FaultDiag1 100;
BA_ "GenSigCycleTimeActive" SG_ 1252 BPMU_FaultDiag1 100;
BA_ "GenSigStartValue" SG_ 1252 BPMU_FaultDiag1 4294967295;
BA_ "GenSigMaxLatency" SG_ 1252 BPMU_FaultDiag1 100;
BA_ "Platform_Vivis2_Sig" SG_ 1252 BPMU_FaultDiag1 1;
BA_ "GenSigSendType" SG_ 831 BPMU_ParamRead_Data 1;
BA_ "GenSigStartValue" SG_ 831 BPMU_ParamRead_Data 65535;
BA_ "GenSigMaxLatency" SG_ 831 BPMU_ParamRead_Data 100;
BA_ "Platform_Vivis2_Sig" SG_ 831 BPMU_ParamRead_Data 1;
BA_ "GenSigSendType" SG_ 831 BPMU_ParamRead_Selection 1;
BA_ "GenSigStartValue" SG_ 831 BPMU_ParamRead_Selection 63;
BA_ "GenSigMaxLatency" SG_ 831 BPMU_ParamRead_Selection 100;
BA_ "Platform_Vivis2_Sig" SG_ 831 BPMU_ParamRead_Selection 1;
BA_ "GenSigSendType" SG_ 1730 AnmSig_WSGW_C04 1;
BA_ "GenSigCycleTime" SG_ 1730 AnmSig_WSGW_C04 100;
BA_ "GenSigCycleTimeActive" SG_ 1730 AnmSig_WSGW_C04 100;
BA_ "MmAnSignal" SG_ 1730 AnmSig_WSGW_C04 1;
BA_ "GenSigSendType" SG_ 1726 AnmSig_VCM_CAN04 1;
BA_ "GenSigCycleTime" SG_ 1726 AnmSig_VCM_CAN04 100;
BA_ "GenSigCycleTimeActive" SG_ 1726 AnmSig_VCM_CAN04 100;
BA_ "MmAnSignal" SG_ 1726 AnmSig_VCM_CAN04 1;
BA_ "GenSigSendType" SG_ 1725 AnmSig_TBIOM_CAN04 1;
BA_ "GenSigCycleTime" SG_ 1725 AnmSig_TBIOM_CAN04 100;
BA_ "GenSigCycleTimeActive" SG_ 1725 AnmSig_TBIOM_CAN04 100;
BA_ "MmAnSignal" SG_ 1725 AnmSig_TBIOM_CAN04 1;
BA_ "GenSigSendType" SG_ 1724 AnmSig_RCIOM_CAN04 1;
BA_ "GenSigCycleTime" SG_ 1724 AnmSig_RCIOM_CAN04 100;
BA_ "GenSigCycleTimeActive" SG_ 1724 AnmSig_RCIOM_CAN04 100;
BA_ "MmAnSignal" SG_ 1724 AnmSig_RCIOM_CAN04 1;
BA_ "GenSigSendType" SG_ 1729 AnmSig_FCIOM_CAN04 1;
BA_ "GenSigCycleTime" SG_ 1729 AnmSig_FCIOM_CAN04 100;
BA_ "GenSigCycleTimeActive" SG_ 1729 AnmSig_FCIOM_CAN04 100;
BA_ "MmAnSignal" SG_ 1729 AnmSig_FCIOM_CAN04 1;
BA_ "GenSigSendType" SG_ 1727 AnmSig_CCIOM_CAN04 1;
BA_ "GenSigCycleTime" SG_ 1727 AnmSig_CCIOM_CAN04 100;
BA_ "GenSigCycleTimeActive" SG_ 1727 AnmSig_CCIOM_CAN04 100;
BA_ "MmAnSignal" SG_ 1727 AnmSig_CCIOM_CAN04 1;
BA_ "GenSigSendType" SG_ 1728 AnmSig_BPMU_CAN04 1;
BA_ "GenSigCycleTime" SG_ 1728 AnmSig_BPMU_CAN04 100;
BA_ "GenSigCycleTimeActive" SG_ 1728 AnmSig_BPMU_CAN04 100;
BA_ "MmAnSignal" SG_ 1728 AnmSig_BPMU_CAN04 1;
BA_ "GenSigCycleTime" SG_ 1223 RedGladHand_CRC_ISig_4 100;
BA_ "GenSigCycleTimeActive" SG_ 1223 RedGladHand_CRC_ISig_4 100;
BA_ "GenSigStartValue" SG_ 1223 RedGladHand_CRC_ISig_4 255;
BA_ "GenSigMaxLatency" SG_ 1223 RedGladHand_CRC_ISig_4 25;
BA_ "Platform_Vivis2_Sig" SG_ 1223 RedGladHand_CRC_ISig_4 1;
BA_ "E2EDataId" SG_ 1223 RedGladHand_CRC_ISig_4 146;
BA_ "E2EDataLength" SG_ 1223 RedGladHand_CRC_ISig_4 16;
BA_ "E2EProfile" SG_ 1223 RedGladHand_CRC_ISig_4 "P01";
BA_ "GenSigCycleTime" SG_ 1223 RedGladHand_ConfidenceLvl_ISig_4 100;
BA_ "GenSigCycleTimeActive" SG_ 1223 RedGladHand_ConfidenceLvl_ISig_4 100;
BA_ "GenSigStartValue" SG_ 1223 RedGladHand_ConfidenceLvl_ISig_4 3;
BA_ "GenSigMaxLatency" SG_ 1223 RedGladHand_ConfidenceLvl_ISig_4 25;
BA_ "Platform_Vivis2_Sig" SG_ 1223 RedGladHand_ConfidenceLvl_ISig_4 1;
BA_ "GenSigCycleTime" SG_ 1223 RedGladHand_SqC_ISig_4 100;
BA_ "GenSigCycleTimeActive" SG_ 1223 RedGladHand_SqC_ISig_4 100;
BA_ "GenSigStartValue" SG_ 1223 RedGladHand_SqC_ISig_4 14;
BA_ "GenSigMaxLatency" SG_ 1223 RedGladHand_SqC_ISig_4 25;
BA_ "Platform_Vivis2_Sig" SG_ 1223 RedGladHand_SqC_ISig_4 1;
BA_ "GenSigCycleTime" SG_ 1223 RedGladHand_ConnectStatus_ISig_4 100;
BA_ "GenSigCycleTimeActive" SG_ 1223 RedGladHand_ConnectStatus_ISig_4 100;
BA_ "GenSigStartValue" SG_ 1223 RedGladHand_ConnectStatus_ISig_4 3;
BA_ "GenSigMaxLatency" SG_ 1223 RedGladHand_ConnectStatus_ISig_4 25;
BA_ "Platform_Vivis2_Sig" SG_ 1223 RedGladHand_ConnectStatus_ISig_4 1;
BA_ "GenSigCycleTime" SG_ 822 EPBPowerFeedRequest_ISig_4 100;
BA_ "GenSigCycleTimeActive" SG_ 822 EPBPowerFeedRequest_ISig_4 100;
BA_ "GenSigStartValue" SG_ 822 EPBPowerFeedRequest_ISig_4 3;
BA_ "Platform_VMCU1_Sig" SG_ 822 EPBPowerFeedRequest_ISig_4 1;
BA_ "Platform_Vivis2_Sig" SG_ 822 EPBPowerFeedRequest_ISig_4 1;
BA_ "GenSigCycleTime" SG_ 1345 ServiceBrakeAirPrsCircuit1_ISig_ 100;
BA_ "GenSigCycleTimeActive" SG_ 1345 ServiceBrakeAirPrsCircuit1_ISig_ 100;
BA_ "GenSigStartValue" SG_ 1345 ServiceBrakeAirPrsCircuit1_ISig_ 255;
BA_ "SystemSignalLongSymbol" SG_ 1345 ServiceBrakeAirPrsCircuit1_ISig_ "ServiceBrakeAirPrsCircuit1_ISig_4";
BA_ "GenSigCycleTime" SG_ 949 LowAirPressureAlert_ISig_4 100;
BA_ "GenSigCycleTimeActive" SG_ 949 LowAirPressureAlert_ISig_4 100;
BA_ "GenSigStartValue" SG_ 949 LowAirPressureAlert_ISig_4 3;
BA_ "GenSigCycleTime" SG_ 949 ParkBrakeActuationStatus_ISig_4 100;
BA_ "GenSigCycleTimeActive" SG_ 949 ParkBrakeActuationStatus_ISig_4 100;
BA_ "GenSigStartValue" SG_ 949 ParkBrakeActuationStatus_ISig_4 7;
BA_REL_ "GenSigFirstTimeoutTime" BU_SG_REL_ VCM SG_ 1461 HighCurrentIR1_2B 24000;
BA_REL_ "GenSigTimeoutTime" BU_SG_REL_ VCM SG_ 1461 HighCurrentIR1_2B 6000;
BA_REL_ "GenSigFirstTimeoutTime" BU_SG_REL_ VCM SG_ 1461 WhCounterCharge_2B 24000;
BA_REL_ "GenSigTimeoutTime" BU_SG_REL_ VCM SG_ 1461 WhCounterCharge_2B 6000;
BA_REL_ "GenSigFirstTimeoutTime" BU_SG_REL_ VCM SG_ 1461 WhCounterDischarge_2B 24000;
BA_REL_ "GenSigTimeoutTime" BU_SG_REL_ VCM SG_ 1461 WhCounterDischarge_2B 6000;
BA_REL_ "GenSigFirstTimeoutTime" BU_SG_REL_ VCM SG_ 1459 HighCurrentIR1_3A 24000;
BA_REL_ "GenSigTimeoutTime" BU_SG_REL_ VCM SG_ 1459 HighCurrentIR1_3A 6000;
BA_REL_ "GenSigFirstTimeoutTime" BU_SG_REL_ VCM SG_ 1459 WhCounterDischarge_3A 24000;
BA_REL_ "GenSigTimeoutTime" BU_SG_REL_ VCM SG_ 1459 WhCounterDischarge_3A 6000;
BA_REL_ "GenSigFirstTimeoutTime" BU_SG_REL_ VCM SG_ 1459 WhCounterCharge_3A 24000;
BA_REL_ "GenSigTimeoutTime" BU_SG_REL_ VCM SG_ 1459 WhCounterCharge_3A 6000;
BA_REL_ "GenSigFirstTimeoutTime" BU_SG_REL_ VCM SG_ 1457 WhCounterCharge_3B 24000;
BA_REL_ "GenSigTimeoutTime" BU_SG_REL_ VCM SG_ 1457 WhCounterCharge_3B 6000;
BA_REL_ "GenSigFirstTimeoutTime" BU_SG_REL_ VCM SG_ 1457 HighCurrentIR1_3B 24000;
BA_REL_ "GenSigTimeoutTime" BU_SG_REL_ VCM SG_ 1457 HighCurrentIR1_3B 6000;
BA_REL_ "GenSigFirstTimeoutTime" BU_SG_REL_ VCM SG_ 1457 WhCounterDischarge_3B 24000;
BA_REL_ "GenSigTimeoutTime" BU_SG_REL_ VCM SG_ 1457 WhCounterDischarge_3B 6000;
BA_REL_ "GenSigFirstTimeoutTime" BU_SG_REL_ VCM SG_ 1455 HighCurrentIR2_1 24000;
BA_REL_ "GenSigTimeoutTime" BU_SG_REL_ VCM SG_ 1455 HighCurrentIR2_1 6000;
BA_REL_ "GenSigFirstTimeoutTime" BU_SG_REL_ VCM SG_ 1455 WhCounterDischarge2 24000;
BA_REL_ "GenSigTimeoutTime" BU_SG_REL_ VCM SG_ 1455 WhCounterDischarge2 6000;
BA_REL_ "GenSigFirstTimeoutTime" BU_SG_REL_ VCM SG_ 1455 WhCounterCharge2 24000;
BA_REL_ "GenSigTimeoutTime" BU_SG_REL_ VCM SG_ 1455 WhCounterCharge2 6000;
BA_REL_ "GenSigFirstTimeoutTime" BU_SG_REL_ VCM SG_ 1453 DeepDischargestatus_1A 24000;
BA_REL_ "GenSigTimeoutTime" BU_SG_REL_ VCM SG_ 1453 DeepDischargestatus_1A 6000;
BA_REL_ "GenSigFirstTimeoutTime" BU_SG_REL_ VCM SG_ 1453 BatterySoCcrankLimit1_1A 24000;
BA_REL_ "GenSigTimeoutTime" BU_SG_REL_ VCM SG_ 1453 BatterySoCcrankLimit1_1A 6000;
BA_REL_ "GenSigFirstTimeoutTime" BU_SG_REL_ VCM SG_ 1453 BatteryTempCo_1A 24000;
BA_REL_ "GenSigTimeoutTime" BU_SG_REL_ VCM SG_ 1453 BatteryTempCo_1A 6000;
BA_REL_ "GenSigFirstTimeoutTime" BU_SG_REL_ VCM SG_ 1453 BatterySOCTrustLevel_stat1_1A 24000;
BA_REL_ "GenSigTimeoutTime" BU_SG_REL_ VCM SG_ 1453 BatterySOCTrustLevel_stat1_1A 6000;
BA_REL_ "GenSigFirstTimeoutTime" BU_SG_REL_ VCM SG_ 1453 Endofchargestatus1_1A 24000;
BA_REL_ "GenSigTimeoutTime" BU_SG_REL_ VCM SG_ 1453 Endofchargestatus1_1A 6000;
BA_REL_ "GenSigFirstTimeoutTime" BU_SG_REL_ VCM SG_ 1453 BatteryReconnectionDetect_1A 24000;
BA_REL_ "GenSigTimeoutTime" BU_SG_REL_ VCM SG_ 1453 BatteryReconnectionDetect_1A 6000;
BA_REL_ "GenSigFirstTimeoutTime" BU_SG_REL_ VCM SG_ 1453 BatterySOHTrustLevel_stat1_1A 24000;
BA_REL_ "GenSigTimeoutTime" BU_SG_REL_ VCM SG_ 1453 BatterySOHTrustLevel_stat1_1A 6000;
BA_REL_ "GenSigFirstTimeoutTime" BU_SG_REL_ VCM SG_ 1453 EndOfDischargeStatus1_1A 24000;
BA_REL_ "GenSigTimeoutTime" BU_SG_REL_ VCM SG_ 1453 EndOfDischargeStatus1_1A 6000;
BA_REL_ "GenSigFirstTimeoutTime" BU_SG_REL_ VCM SG_ 1453 BatterySOHPower1_1A 24000;
BA_REL_ "GenSigTimeoutTime" BU_SG_REL_ VCM SG_ 1453 BatterySOHPower1_1A 6000;
BA_REL_ "GenSigFirstTimeoutTime" BU_SG_REL_ VCM SG_ 1453 BatteryExchangeDetect_1A 24000;
BA_REL_ "GenSigTimeoutTime" BU_SG_REL_ VCM SG_ 1453 BatteryExchangeDetect_1A 6000;
BA_REL_ "GenSigFirstTimeoutTime" BU_SG_REL_ VCM SG_ 1453 BatterySOHCapa1_1A 24000;
BA_REL_ "GenSigTimeoutTime" BU_SG_REL_ VCM SG_ 1453 BatterySOHCapa1_1A 6000;
BA_REL_ "GenSigFirstTimeoutTime" BU_SG_REL_ VCM SG_ 1453 BatterySOHPowerTrustLevel1_1A 24000;
BA_REL_ "GenSigTimeoutTime" BU_SG_REL_ VCM SG_ 1453 BatterySOHPowerTrustLevel1_1A 6000;
BA_REL_ "GenSigFirstTimeoutTime" BU_SG_REL_ VCM SG_ 1451 BatterySoCcrankLimit1_1B 24000;
BA_REL_ "GenSigTimeoutTime" BU_SG_REL_ VCM SG_ 1451 BatterySoCcrankLimit1_1B 6000;
BA_REL_ "GenSigFirstTimeoutTime" BU_SG_REL_ VCM SG_ 1451 BatterySOHTrustLevel_stat1_1B 24000;
BA_REL_ "GenSigTimeoutTime" BU_SG_REL_ VCM SG_ 1451 BatterySOHTrustLevel_stat1_1B 6000;
BA_REL_ "GenSigFirstTimeoutTime" BU_SG_REL_ VCM SG_ 1451 Endofchargestatus1_1B 24000;
BA_REL_ "GenSigTimeoutTime" BU_SG_REL_ VCM SG_ 1451 Endofchargestatus1_1B 6000;
BA_REL_ "GenSigFirstTimeoutTime" BU_SG_REL_ VCM SG_ 1451 BatteryExchangeDetect_1B 24000;
BA_REL_ "GenSigTimeoutTime" BU_SG_REL_ VCM SG_ 1451 BatteryExchangeDetect_1B 6000;
BA_REL_ "GenSigFirstTimeoutTime" BU_SG_REL_ VCM SG_ 1451 BatterySOCTrustLevel_stat1_1B 24000;
BA_REL_ "GenSigTimeoutTime" BU_SG_REL_ VCM SG_ 1451 BatterySOCTrustLevel_stat1_1B 6000;
BA_REL_ "GenSigFirstTimeoutTime" BU_SG_REL_ VCM SG_ 1451 BatterySOHCapa1_1B 24000;
BA_REL_ "GenSigTimeoutTime" BU_SG_REL_ VCM SG_ 1451 BatterySOHCapa1_1B 6000;
BA_REL_ "GenSigFirstTimeoutTime" BU_SG_REL_ VCM SG_ 1451 BatteryReconnectionDetect_1B 24000;
BA_REL_ "GenSigTimeoutTime" BU_SG_REL_ VCM SG_ 1451 BatteryReconnectionDetect_1B 6000;
BA_REL_ "GenSigFirstTimeoutTime" BU_SG_REL_ VCM SG_ 1451 EndOfDischargeStatus1_1B 24000;
BA_REL_ "GenSigTimeoutTime" BU_SG_REL_ VCM SG_ 1451 EndOfDischargeStatus1_1B 6000;
BA_REL_ "GenSigFirstTimeoutTime" BU_SG_REL_ VCM SG_ 1451 DeepDischargestatus_1B 24000;
BA_REL_ "GenSigTimeoutTime" BU_SG_REL_ VCM SG_ 1451 DeepDischargestatus_1B 6000;
BA_REL_ "GenSigFirstTimeoutTime" BU_SG_REL_ VCM SG_ 1451 BatteryTempCo_1B 24000;
BA_REL_ "GenSigTimeoutTime" BU_SG_REL_ VCM SG_ 1451 BatteryTempCo_1B 6000;
BA_REL_ "GenSigFirstTimeoutTime" BU_SG_REL_ VCM SG_ 1451 BatterySOHPower1_1B 24000;
BA_REL_ "GenSigTimeoutTime" BU_SG_REL_ VCM SG_ 1451 BatterySOHPower1_1B 6000;
BA_REL_ "GenSigFirstTimeoutTime" BU_SG_REL_ VCM SG_ 1451 BatterySOHPowerTrustLevel1_1B 24000;
BA_REL_ "GenSigTimeoutTime" BU_SG_REL_ VCM SG_ 1451 BatterySOHPowerTrustLevel1_1B 6000;
BA_REL_ "GenSigFirstTimeoutTime" BU_SG_REL_ VCM SG_ 1449 BatterySOHTrustLevel_stat1_2A 24000;
BA_REL_ "GenSigTimeoutTime" BU_SG_REL_ VCM SG_ 1449 BatterySOHTrustLevel_stat1_2A 6000;
BA_REL_ "GenSigFirstTimeoutTime" BU_SG_REL_ VCM SG_ 1449 BatterySOHPower1_2A 24000;
BA_REL_ "GenSigTimeoutTime" BU_SG_REL_ VCM SG_ 1449 BatterySOHPower1_2A 6000;
BA_REL_ "GenSigFirstTimeoutTime" BU_SG_REL_ VCM SG_ 1449 BatterySOHPowerTrustLevel1_2A 24000;
BA_REL_ "GenSigTimeoutTime" BU_SG_REL_ VCM SG_ 1449 BatterySOHPowerTrustLevel1_2A 6000;
BA_REL_ "GenSigFirstTimeoutTime" BU_SG_REL_ VCM SG_ 1449 BatterySOHCapa1_2A 24000;
BA_REL_ "GenSigTimeoutTime" BU_SG_REL_ VCM SG_ 1449 BatterySOHCapa1_2A 6000;
BA_REL_ "GenSigFirstTimeoutTime" BU_SG_REL_ VCM SG_ 1449 BatteryTempCo_2A 24000;
BA_REL_ "GenSigTimeoutTime" BU_SG_REL_ VCM SG_ 1449 BatteryTempCo_2A 6000;
BA_REL_ "GenSigFirstTimeoutTime" BU_SG_REL_ VCM SG_ 1449 EndOfDischargeStatus1_2A 24000;
BA_REL_ "GenSigTimeoutTime" BU_SG_REL_ VCM SG_ 1449 EndOfDischargeStatus1_2A 6000;
BA_REL_ "GenSigFirstTimeoutTime" BU_SG_REL_ VCM SG_ 1449 BatterySoCcrankLimit1_2A 24000;
BA_REL_ "GenSigTimeoutTime" BU_SG_REL_ VCM SG_ 1449 BatterySoCcrankLimit1_2A 6000;
BA_REL_ "GenSigFirstTimeoutTime" BU_SG_REL_ VCM SG_ 1449 BatterySOCTrustLevel_stat1_2A 24000;
BA_REL_ "GenSigTimeoutTime" BU_SG_REL_ VCM SG_ 1449 BatterySOCTrustLevel_stat1_2A 6000;
BA_REL_ "GenSigFirstTimeoutTime" BU_SG_REL_ VCM SG_ 1449 BatteryExchangeDetect_2A 24000;
BA_REL_ "GenSigTimeoutTime" BU_SG_REL_ VCM SG_ 1449 BatteryExchangeDetect_2A 6000;
BA_REL_ "GenSigFirstTimeoutTime" BU_SG_REL_ VCM SG_ 1449 DeepDischargestatus_2A 24000;
BA_REL_ "GenSigTimeoutTime" BU_SG_REL_ VCM SG_ 1449 DeepDischargestatus_2A 6000;
BA_REL_ "GenSigFirstTimeoutTime" BU_SG_REL_ VCM SG_ 1449 BatteryReconnectionDetect_2A 24000;
BA_REL_ "GenSigTimeoutTime" BU_SG_REL_ VCM SG_ 1449 BatteryReconnectionDetect_2A 6000;
BA_REL_ "GenSigFirstTimeoutTime" BU_SG_REL_ VCM SG_ 1449 Endofchargestatus1_2A 24000;
BA_REL_ "GenSigTimeoutTime" BU_SG_REL_ VCM SG_ 1449 Endofchargestatus1_2A 6000;
BA_REL_ "GenSigFirstTimeoutTime" BU_SG_REL_ VCM SG_ 1447 BatteryExchangeDetect_2B 24000;
BA_REL_ "GenSigTimeoutTime" BU_SG_REL_ VCM SG_ 1447 BatteryExchangeDetect_2B 6000;
BA_REL_ "GenSigFirstTimeoutTime" BU_SG_REL_ VCM SG_ 1447 BatterySOHPowerTrustLevel1_2B 24000;
BA_REL_ "GenSigTimeoutTime" BU_SG_REL_ VCM SG_ 1447 BatterySOHPowerTrustLevel1_2B 6000;
BA_REL_ "GenSigFirstTimeoutTime" BU_SG_REL_ VCM SG_ 1447 Endofchargestatus1_2B 24000;
BA_REL_ "GenSigTimeoutTime" BU_SG_REL_ VCM SG_ 1447 Endofchargestatus1_2B 6000;
BA_REL_ "GenSigFirstTimeoutTime" BU_SG_REL_ VCM SG_ 1447 BatteryTempCo_2B 24000;
BA_REL_ "GenSigTimeoutTime" BU_SG_REL_ VCM SG_ 1447 BatteryTempCo_2B 6000;
BA_REL_ "GenSigFirstTimeoutTime" BU_SG_REL_ VCM SG_ 1447 BatterySOHCapa1_2B 24000;
BA_REL_ "GenSigTimeoutTime" BU_SG_REL_ VCM SG_ 1447 BatterySOHCapa1_2B 6000;
BA_REL_ "GenSigFirstTimeoutTime" BU_SG_REL_ VCM SG_ 1447 BatterySOHPower1_2B 24000;
BA_REL_ "GenSigTimeoutTime" BU_SG_REL_ VCM SG_ 1447 BatterySOHPower1_2B 6000;
BA_REL_ "GenSigFirstTimeoutTime" BU_SG_REL_ VCM SG_ 1447 BatteryReconnectionDetect_2B 24000;
BA_REL_ "GenSigTimeoutTime" BU_SG_REL_ VCM SG_ 1447 BatteryReconnectionDetect_2B 6000;
BA_REL_ "GenSigFirstTimeoutTime" BU_SG_REL_ VCM SG_ 1447 BatterySOHTrustLevel_stat1_2B 24000;
BA_REL_ "GenSigTimeoutTime" BU_SG_REL_ VCM SG_ 1447 BatterySOHTrustLevel_stat1_2B 6000;
BA_REL_ "GenSigFirstTimeoutTime" BU_SG_REL_ VCM SG_ 1447 BatterySoCcrankLimit1_2B 24000;
BA_REL_ "GenSigTimeoutTime" BU_SG_REL_ VCM SG_ 1447 BatterySoCcrankLimit1_2B 6000;
BA_REL_ "GenSigFirstTimeoutTime" BU_SG_REL_ VCM SG_ 1447 DeepDischargestatus_2B 24000;
BA_REL_ "GenSigTimeoutTime" BU_SG_REL_ VCM SG_ 1447 DeepDischargestatus_2B 6000;
BA_REL_ "GenSigFirstTimeoutTime" BU_SG_REL_ VCM SG_ 1447 EndOfDischargeStatus1_2B 24000;
BA_REL_ "GenSigTimeoutTime" BU_SG_REL_ VCM SG_ 1447 EndOfDischargeStatus1_2B 6000;
BA_REL_ "GenSigFirstTimeoutTime" BU_SG_REL_ VCM SG_ 1447 BatterySOCTrustLevel_stat1_2B 24000;
BA_REL_ "GenSigTimeoutTime" BU_SG_REL_ VCM SG_ 1447 BatterySOCTrustLevel_stat1_2B 6000;
BA_REL_ "GenSigFirstTimeoutTime" BU_SG_REL_ VCM SG_ 1445 BatterySOHPowerTrustLevel1_3A 24000;
BA_REL_ "GenSigTimeoutTime" BU_SG_REL_ VCM SG_ 1445 BatterySOHPowerTrustLevel1_3A 6000;
BA_REL_ "GenSigFirstTimeoutTime" BU_SG_REL_ VCM SG_ 1445 BatteryExchangeDetect_3A 24000;
BA_REL_ "GenSigTimeoutTime" BU_SG_REL_ VCM SG_ 1445 BatteryExchangeDetect_3A 6000;
BA_REL_ "GenSigFirstTimeoutTime" BU_SG_REL_ VCM SG_ 1445 Endofchargestatus1_3A 24000;
BA_REL_ "GenSigTimeoutTime" BU_SG_REL_ VCM SG_ 1445 Endofchargestatus1_3A 6000;
BA_REL_ "GenSigFirstTimeoutTime" BU_SG_REL_ VCM SG_ 1445 BatteryTempCo_3A 24000;
BA_REL_ "GenSigTimeoutTime" BU_SG_REL_ VCM SG_ 1445 BatteryTempCo_3A 6000;
BA_REL_ "GenSigFirstTimeoutTime" BU_SG_REL_ VCM SG_ 1445 BatterySoCcrankLimit1_3A 24000;
BA_REL_ "GenSigTimeoutTime" BU_SG_REL_ VCM SG_ 1445 BatterySoCcrankLimit1_3A 6000;
BA_REL_ "GenSigFirstTimeoutTime" BU_SG_REL_ VCM SG_ 1445 BatteryReconnectionDetect_3A 24000;
BA_REL_ "GenSigTimeoutTime" BU_SG_REL_ VCM SG_ 1445 BatteryReconnectionDetect_3A 6000;
BA_REL_ "GenSigFirstTimeoutTime" BU_SG_REL_ VCM SG_ 1445 BatterySOHTrustLevel_stat1_3A 24000;
BA_REL_ "GenSigTimeoutTime" BU_SG_REL_ VCM SG_ 1445 BatterySOHTrustLevel_stat1_3A 6000;
BA_REL_ "GenSigFirstTimeoutTime" BU_SG_REL_ VCM SG_ 1445 DeepDischargestatus_3A 24000;
BA_REL_ "GenSigTimeoutTime" BU_SG_REL_ VCM SG_ 1445 DeepDischargestatus_3A 6000;
BA_REL_ "GenSigFirstTimeoutTime" BU_SG_REL_ VCM SG_ 1445 BatterySOHPower1_3A 24000;
BA_REL_ "GenSigTimeoutTime" BU_SG_REL_ VCM SG_ 1445 BatterySOHPower1_3A 6000;
BA_REL_ "GenSigFirstTimeoutTime" BU_SG_REL_ VCM SG_ 1445 BatterySOCTrustLevel_stat1_3A 24000;
BA_REL_ "GenSigTimeoutTime" BU_SG_REL_ VCM SG_ 1445 BatterySOCTrustLevel_stat1_3A 6000;
BA_REL_ "GenSigFirstTimeoutTime" BU_SG_REL_ VCM SG_ 1445 EndOfDischargeStatus1_3A 24000;
BA_REL_ "GenSigTimeoutTime" BU_SG_REL_ VCM SG_ 1445 EndOfDischargeStatus1_3A 6000;
BA_REL_ "GenSigFirstTimeoutTime" BU_SG_REL_ VCM SG_ 1445 BatterySOHCapa1_3A 24000;
BA_REL_ "GenSigTimeoutTime" BU_SG_REL_ VCM SG_ 1445 BatterySOHCapa1_3A 6000;
BA_REL_ "GenSigFirstTimeoutTime" BU_SG_REL_ VCM SG_ 1443 BatteryTempCo_3B 24000;
BA_REL_ "GenSigTimeoutTime" BU_SG_REL_ VCM SG_ 1443 BatteryTempCo_3B 6000;
BA_REL_ "GenSigFirstTimeoutTime" BU_SG_REL_ VCM SG_ 1443 BatterySoCcrankLimit1_3B 24000;
BA_REL_ "GenSigTimeoutTime" BU_SG_REL_ VCM SG_ 1443 BatterySoCcrankLimit1_3B 6000;
BA_REL_ "GenSigFirstTimeoutTime" BU_SG_REL_ VCM SG_ 1443 BatterySOHPower1_3B 24000;
BA_REL_ "GenSigTimeoutTime" BU_SG_REL_ VCM SG_ 1443 BatterySOHPower1_3B 6000;
BA_REL_ "GenSigFirstTimeoutTime" BU_SG_REL_ VCM SG_ 1443 BatterySOHCapa1_3B 24000;
BA_REL_ "GenSigTimeoutTime" BU_SG_REL_ VCM SG_ 1443 BatterySOHCapa1_3B 6000;
BA_REL_ "GenSigFirstTimeoutTime" BU_SG_REL_ VCM SG_ 1443 EndOfDischargeStatus1_3B 24000;
BA_REL_ "GenSigTimeoutTime" BU_SG_REL_ VCM SG_ 1443 EndOfDischargeStatus1_3B 6000;
BA_REL_ "GenSigFirstTimeoutTime" BU_SG_REL_ VCM SG_ 1443 BatterySOCTrustLevel_stat1_3B 24000;
BA_REL_ "GenSigTimeoutTime" BU_SG_REL_ VCM SG_ 1443 BatterySOCTrustLevel_stat1_3B 6000;
BA_REL_ "GenSigFirstTimeoutTime" BU_SG_REL_ VCM SG_ 1443 BatteryReconnectionDetect_3B 24000;
BA_REL_ "GenSigTimeoutTime" BU_SG_REL_ VCM SG_ 1443 BatteryReconnectionDetect_3B 6000;
BA_REL_ "GenSigFirstTimeoutTime" BU_SG_REL_ VCM SG_ 1443 DeepDischargestatus_3B 24000;
BA_REL_ "GenSigTimeoutTime" BU_SG_REL_ VCM SG_ 1443 DeepDischargestatus_3B 6000;
BA_REL_ "GenSigFirstTimeoutTime" BU_SG_REL_ VCM SG_ 1443 BatterySOHPowerTrustLevel1_3B 24000;
BA_REL_ "GenSigTimeoutTime" BU_SG_REL_ VCM SG_ 1443 BatterySOHPowerTrustLevel1_3B 6000;
BA_REL_ "GenSigFirstTimeoutTime" BU_SG_REL_ VCM SG_ 1443 BatterySOHTrustLevel_stat1_3B 24000;
BA_REL_ "GenSigTimeoutTime" BU_SG_REL_ VCM SG_ 1443 BatterySOHTrustLevel_stat1_3B 6000;
BA_REL_ "GenSigFirstTimeoutTime" BU_SG_REL_ VCM SG_ 1443 BatteryExchangeDetect_3B 24000;
BA_REL_ "GenSigTimeoutTime" BU_SG_REL_ VCM SG_ 1443 BatteryExchangeDetect_3B 6000;
BA_REL_ "GenSigFirstTimeoutTime" BU_SG_REL_ VCM SG_ 1443 Endofchargestatus1_3B 24000;
BA_REL_ "GenSigTimeoutTime" BU_SG_REL_ VCM SG_ 1443 Endofchargestatus1_3B 6000;
BA_REL_ "GenSigFirstTimeoutTime" BU_SG_REL_ VCM SG_ 1441 BatterySOCTrustLevel_stat2_1 24000;
BA_REL_ "GenSigTimeoutTime" BU_SG_REL_ VCM SG_ 1441 BatterySOCTrustLevel_stat2_1 6000;
BA_REL_ "GenSigFirstTimeoutTime" BU_SG_REL_ VCM SG_ 1441 BatterySOCTLWeak_ISig_4 24000;
BA_REL_ "GenSigTimeoutTime" BU_SG_REL_ VCM SG_ 1441 BatterySOCTLWeak_ISig_4 6000;
BA_REL_ "GenSigFirstTimeoutTime" BU_SG_REL_ VCM SG_ 1441 BatterySOHCapaTLWeak 24000;
BA_REL_ "GenSigTimeoutTime" BU_SG_REL_ VCM SG_ 1441 BatterySOHCapaTLWeak 6000;
BA_REL_ "GenSigFirstTimeoutTime" BU_SG_REL_ VCM SG_ 1441 BatterySOHTrustLevel_stat2_1 24000;
BA_REL_ "GenSigTimeoutTime" BU_SG_REL_ VCM SG_ 1441 BatterySOHTrustLevel_stat2_1 6000;
BA_REL_ "GenSigFirstTimeoutTime" BU_SG_REL_ VCM SG_ 1441 Endofchargestatus2_1 24000;
BA_REL_ "GenSigTimeoutTime" BU_SG_REL_ VCM SG_ 1441 Endofchargestatus2_1 6000;
BA_REL_ "GenSigFirstTimeoutTime" BU_SG_REL_ VCM SG_ 1441 BatterySOHPower2_1 24000;
BA_REL_ "GenSigTimeoutTime" BU_SG_REL_ VCM SG_ 1441 BatterySOHPower2_1 6000;
BA_REL_ "GenSigFirstTimeoutTime" BU_SG_REL_ VCM SG_ 1441 BatterySOHPowerTrustLevel2_1 24000;
BA_REL_ "GenSigTimeoutTime" BU_SG_REL_ VCM SG_ 1441 BatterySOHPowerTrustLevel2_1 6000;
BA_REL_ "GenSigFirstTimeoutTime" BU_SG_REL_ VCM SG_ 1441 EndOfDischargeStatus2_1 24000;
BA_REL_ "GenSigTimeoutTime" BU_SG_REL_ VCM SG_ 1441 EndOfDischargeStatus2_1 6000;
BA_REL_ "GenSigFirstTimeoutTime" BU_SG_REL_ VCM SG_ 1441 AirIntakeValve_DiagStatus 24000;
BA_REL_ "GenSigTimeoutTime" BU_SG_REL_ VCM SG_ 1441 AirIntakeValve_DiagStatus 6000;
BA_REL_ "GenSigFirstTimeoutTime" BU_SG_REL_ VCM SG_ 1441 BatterySoCcrankLimit2_1 24000;
BA_REL_ "GenSigTimeoutTime" BU_SG_REL_ VCM SG_ 1441 BatterySoCcrankLimit2_1 6000;
BA_REL_ "GenSigFirstTimeoutTime" BU_SG_REL_ VCM SG_ 1441 BatterySOHCapa2_1 24000;
BA_REL_ "GenSigTimeoutTime" BU_SG_REL_ VCM SG_ 1441 BatterySOHCapa2_1 6000;
BA_REL_ "GenSigFirstTimeoutTime" BU_SG_REL_ BPMU SG_ 1382 BPMU_Conv1_CurrentSetPt 4800;
BA_REL_ "GenSigTimeoutTime" BU_SG_REL_ BPMU SG_ 1382 BPMU_Conv1_CurrentSetPt 1200;
BA_REL_ "GenSigFirstTimeoutTime" BU_SG_REL_ BPMU SG_ 1382 BPMU_VoltageRefSwitchCmd 4800;
BA_REL_ "GenSigTimeoutTime" BU_SG_REL_ BPMU SG_ 1382 BPMU_VoltageRefSwitchCmd 1200;
BA_REL_ "GenSigFirstTimeoutTime" BU_SG_REL_ BPMU SG_ 1382 BPMU_Conv1_VoltageSetPt2 4800;
BA_REL_ "GenSigTimeoutTime" BU_SG_REL_ BPMU SG_ 1382 BPMU_Conv1_VoltageSetPt2 1200;
BA_REL_ "GenSigFirstTimeoutTime" BU_SG_REL_ BPMU SG_ 1382 BPMU_Conv1_VoltageSetPt1 4800;
BA_REL_ "GenSigTimeoutTime" BU_SG_REL_ BPMU SG_ 1382 BPMU_Conv1_VoltageSetPt1 1200;
BA_REL_ "GenSigFirstTimeoutTime" BU_SG_REL_ BPMU SG_ 1382 BPMU_Conv1_TargetOn 4800;
BA_REL_ "GenSigTimeoutTime" BU_SG_REL_ BPMU SG_ 1382 BPMU_Conv1_TargetOn 1200;
BA_REL_ "GenSigFirstTimeoutTime" BU_SG_REL_ VCM SG_ 956 BatteryCurrentHSB 3000;
BA_REL_ "GenSigTimeoutTime" BU_SG_REL_ VCM SG_ 956 BatteryCurrentHSB 600;
BA_REL_ "GenSigFirstTimeoutTime" BU_SG_REL_ VCM SG_ 956 BatteryEndOfChargeHSB_ISig_4 3000;
BA_REL_ "GenSigTimeoutTime" BU_SG_REL_ VCM SG_ 956 BatteryEndOfChargeHSB_ISig_4 600;
BA_REL_ "GenSigFirstTimeoutTime" BU_SG_REL_ VCM SG_ 956 Pto1RequestFeedback 3000;
BA_REL_ "GenSigTimeoutTime" BU_SG_REL_ VCM SG_ 956 Pto1RequestFeedback 600;
BA_REL_ "GenSigFirstTimeoutTime" BU_SG_REL_ VCM SG_ 956 StratificationStatusHSB 3000;
BA_REL_ "GenSigTimeoutTime" BU_SG_REL_ VCM SG_ 956 StratificationStatusHSB 600;
BA_REL_ "GenSigFirstTimeoutTime" BU_SG_REL_ VCM SG_ 956 AutoLoadCutOffState_ISig_4 3000;
BA_REL_ "GenSigTimeoutTime" BU_SG_REL_ VCM SG_ 956 AutoLoadCutOffState_ISig_4 600;
BA_REL_ "GenSigFirstTimeoutTime" BU_SG_REL_ VCM SG_ 956 BatteryEndOfChargeLSB_ISig_4 3000;
BA_REL_ "GenSigTimeoutTime" BU_SG_REL_ VCM SG_ 956 BatteryEndOfChargeLSB_ISig_4 600;
BA_REL_ "GenSigFirstTimeoutTime" BU_SG_REL_ RCIOM SG_ 956 FrontTargetLevelReached 3000;
BA_REL_ "GenSigTimeoutTime" BU_SG_REL_ RCIOM SG_ 956 FrontTargetLevelReached 600;
BA_REL_ "GenSigFirstTimeoutTime" BU_SG_REL_ VCM SG_ 956 FrontTargetLevelReached 3000;
BA_REL_ "GenSigTimeoutTime" BU_SG_REL_ VCM SG_ 956 FrontTargetLevelReached 600;
BA_REL_ "GenSigFirstTimeoutTime" BU_SG_REL_ VCM SG_ 956 Ultracap_Status_ISig_4 3000;
BA_REL_ "GenSigTimeoutTime" BU_SG_REL_ VCM SG_ 956 Ultracap_Status_ISig_4 600;
BA_REL_ "GenSigFirstTimeoutTime" BU_SG_REL_ VCM SG_ 956 AdditionEnergySourceNeeded24V 3000;
BA_REL_ "GenSigTimeoutTime" BU_SG_REL_ VCM SG_ 956 AdditionEnergySourceNeeded24V 600;
BA_REL_ "GenSigFirstTimeoutTime" BU_SG_REL_ VCM SG_ 956 Pto2RequestFeedback 3000;
BA_REL_ "GenSigTimeoutTime" BU_SG_REL_ VCM SG_ 956 Pto2RequestFeedback 600;
BA_REL_ "GenSigFirstTimeoutTime" BU_SG_REL_ VCM SG_ 956 UltracapDisplay_Stat_ISig_4 3000;
BA_REL_ "GenSigTimeoutTime" BU_SG_REL_ VCM SG_ 956 UltracapDisplay_Stat_ISig_4 600;
BA_REL_ "GenSigFirstTimeoutTime" BU_SG_REL_ VCM SG_ 956 RemainingNrOfCrank24V 3000;
BA_REL_ "GenSigTimeoutTime" BU_SG_REL_ VCM SG_ 956 RemainingNrOfCrank24V 600;
BA_REL_ "GenSigFirstTimeoutTime" BU_SG_REL_ VCM SG_ 956 StratificationStatusLSB 3000;
BA_REL_ "GenSigTimeoutTime" BU_SG_REL_ VCM SG_ 956 StratificationStatusLSB 600;
BA_REL_ "GenSigFirstTimeoutTime" BU_SG_REL_ BPMU SG_ 1313 BPMU_Conv2_VoltageSetPt2 4800;
BA_REL_ "GenSigTimeoutTime" BU_SG_REL_ BPMU SG_ 1313 BPMU_Conv2_VoltageSetPt2 1200;
BA_REL_ "GenSigFirstTimeoutTime" BU_SG_REL_ BPMU SG_ 1313 BPMU_Conv2_TargetOn 4800;
BA_REL_ "GenSigTimeoutTime" BU_SG_REL_ BPMU SG_ 1313 BPMU_Conv2_TargetOn 1200;
BA_REL_ "GenSigFirstTimeoutTime" BU_SG_REL_ BPMU SG_ 1313 BPMU_Conv2_VoltageSetPt1 4800;
BA_REL_ "GenSigTimeoutTime" BU_SG_REL_ BPMU SG_ 1313 BPMU_Conv2_VoltageSetPt1 1200;
BA_REL_ "GenSigFirstTimeoutTime" BU_SG_REL_ BPMU SG_ 1313 BPMU_Conv2_CurrentSetPt 4800;
BA_REL_ "GenSigTimeoutTime" BU_SG_REL_ BPMU SG_ 1313 BPMU_Conv2_CurrentSetPt 1200;
BA_REL_ "GenSigFirstTimeoutTime" BU_SG_REL_ VCM SG_ 1251 ExtraBBKingPinFeedback 3000;
BA_REL_ "GenSigTimeoutTime" BU_SG_REL_ VCM SG_ 1251 ExtraBBKingPinFeedback 600;
BA_REL_ "GenSigFirstTimeoutTime" BU_SG_REL_ VCM SG_ 1251 DiffLockInterWhlStatusFrAxle2 3000;
BA_REL_ "GenSigTimeoutTime" BU_SG_REL_ VCM SG_ 1251 DiffLockInterWhlStatusFrAxle2 600;
BA_REL_ "GenSigFirstTimeoutTime" BU_SG_REL_ VCM SG_ 1251 PluggedVehicleWakeUp_rqst 3000;
BA_REL_ "GenSigTimeoutTime" BU_SG_REL_ VCM SG_ 1251 PluggedVehicleWakeUp_rqst 600;
BA_REL_ "GenSigFirstTimeoutTime" BU_SG_REL_ VCM SG_ 1251 GearRangeUnengaged_ISig_4 3000;
BA_REL_ "GenSigTimeoutTime" BU_SG_REL_ VCM SG_ 1251 GearRangeUnengaged_ISig_4 600;
BA_REL_ "GenSigFirstTimeoutTime" BU_SG_REL_ VCM SG_ 1251 BatterySensorVoltage 3000;
BA_REL_ "GenSigTimeoutTime" BU_SG_REL_ VCM SG_ 1251 BatterySensorVoltage 600;
BA_REL_ "GenSigFirstTimeoutTime" BU_SG_REL_ VCM SG_ 1251 GChargerStatus_ISig_4 3000;
BA_REL_ "GenSigTimeoutTime" BU_SG_REL_ VCM SG_ 1251 GChargerStatus_ISig_4 600;
BA_REL_ "GenSigFirstTimeoutTime" BU_SG_REL_ VCM SG_ 1251 LivBatteryCharging_stat_ISig_4 3000;
BA_REL_ "GenSigTimeoutTime" BU_SG_REL_ VCM SG_ 1251 LivBatteryCharging_stat_ISig_4 600;
BA_REL_ "GenSigFirstTimeoutTime" BU_SG_REL_ RCIOM SG_ 1251 FrontFactorySupportModeStatus 3000;
BA_REL_ "GenSigTimeoutTime" BU_SG_REL_ RCIOM SG_ 1251 FrontFactorySupportModeStatus 600;
BA_REL_ "GenSigFirstTimeoutTime" BU_SG_REL_ VCM SG_ 1251 FrontFactorySupportModeStatus 3000;
BA_REL_ "GenSigTimeoutTime" BU_SG_REL_ VCM SG_ 1251 FrontFactorySupportModeStatus 600;
BA_REL_ "GenSigFirstTimeoutTime" BU_SG_REL_ VCM SG_ 1251 LivBatDisconnectDetectStat_ISig_ 3000;
BA_REL_ "GenSigTimeoutTime" BU_SG_REL_ VCM SG_ 1251 LivBatDisconnectDetectStat_ISig_ 600;
BA_REL_ "GenSigFirstTimeoutTime" BU_SG_REL_ VCM SG_ 1251 SideMarkersLight4_FailStat 3000;
BA_REL_ "GenSigTimeoutTime" BU_SG_REL_ VCM SG_ 1251 SideMarkersLight4_FailStat 600;
BA_REL_ "GenSigFirstTimeoutTime" BU_SG_REL_ VCM SG_ 1251 DiffLockInterWhlStatSplitBox2 3000;
BA_REL_ "GenSigTimeoutTime" BU_SG_REL_ VCM SG_ 1251 DiffLockInterWhlStatSplitBox2 600;
BA_REL_ "GenSigFirstTimeoutTime" BU_SG_REL_ VCM SG_ 1251 StratificationStatus 3000;
BA_REL_ "GenSigTimeoutTime" BU_SG_REL_ VCM SG_ 1251 StratificationStatus 600;
BA_REL_ "GenSigFirstTimeoutTime" BU_SG_REL_ VCM SG_ 1251 Cab12VSupplyStatus_ISig_4 3000;
BA_REL_ "GenSigTimeoutTime" BU_SG_REL_ VCM SG_ 1251 Cab12VSupplyStatus_ISig_4 600;
BA_REL_ "GenSigFirstTimeoutTime" BU_SG_REL_ VCM SG_ 1251 BatterySensorVoltageFiltered 3000;
BA_REL_ "GenSigTimeoutTime" BU_SG_REL_ VCM SG_ 1251 BatterySensorVoltageFiltered 600;
BA_REL_ "GenSigFirstTimeoutTime" BU_SG_REL_ RCIOM SG_ 1251 FrontOffsetLampCalib 3000;
BA_REL_ "GenSigTimeoutTime" BU_SG_REL_ RCIOM SG_ 1251 FrontOffsetLampCalib 600;
BA_REL_ "GenSigFirstTimeoutTime" BU_SG_REL_ VCM SG_ 1251 FrontOffsetLampCalib 3000;
BA_REL_ "GenSigTimeoutTime" BU_SG_REL_ VCM SG_ 1251 FrontOffsetLampCalib 600;
BA_REL_ "GenSigFirstTimeoutTime" BU_SG_REL_ VCM SG_ 1242 RelativeLevelFrontAxleRightRaw 3000;
BA_REL_ "GenSigTimeoutTime" BU_SG_REL_ VCM SG_ 1242 RelativeLevelFrontAxleRightRaw 300;
BA_REL_ "GenSigFirstTimeoutTime" BU_SG_REL_ RCIOM SG_ 1242 RelativeLevelFrontAxleRightRaw 3000;
BA_REL_ "GenSigTimeoutTime" BU_SG_REL_ RCIOM SG_ 1242 RelativeLevelFrontAxleRightRaw 300;
BA_REL_ "GenSigFirstTimeoutTime" BU_SG_REL_ VCM SG_ 1242 BatteryTemp_ISig_4 3000;
BA_REL_ "GenSigTimeoutTime" BU_SG_REL_ VCM SG_ 1242 BatteryTemp_ISig_4 300;
BA_REL_ "GenSigFirstTimeoutTime" BU_SG_REL_ VCM SG_ 1242 BatterySOCactCriticalAlert_ISig_ 3000;
BA_REL_ "GenSigTimeoutTime" BU_SG_REL_ VCM SG_ 1242 BatterySOCactCriticalAlert_ISig_ 300;
BA_REL_ "GenSigFirstTimeoutTime" BU_SG_REL_ RCIOM SG_ 1242 RelativeLevelFrontAxleLeftRaw 3000;
BA_REL_ "GenSigTimeoutTime" BU_SG_REL_ RCIOM SG_ 1242 RelativeLevelFrontAxleLeftRaw 300;
BA_REL_ "GenSigFirstTimeoutTime" BU_SG_REL_ VCM SG_ 1242 RelativeLevelFrontAxleLeftRaw 3000;
BA_REL_ "GenSigTimeoutTime" BU_SG_REL_ VCM SG_ 1242 RelativeLevelFrontAxleLeftRaw 300;
BA_REL_ "GenSigFirstTimeoutTime" BU_SG_REL_ VCM SG_ 1242 BatteryTempAlertRawData_rqst_ISi 3000;
BA_REL_ "GenSigTimeoutTime" BU_SG_REL_ VCM SG_ 1242 BatteryTempAlertRawData_rqst_ISi 300;
BA_REL_ "GenSigFirstTimeoutTime" BU_SG_REL_ VCM SG_ 1242 BatterySOCact_ISig_4 3000;
BA_REL_ "GenSigTimeoutTime" BU_SG_REL_ VCM SG_ 1242 BatterySOCact_ISig_4 300;
BA_REL_ "GenSigFirstTimeoutTime" BU_SG_REL_ VCM SG_ 1242 BatteryTempAlert_rqst_ISig_4 3000;
BA_REL_ "GenSigTimeoutTime" BU_SG_REL_ VCM SG_ 1242 BatteryTempAlert_rqst_ISig_4 300;
BA_REL_ "GenSigFirstTimeoutTime" BU_SG_REL_ VCM SG_ 1510 ECSFrontCRC_Status 48000;
BA_REL_ "GenSigTimeoutTime" BU_SG_REL_ VCM SG_ 1510 ECSFrontCRC_Status 12000;
BA_REL_ "GenSigFirstTimeoutTime" BU_SG_REL_ RCIOM SG_ 1510 ECSFrontCRC_Status 48000;
BA_REL_ "GenSigTimeoutTime" BU_SG_REL_ RCIOM SG_ 1510 ECSFrontCRC_Status 12000;
BA_REL_ "GenSigFirstTimeoutTime" BU_SG_REL_ VCM SG_ 1510 ECSFrontCRC_CRC 48000;
BA_REL_ "GenSigTimeoutTime" BU_SG_REL_ VCM SG_ 1510 ECSFrontCRC_CRC 12000;
BA_REL_ "GenSigFirstTimeoutTime" BU_SG_REL_ RCIOM SG_ 1510 ECSFrontCRC_CRC 48000;
BA_REL_ "GenSigTimeoutTime" BU_SG_REL_ RCIOM SG_ 1510 ECSFrontCRC_CRC 12000;
BA_REL_ "GenSigFirstTimeoutTime" BU_SG_REL_ VCM SG_ 1510 WantedLBChargingVoltage 48000;
BA_REL_ "GenSigTimeoutTime" BU_SG_REL_ VCM SG_ 1510 WantedLBChargingVoltage 12000;
BA_REL_ "GenSigFirstTimeoutTime" BU_SG_REL_ VCM SG_ 1250 BatterySOH_ISig_4 3000;
BA_REL_ "GenSigTimeoutTime" BU_SG_REL_ VCM SG_ 1250 BatterySOH_ISig_4 600;
BA_REL_ "GenSigFirstTimeoutTime" BU_SG_REL_ VCM SG_ 1250 BatterySOCnom_ISig_4 3000;
BA_REL_ "GenSigTimeoutTime" BU_SG_REL_ VCM SG_ 1250 BatterySOCnom_ISig_4 600;
BA_REL_ "GenSigFirstTimeoutTime" BU_SG_REL_ VCM SG_ 1250 BatterySOHTrustLevel 3000;
BA_REL_ "GenSigTimeoutTime" BU_SG_REL_ VCM SG_ 1250 BatterySOHTrustLevel 600;
BA_REL_ "GenSigFirstTimeoutTime" BU_SG_REL_ VCM SG_ 1250 BatterySOF 3000;
BA_REL_ "GenSigTimeoutTime" BU_SG_REL_ VCM SG_ 1250 BatterySOF 600;
BA_REL_ "GenSigFirstTimeoutTime" BU_SG_REL_ VCM SG_ 1250 BatteryCurrent_ISig_4 3000;
BA_REL_ "GenSigTimeoutTime" BU_SG_REL_ VCM SG_ 1250 BatteryCurrent_ISig_4 600;
BA_REL_ "GenSigFirstTimeoutTime" BU_SG_REL_ VCM SG_ 1250 BatteryVoltageDisplayValue_ISig_ 3000;
BA_REL_ "GenSigTimeoutTime" BU_SG_REL_ VCM SG_ 1250 BatteryVoltageDisplayValue_ISig_ 600;
BA_REL_ "GenSigFirstTimeoutTime" BU_SG_REL_ VCM SG_ 823 FrontLimpHomeTrigger 3000;
BA_REL_ "GenSigTimeoutTime" BU_SG_REL_ VCM SG_ 823 FrontLimpHomeTrigger 180;
BA_REL_ "GenSigFirstTimeoutTime" BU_SG_REL_ RCIOM SG_ 823 FrontLimpHomeTrigger 3000;
BA_REL_ "GenSigTimeoutTime" BU_SG_REL_ RCIOM SG_ 823 FrontLimpHomeTrigger 180;
BA_REL_ "GenSigFirstTimeoutTime" BU_SG_REL_ VCM SG_ 823 TransmLowRangeSenseSwitch_ISig_4 3000;
BA_REL_ "GenSigTimeoutTime" BU_SG_REL_ VCM SG_ 823 TransmLowRangeSenseSwitch_ISig_4 180;
BA_REL_ "GenSigFirstTimeoutTime" BU_SG_REL_ VCM SG_ 823 ElectricalLoadReduction_rqst_ISi 3000;
BA_REL_ "GenSigTimeoutTime" BU_SG_REL_ VCM SG_ 823 ElectricalLoadReduction_rqst_ISi 500;
BA_REL_ "GenSigFirstTimeoutTime" BU_SG_REL_ RCIOM SG_ 823 ElectricalLoadReduction_rqst_ISi 3000;
BA_REL_ "GenSigTimeoutTime" BU_SG_REL_ RCIOM SG_ 823 ElectricalLoadReduction_rqst_ISi 500;
BA_REL_ "GenSigFirstTimeoutTime" BU_SG_REL_ VCM SG_ 823 TransmReverseDirectionSw_stat 3000;
BA_REL_ "GenSigTimeoutTime" BU_SG_REL_ VCM SG_ 823 TransmReverseDirectionSw_stat 180;
BA_REL_ "GenSigFirstTimeoutTime" BU_SG_REL_ VCM SG_ 823 ManTransmiOilTemp_ISig_4 3000;
BA_REL_ "GenSigTimeoutTime" BU_SG_REL_ VCM SG_ 823 ManTransmiOilTemp_ISig_4 500;
BA_REL_ "GenSigFirstTimeoutTime" BU_SG_REL_ VCM SG_ 823 DirInd_MiddleSide_Status 3000;
BA_REL_ "GenSigTimeoutTime" BU_SG_REL_ VCM SG_ 823 DirInd_MiddleSide_Status 180;
BA_REL_ "GenSigFirstTimeoutTime" BU_SG_REL_ VCM SG_ 823 BatterySOCAlert_rqst_ISig_4 3000;
BA_REL_ "GenSigTimeoutTime" BU_SG_REL_ VCM SG_ 823 BatterySOCAlert_rqst_ISig_4 180;
BA_REL_ "GenSigFirstTimeoutTime" BU_SG_REL_ VCM SG_ 823 DoubleFrontAxleSteeringWarning_I 3000;
BA_REL_ "GenSigTimeoutTime" BU_SG_REL_ VCM SG_ 823 DoubleFrontAxleSteeringWarning_I 180;
BA_REL_ "GenSigFirstTimeoutTime" BU_SG_REL_ VCM SG_ 823 DifferentialLockStateCentral_ISi 3000;
BA_REL_ "GenSigTimeoutTime" BU_SG_REL_ VCM SG_ 823 DifferentialLockStateCentral_ISi 180;
BA_REL_ "GenSigFirstTimeoutTime" BU_SG_REL_ RCIOM SG_ 823 FifthWheelLockingInformation_ISi 3000;
BA_REL_ "GenSigTimeoutTime" BU_SG_REL_ RCIOM SG_ 823 FifthWheelLockingInformation_ISi 500;
BA_REL_ "GenSigFirstTimeoutTime" BU_SG_REL_ VCM SG_ 823 FifthWheelLockingInformation_ISi 3000;
BA_REL_ "GenSigTimeoutTime" BU_SG_REL_ VCM SG_ 823 FifthWheelLockingInformation_ISi 500;
BA_REL_ "GenSigFirstTimeoutTime" BU_SG_REL_ VCM SG_ 823 DiffLockInterWhlStatusSplitBox 3000;
BA_REL_ "GenSigTimeoutTime" BU_SG_REL_ VCM SG_ 823 DiffLockInterWhlStatusSplitBox 180;
BA_REL_ "GenSigFirstTimeoutTime" BU_SG_REL_ VCM SG_ 823 WrknLghtChassisOutpFalr_stat 3000;
BA_REL_ "GenSigTimeoutTime" BU_SG_REL_ VCM SG_ 823 WrknLghtChassisOutpFalr_stat 180;
BA_REL_ "GenSigFirstTimeoutTime" BU_SG_REL_ VCM SG_ 823 DifferentialLockStateFrAxle1_ISi 3000;
BA_REL_ "GenSigTimeoutTime" BU_SG_REL_ VCM SG_ 823 DifferentialLockStateFrAxle1_ISi 500;
BA_REL_ "GenSigFirstTimeoutTime" BU_SG_REL_ VCM SG_ 823 GearSplit_Status_ISig_4 3000;
BA_REL_ "GenSigTimeoutTime" BU_SG_REL_ VCM SG_ 823 GearSplit_Status_ISig_4 500;
BA_REL_ "GenSigFirstTimeoutTime" BU_SG_REL_ VCM SG_ 823 LoadCutOffIndication_cmd_ISig_4 3000;
BA_REL_ "GenSigTimeoutTime" BU_SG_REL_ VCM SG_ 823 LoadCutOffIndication_cmd_ISig_4 180;
BA_REL_ "GenSigFirstTimeoutTime" BU_SG_REL_ VCM SG_ 823 FifthWheelHandleLock_ind 3000;
BA_REL_ "GenSigTimeoutTime" BU_SG_REL_ VCM SG_ 823 FifthWheelHandleLock_ind 180;
BA_REL_ "GenSigFirstTimeoutTime" BU_SG_REL_ VCM SG_ 823 BatteryCapacity_Ack_ISig_4 3000;
BA_REL_ "GenSigTimeoutTime" BU_SG_REL_ VCM SG_ 823 BatteryCapacity_Ack_ISig_4 180;
BA_REL_ "GenSigFirstTimeoutTime" BU_SG_REL_ RCIOM SG_ 1244 FrontAxle1Load_ISig_4 3000;
BA_REL_ "GenSigTimeoutTime" BU_SG_REL_ RCIOM SG_ 1244 FrontAxle1Load_ISig_4 600;
BA_REL_ "GenSigFirstTimeoutTime" BU_SG_REL_ VCM SG_ 1244 FrontAxle1Load_ISig_4 3000;
BA_REL_ "GenSigTimeoutTime" BU_SG_REL_ VCM SG_ 1244 FrontAxle1Load_ISig_4 600;
BA_REL_ "GenSigFirstTimeoutTime" BU_SG_REL_ VCM SG_ 1244 EqualizerUnbalance_ISig_4 3000;
BA_REL_ "GenSigTimeoutTime" BU_SG_REL_ VCM SG_ 1244 EqualizerUnbalance_ISig_4 600;
BA_REL_ "GenSigFirstTimeoutTime" BU_SG_REL_ RCIOM SG_ 1244 FrontAxle2Load_ISig_4 3000;
BA_REL_ "GenSigTimeoutTime" BU_SG_REL_ RCIOM SG_ 1244 FrontAxle2Load_ISig_4 600;
BA_REL_ "GenSigFirstTimeoutTime" BU_SG_REL_ VCM SG_ 1244 FrontAxle2Load_ISig_4 3000;
BA_REL_ "GenSigTimeoutTime" BU_SG_REL_ VCM SG_ 1244 FrontAxle2Load_ISig_4 600;
BA_REL_ "GenSigFirstTimeoutTime" BU_SG_REL_ VCM SG_ 1244 ShortStopHeater_status_ISig_4 3000;
BA_REL_ "GenSigTimeoutTime" BU_SG_REL_ VCM SG_ 1244 ShortStopHeater_status_ISig_4 600;
BA_REL_ "GenSigFirstTimeoutTime" BU_SG_REL_ VCM SG_ 1244 ExtraBBContUnlockFeedback 3000;
BA_REL_ "GenSigTimeoutTime" BU_SG_REL_ VCM SG_ 1244 ExtraBBContUnlockFeedback 600;
BA_REL_ "GenSigFirstTimeoutTime" BU_SG_REL_ VCM SG_ 1244 TrailerRevAndFogOutput_stat_ISig 3000;
BA_REL_ "GenSigTimeoutTime" BU_SG_REL_ VCM SG_ 1244 TrailerRevAndFogOutput_stat_ISig 600;
BA_REL_ "GenSigFirstTimeoutTime" BU_SG_REL_ RCIOM SG_ 1244 TrailerRevAndFogOutput_stat_ISig 3000;
BA_REL_ "GenSigTimeoutTime" BU_SG_REL_ RCIOM SG_ 1244 TrailerRevAndFogOutput_stat_ISig 600;
BA_REL_ "GenSigFirstTimeoutTime" BU_SG_REL_ VCM SG_ 1244 ExtraBBSlidable5WFeedback 3000;
BA_REL_ "GenSigTimeoutTime" BU_SG_REL_ VCM SG_ 1244 ExtraBBSlidable5WFeedback 600;
BA_REL_ "GenSigFirstTimeoutTime" BU_SG_REL_ VCM SG_ 1244 TrailerBrakePres_stat 3000;
BA_REL_ "GenSigTimeoutTime" BU_SG_REL_ VCM SG_ 1244 TrailerBrakePres_stat 600;
BA_REL_ "GenSigFirstTimeoutTime" BU_SG_REL_ VCM SG_ 1244 FrontAxleGrpBellowTorque 3000;
BA_REL_ "GenSigTimeoutTime" BU_SG_REL_ VCM SG_ 1244 FrontAxleGrpBellowTorque 600;
BA_REL_ "GenSigFirstTimeoutTime" BU_SG_REL_ RCIOM SG_ 1244 FrontAxleGrpBellowTorque 3000;
BA_REL_ "GenSigTimeoutTime" BU_SG_REL_ RCIOM SG_ 1244 FrontAxleGrpBellowTorque 600;
BA_REL_ "GenSigFirstTimeoutTime" BU_SG_REL_ RCIOM SG_ 1238 FrontAxleGroupLoad 3000;
BA_REL_ "GenSigTimeoutTime" BU_SG_REL_ RCIOM SG_ 1238 FrontAxleGroupLoad 300;
BA_REL_ "GenSigFirstTimeoutTime" BU_SG_REL_ VCM SG_ 1238 FrontAxleGroupLoad 3000;
BA_REL_ "GenSigTimeoutTime" BU_SG_REL_ VCM SG_ 1238 FrontAxleGroupLoad 300;
BA_REL_ "GenSigFirstTimeoutTime" BU_SG_REL_ RCIOM SG_ 1238 RelativeLevelFrontAxleLeft_ISig_ 3000;
BA_REL_ "GenSigTimeoutTime" BU_SG_REL_ RCIOM SG_ 1238 RelativeLevelFrontAxleLeft_ISig_ 300;
BA_REL_ "GenSigFirstTimeoutTime" BU_SG_REL_ VCM SG_ 1238 RelativeLevelFrontAxleLeft_ISig_ 3000;
BA_REL_ "GenSigTimeoutTime" BU_SG_REL_ VCM SG_ 1238 RelativeLevelFrontAxleLeft_ISig_ 300;
BA_REL_ "GenSigFirstTimeoutTime" BU_SG_REL_ RCIOM SG_ 1238 FrontStabilizerSpringRate 3000;
BA_REL_ "GenSigTimeoutTime" BU_SG_REL_ RCIOM SG_ 1238 FrontStabilizerSpringRate 300;
BA_REL_ "GenSigFirstTimeoutTime" BU_SG_REL_ VCM SG_ 1238 FrontStabilizerSpringRate 3000;
BA_REL_ "GenSigTimeoutTime" BU_SG_REL_ VCM SG_ 1238 FrontStabilizerSpringRate 300;
BA_REL_ "GenSigFirstTimeoutTime" BU_SG_REL_ VCM SG_ 1238 RelativeLevelFrontAxleRight_ISig 3000;
BA_REL_ "GenSigTimeoutTime" BU_SG_REL_ VCM SG_ 1238 RelativeLevelFrontAxleRight_ISig 300;
BA_REL_ "GenSigFirstTimeoutTime" BU_SG_REL_ RCIOM SG_ 1238 RelativeLevelFrontAxleRight_ISig 3000;
BA_REL_ "GenSigTimeoutTime" BU_SG_REL_ RCIOM SG_ 1238 RelativeLevelFrontAxleRight_ISig 300;
BA_REL_ "GenSigFirstTimeoutTime" BU_SG_REL_ VCM SG_ 1237 FrontAxleGrpUsedTorqueRef 3000;
BA_REL_ "GenSigTimeoutTime" BU_SG_REL_ VCM SG_ 1237 FrontAxleGrpUsedTorqueRef 300;
BA_REL_ "GenSigFirstTimeoutTime" BU_SG_REL_ RCIOM SG_ 1237 FrontAxleGrpUsedTorqueRef 3000;
BA_REL_ "GenSigTimeoutTime" BU_SG_REL_ RCIOM SG_ 1237 FrontAxleGrpUsedTorqueRef 300;
BA_REL_ "GenSigFirstTimeoutTime" BU_SG_REL_ RCIOM SG_ 1237 TotalFrBellowTrqMaxCapacity 3000;
BA_REL_ "GenSigTimeoutTime" BU_SG_REL_ RCIOM SG_ 1237 TotalFrBellowTrqMaxCapacity 300;
BA_REL_ "GenSigFirstTimeoutTime" BU_SG_REL_ VCM SG_ 1237 TotalFrBellowTrqMaxCapacity 3000;
BA_REL_ "GenSigTimeoutTime" BU_SG_REL_ VCM SG_ 1237 TotalFrBellowTrqMaxCapacity 300;
BA_REL_ "GenSigFirstTimeoutTime" BU_SG_REL_ RCIOM SG_ 1237 FrontAirDumpStatus 3000;
BA_REL_ "GenSigTimeoutTime" BU_SG_REL_ RCIOM SG_ 1237 FrontAirDumpStatus 300;
BA_REL_ "GenSigFirstTimeoutTime" BU_SG_REL_ VCM SG_ 1237 FrontAirDumpStatus 3000;
BA_REL_ "GenSigTimeoutTime" BU_SG_REL_ VCM SG_ 1237 FrontAirDumpStatus 300;
BA_REL_ "GenSigFirstTimeoutTime" BU_SG_REL_ VCM SG_ 1237 BatterySOCTrustLevel_ISig_4 3000;
BA_REL_ "GenSigTimeoutTime" BU_SG_REL_ VCM SG_ 1237 BatterySOCTrustLevel_ISig_4 300;
BA_REL_ "GenSigFirstTimeoutTime" BU_SG_REL_ VCM SG_ 1237 BatterySOCAlertRawData_rqst_ISig 3000;
BA_REL_ "GenSigTimeoutTime" BU_SG_REL_ VCM SG_ 1237 BatterySOCAlertRawData_rqst_ISig 300;
BA_REL_ "GenSigFirstTimeoutTime" BU_SG_REL_ RCIOM SG_ 1237 TotalFrontLoadTorque 3000;
BA_REL_ "GenSigTimeoutTime" BU_SG_REL_ RCIOM SG_ 1237 TotalFrontLoadTorque 300;
BA_REL_ "GenSigFirstTimeoutTime" BU_SG_REL_ VCM SG_ 1237 TotalFrontLoadTorque 3000;
BA_REL_ "GenSigTimeoutTime" BU_SG_REL_ VCM SG_ 1237 TotalFrontLoadTorque 300;
BA_REL_ "GenSigFirstTimeoutTime" BU_SG_REL_ VCM SG_ 774 Pto1FeedbackStatus 3000;
BA_REL_ "GenSigTimeoutTime" BU_SG_REL_ VCM SG_ 774 Pto1FeedbackStatus 500;
BA_REL_ "GenSigFirstTimeoutTime" BU_SG_REL_ VCM SG_ 774 ReverseGearEngaged_ISig_4 3000;
BA_REL_ "GenSigTimeoutTime" BU_SG_REL_ VCM SG_ 774 ReverseGearEngaged_ISig_4 500;
BA_REL_ "GenSigFirstTimeoutTime" BU_SG_REL_ WSGW SG_ 774 ReverseGearEngaged_ISig_4 3000;
BA_REL_ "GenSigTimeoutTime" BU_SG_REL_ WSGW SG_ 774 ReverseGearEngaged_ISig_4 150;
BA_REL_ "GenSigFirstTimeoutTime" BU_SG_REL_ RCIOM SG_ 774 ReverseGearEngaged_ISig_4 3000;
BA_REL_ "GenSigTimeoutTime" BU_SG_REL_ RCIOM SG_ 774 ReverseGearEngaged_ISig_4 500;
BA_REL_ "GenSigFirstTimeoutTime" BU_SG_REL_ RCIOM SG_ 774 BrakePressureSensorDemand2 3000;
BA_REL_ "GenSigTimeoutTime" BU_SG_REL_ RCIOM SG_ 774 BrakePressureSensorDemand2 600;
BA_REL_ "GenSigFirstTimeoutTime" BU_SG_REL_ VCM SG_ 774 BrakePressureSensorDemand2 3000;
BA_REL_ "GenSigTimeoutTime" BU_SG_REL_ VCM SG_ 774 BrakePressureSensorDemand2 150;
BA_REL_ "GenSigFirstTimeoutTime" BU_SG_REL_ VCM SG_ 774 PneumaticTrailerBrakeStatus_ISig 3000;
BA_REL_ "GenSigTimeoutTime" BU_SG_REL_ VCM SG_ 774 PneumaticTrailerBrakeStatus_ISig 150;
BA_REL_ "GenSigFirstTimeoutTime" BU_SG_REL_ RCIOM SG_ 774 PneumaticTrailerBrakeStatus_ISig 3000;
BA_REL_ "GenSigTimeoutTime" BU_SG_REL_ RCIOM SG_ 774 PneumaticTrailerBrakeStatus_ISig 150;
BA_REL_ "GenSigFirstTimeoutTime" BU_SG_REL_ VCM SG_ 774 SWBrakeSwitch2 3000;
BA_REL_ "GenSigTimeoutTime" BU_SG_REL_ VCM SG_ 774 SWBrakeSwitch2 150;
BA_REL_ "GenSigFirstTimeoutTime" BU_SG_REL_ RCIOM SG_ 774 SWBrakeSwitch2 3000;
BA_REL_ "GenSigTimeoutTime" BU_SG_REL_ RCIOM SG_ 774 SWBrakeSwitch2 600;
BA_REL_ "GenSigFirstTimeoutTime" BU_SG_REL_ VCM SG_ 774 FuelLevel_ISig_4 3000;
BA_REL_ "GenSigTimeoutTime" BU_SG_REL_ VCM SG_ 774 FuelLevel_ISig_4 500;
BA_REL_ "GenSigFirstTimeoutTime" BU_SG_REL_ VCM SG_ 774 NeutralSwitch_stat 3000;
BA_REL_ "GenSigTimeoutTime" BU_SG_REL_ VCM SG_ 774 NeutralSwitch_stat 150;
BA_REL_ "GenSigFirstTimeoutTime" BU_SG_REL_ VCM SG_ 774 MainSwitch_Status 3000;
BA_REL_ "GenSigTimeoutTime" BU_SG_REL_ VCM SG_ 774 MainSwitch_Status 150;
BA_REL_ "GenSigFirstTimeoutTime" BU_SG_REL_ VCM SG_ 774 FuelVolume_ISig_4 3000;
BA_REL_ "GenSigTimeoutTime" BU_SG_REL_ VCM SG_ 774 FuelVolume_ISig_4 500;
BA_REL_ "GenSigFirstTimeoutTime" BU_SG_REL_ CCIOM SG_ 1245 JumpChargeInterface_stat_ISig_4 3000;
BA_REL_ "GenSigTimeoutTime" BU_SG_REL_ CCIOM SG_ 1245 JumpChargeInterface_stat_ISig_4 600;
BA_REL_ "GenSigFirstTimeoutTime" BU_SG_REL_ CCIOM SG_ 1245 GridCharger_stat 3000;
BA_REL_ "GenSigTimeoutTime" BU_SG_REL_ CCIOM SG_ 1245 GridCharger_stat 600;
BA_REL_ "GenSigFirstTimeoutTime" BU_SG_REL_ CCIOM SG_ 1245 StartBatteryDisplay_stat_ISig_4 3000;
BA_REL_ "GenSigTimeoutTime" BU_SG_REL_ CCIOM SG_ 1245 StartBatteryDisplay_stat_ISig_4 600;
BA_REL_ "GenSigFirstTimeoutTime" BU_SG_REL_ CCIOM SG_ 1350 BPMU_VoltageSBAT_RP 6000;
BA_REL_ "GenSigTimeoutTime" BU_SG_REL_ CCIOM SG_ 1350 BPMU_VoltageSBAT_RP 1500;
BA_REL_ "GenSigFirstTimeoutTime" BU_SG_REL_ CCIOM SG_ 1350 BPMU_Conv1Mode_Status 6000;
BA_REL_ "GenSigTimeoutTime" BU_SG_REL_ CCIOM SG_ 1350 BPMU_Conv1Mode_Status 1500;
BA_REL_ "GenSigFirstTimeoutTime" BU_SG_REL_ CCIOM SG_ 1350 BPMU_Conv2Mode_Status 6000;
BA_REL_ "GenSigTimeoutTime" BU_SG_REL_ CCIOM SG_ 1350 BPMU_Conv2Mode_Status 1500;
BA_REL_ "GenSigFirstTimeoutTime" BU_SG_REL_ CCIOM SG_ 1350 BPMU_CurrentECI 6000;
BA_REL_ "GenSigTimeoutTime" BU_SG_REL_ CCIOM SG_ 1350 BPMU_CurrentECI 1500;
BA_REL_ "GenSigFirstTimeoutTime" BU_SG_REL_ CCIOM SG_ 1350 BPMU_RPP_FLT_status 6000;
BA_REL_ "GenSigTimeoutTime" BU_SG_REL_ CCIOM SG_ 1350 BPMU_RPP_FLT_status 1500;
BA_REL_ "GenSigFirstTimeoutTime" BU_SG_REL_ CCIOM SG_ 1348 BPMU_VoltageECI 6000;
BA_REL_ "GenSigTimeoutTime" BU_SG_REL_ CCIOM SG_ 1348 BPMU_VoltageECI 1500;
BA_REL_ "GenSigFirstTimeoutTime" BU_SG_REL_ CCIOM SG_ 1348 BPMU_Voltage12VDO 6000;
BA_REL_ "GenSigTimeoutTime" BU_SG_REL_ CCIOM SG_ 1348 BPMU_Voltage12VDO 1500;
BA_REL_ "GenSigFirstTimeoutTime" BU_SG_REL_ CCIOM SG_ 1348 BPMU_VoltageECILSB_RP 6000;
BA_REL_ "GenSigTimeoutTime" BU_SG_REL_ CCIOM SG_ 1348 BPMU_VoltageECILSB_RP 1500;
BA_REL_ "GenSigFirstTimeoutTime" BU_SG_REL_ CCIOM SG_ 1348 BPMU_VoltageLSB 6000;
BA_REL_ "GenSigTimeoutTime" BU_SG_REL_ CCIOM SG_ 1348 BPMU_VoltageLSB 1500;
BA_REL_ "GenSigFirstTimeoutTime" BU_SG_REL_ CCIOM SG_ 1348 BPMU_VoltageSBAT 6000;
BA_REL_ "GenSigTimeoutTime" BU_SG_REL_ CCIOM SG_ 1348 BPMU_VoltageSBAT 1500;
BA_REL_ "GenSigFirstTimeoutTime" BU_SG_REL_ CCIOM SG_ 1348 BPMU_VoltageHSB_RP 6000;
BA_REL_ "GenSigTimeoutTime" BU_SG_REL_ CCIOM SG_ 1348 BPMU_VoltageHSB_RP 1500;
BA_REL_ "GenSigFirstTimeoutTime" BU_SG_REL_ CCIOM SG_ 1348 BPMU_VoltageHSB 6000;
BA_REL_ "GenSigTimeoutTime" BU_SG_REL_ CCIOM SG_ 1348 BPMU_VoltageHSB 1500;
BA_REL_ "GenSigFirstTimeoutTime" BU_SG_REL_ CCIOM SG_ 1351 BPMU_CurrentLSB 6000;
BA_REL_ "GenSigTimeoutTime" BU_SG_REL_ CCIOM SG_ 1351 BPMU_CurrentLSB 1500;
BA_REL_ "GenSigFirstTimeoutTime" BU_SG_REL_ CCIOM SG_ 1351 BPMU_Current12VDO 6000;
BA_REL_ "GenSigTimeoutTime" BU_SG_REL_ CCIOM SG_ 1351 BPMU_Current12VDO 1500;
BA_REL_ "GenSigFirstTimeoutTime" BU_SG_REL_ CCIOM SG_ 1351 BPMU_CurrentSBAT 6000;
BA_REL_ "GenSigTimeoutTime" BU_SG_REL_ CCIOM SG_ 1351 BPMU_CurrentSBAT 1500;
BA_REL_ "GenSigFirstTimeoutTime" BU_SG_REL_ CCIOM SG_ 1351 BPMU_CurrentHSB 6000;
BA_REL_ "GenSigTimeoutTime" BU_SG_REL_ CCIOM SG_ 1351 BPMU_CurrentHSB 1500;
BA_REL_ "GenSigFirstTimeoutTime" BU_SG_REL_ CCIOM SG_ 1252 BPMU_FaultDiag2 3000;
BA_REL_ "GenSigTimeoutTime" BU_SG_REL_ CCIOM SG_ 1252 BPMU_FaultDiag2 600;
BA_REL_ "GenSigFirstTimeoutTime" BU_SG_REL_ CCIOM SG_ 1252 BPMU_FaultDiag1 3000;
BA_REL_ "GenSigTimeoutTime" BU_SG_REL_ CCIOM SG_ 1252 BPMU_FaultDiag1 600;
BA_REL_ "GenSigFirstTimeoutTime" BU_SG_REL_ RCIOM SG_ 1223 RedGladHand_CRC_ISig_4 3000;
BA_REL_ "GenSigTimeoutTime" BU_SG_REL_ RCIOM SG_ 1223 RedGladHand_CRC_ISig_4 600;
BA_REL_ "GenSigFirstTimeoutTime" BU_SG_REL_ RCIOM SG_ 1223 RedGladHand_ConfidenceLvl_ISig_4 3000;
BA_REL_ "GenSigTimeoutTime" BU_SG_REL_ RCIOM SG_ 1223 RedGladHand_ConfidenceLvl_ISig_4 600;
BA_REL_ "GenSigFirstTimeoutTime" BU_SG_REL_ RCIOM SG_ 1223 RedGladHand_SqC_ISig_4 3000;
BA_REL_ "GenSigTimeoutTime" BU_SG_REL_ RCIOM SG_ 1223 RedGladHand_SqC_ISig_4 600;
BA_REL_ "GenSigFirstTimeoutTime" BU_SG_REL_ RCIOM SG_ 1223 RedGladHand_ConnectStatus_ISig_4 3000;
BA_REL_ "GenSigTimeoutTime" BU_SG_REL_ RCIOM SG_ 1223 RedGladHand_ConnectStatus_ISig_4 600;
BA_REL_ "GenSigFirstTimeoutTime" BU_SG_REL_ CCIOM SG_ 822 EPBPowerFeedRequest_ISig_4 3000;
BA_REL_ "GenSigTimeoutTime" BU_SG_REL_ CCIOM SG_ 822 EPBPowerFeedRequest_ISig_4 180;
BA_REL_ "GenSigFirstTimeoutTime" BU_SG_REL_ RCIOM SG_ 1345 ServiceBrakeAirPrsCircuit1_ISig_ 6000;
BA_REL_ "GenSigTimeoutTime" BU_SG_REL_ RCIOM SG_ 1345 ServiceBrakeAirPrsCircuit1_ISig_ 1500;
BA_REL_ "GenSigFirstTimeoutTime" BU_SG_REL_ RCIOM SG_ 949 LowAirPressureAlert_ISig_4 3000;
BA_REL_ "GenSigTimeoutTime" BU_SG_REL_ RCIOM SG_ 949 LowAirPressureAlert_ISig_4 300;
BA_REL_ "GenSigFirstTimeoutTime" BU_SG_REL_ RCIOM SG_ 949 ParkBrakeActuationStatus_ISig_4 3000;
BA_REL_ "GenSigTimeoutTime" BU_SG_REL_ RCIOM SG_ 949 ParkBrakeActuationStatus_ISig_4 300;
BA_REL_ "GenSigFirstTimeoutTime" BU_SG_REL_ CCIOM SG_ 949 ParkBrakeActuationStatus_ISig_4 3000;
BA_REL_ "GenSigTimeoutTime" BU_SG_REL_ CCIOM SG_ 949 ParkBrakeActuationStatus_ISig_4 300;
VAL_ 1453 BatterySOCTrustLevel_stat1_1A 15 "BatteryTrustLevel_NotAvailable" 14 "BatteryTrustLevel_Error" 13 "BatteryTrustLevel_Spare9" 12 "BatteryTrustLevel_Spare8" 11 "BatteryTrustLevel_Spare7" 10 "BatteryTrustLevel_Spare6" 9 "BatteryTrustLevel_Spare5" 8 "BatteryTrustLevel_Spare4" 7 "BatteryTrustLevel_Spare3" 6 "BatteryTrustLevel_Spare2" 5 "BatteryTrustLevel_Spare1" 4 "BatteryTrustLevel_NominalPlus15PercentAndAbove" 3 "BatteryTrustLevel_NominalPlus10Percent" 2 "BatteryTrustLevel_NominalPlus5Percent" 1 "BatteryTrustLevel_NominalAccuracy" 0 "BatteryTrustLevel_NotInitialized" ;
VAL_ 1453 BatterySOHTrustLevel_stat1_1A 15 "BatteryTrustLevel_NotAvailable" 14 "BatteryTrustLevel_Error" 13 "BatteryTrustLevel_Spare9" 12 "BatteryTrustLevel_Spare8" 11 "BatteryTrustLevel_Spare7" 10 "BatteryTrustLevel_Spare6" 9 "BatteryTrustLevel_Spare5" 8 "BatteryTrustLevel_Spare4" 7 "BatteryTrustLevel_Spare3" 6 "BatteryTrustLevel_Spare2" 5 "BatteryTrustLevel_Spare1" 4 "BatteryTrustLevel_NominalPlus15PercentAndAbove" 3 "BatteryTrustLevel_NominalPlus10Percent" 2 "BatteryTrustLevel_NominalPlus5Percent" 1 "BatteryTrustLevel_NominalAccuracy" 0 "BatteryTrustLevel_NotInitialized" ;
VAL_ 1453 BatteryExchangeDetect_1A 7 "BatteryExchangeDetectionStat_NotAvailable" 6 "BatteryExchangeDetectionStat_Error" 5 "BatteryExchangeDetectionStat_Spare2" 4 "BatteryExchangeDetectionStat_Spare1" 3 "BatteryExchangeDetectionStat_ExchangeNotDetected" 2 "BatteryExchangeDetectionStat_ExchangeDetected" 1 "BatteryExchangeDetectionStat_AlgorithmRunning" 0 "BatteryExchangeDetectionStat_AlgorithmNotRunning" ;
VAL_ 1453 BatterySOHPowerTrustLevel1_1A 15 "BatteryTrustLevel_NotAvailable" 14 "BatteryTrustLevel_Error" 13 "BatteryTrustLevel_Spare9" 12 "BatteryTrustLevel_Spare8" 11 "BatteryTrustLevel_Spare7" 10 "BatteryTrustLevel_Spare6" 9 "BatteryTrustLevel_Spare5" 8 "BatteryTrustLevel_Spare4" 7 "BatteryTrustLevel_Spare3" 6 "BatteryTrustLevel_Spare2" 5 "BatteryTrustLevel_Spare1" 4 "BatteryTrustLevel_NominalPlus15PercentAndAbove" 3 "BatteryTrustLevel_NominalPlus10Percent" 2 "BatteryTrustLevel_NominalPlus5Percent" 1 "BatteryTrustLevel_NominalAccuracy" 0 "BatteryTrustLevel_NotInitialized" ;
VAL_ 1451 BatterySOHTrustLevel_stat1_1B 15 "BatteryTrustLevel_NotAvailable" 14 "BatteryTrustLevel_Error" 13 "BatteryTrustLevel_Spare9" 12 "BatteryTrustLevel_Spare8" 11 "BatteryTrustLevel_Spare7" 10 "BatteryTrustLevel_Spare6" 9 "BatteryTrustLevel_Spare5" 8 "BatteryTrustLevel_Spare4" 7 "BatteryTrustLevel_Spare3" 6 "BatteryTrustLevel_Spare2" 5 "BatteryTrustLevel_Spare1" 4 "BatteryTrustLevel_NominalPlus15PercentAndAbove" 3 "BatteryTrustLevel_NominalPlus10Percent" 2 "BatteryTrustLevel_NominalPlus5Percent" 1 "BatteryTrustLevel_NominalAccuracy" 0 "BatteryTrustLevel_NotInitialized" ;
VAL_ 1451 BatteryExchangeDetect_1B 7 "BatteryExchangeDetectionStat_NotAvailable" 6 "BatteryExchangeDetectionStat_Error" 5 "BatteryExchangeDetectionStat_Spare2" 4 "BatteryExchangeDetectionStat_Spare1" 3 "BatteryExchangeDetectionStat_ExchangeNotDetected" 2 "BatteryExchangeDetectionStat_ExchangeDetected" 1 "BatteryExchangeDetectionStat_AlgorithmRunning" 0 "BatteryExchangeDetectionStat_AlgorithmNotRunning" ;
VAL_ 1451 BatterySOCTrustLevel_stat1_1B 15 "BatteryTrustLevel_NotAvailable" 14 "BatteryTrustLevel_Error" 13 "BatteryTrustLevel_Spare9" 12 "BatteryTrustLevel_Spare8" 11 "BatteryTrustLevel_Spare7" 10 "BatteryTrustLevel_Spare6" 9 "BatteryTrustLevel_Spare5" 8 "BatteryTrustLevel_Spare4" 7 "BatteryTrustLevel_Spare3" 6 "BatteryTrustLevel_Spare2" 5 "BatteryTrustLevel_Spare1" 4 "BatteryTrustLevel_NominalPlus15PercentAndAbove" 3 "BatteryTrustLevel_NominalPlus10Percent" 2 "BatteryTrustLevel_NominalPlus5Percent" 1 "BatteryTrustLevel_NominalAccuracy" 0 "BatteryTrustLevel_NotInitialized" ;
VAL_ 1451 BatterySOHPowerTrustLevel1_1B 15 "BatteryTrustLevel_NotAvailable" 14 "BatteryTrustLevel_Error" 13 "BatteryTrustLevel_Spare9" 12 "BatteryTrustLevel_Spare8" 11 "BatteryTrustLevel_Spare7" 10 "BatteryTrustLevel_Spare6" 9 "BatteryTrustLevel_Spare5" 8 "BatteryTrustLevel_Spare4" 7 "BatteryTrustLevel_Spare3" 6 "BatteryTrustLevel_Spare2" 5 "BatteryTrustLevel_Spare1" 4 "BatteryTrustLevel_NominalPlus15PercentAndAbove" 3 "BatteryTrustLevel_NominalPlus10Percent" 2 "BatteryTrustLevel_NominalPlus5Percent" 1 "BatteryTrustLevel_NominalAccuracy" 0 "BatteryTrustLevel_NotInitialized" ;
VAL_ 1449 BatterySOHTrustLevel_stat1_2A 15 "BatteryTrustLevel_NotAvailable" 14 "BatteryTrustLevel_Error" 13 "BatteryTrustLevel_Spare9" 12 "BatteryTrustLevel_Spare8" 11 "BatteryTrustLevel_Spare7" 10 "BatteryTrustLevel_Spare6" 9 "BatteryTrustLevel_Spare5" 8 "BatteryTrustLevel_Spare4" 7 "BatteryTrustLevel_Spare3" 6 "BatteryTrustLevel_Spare2" 5 "BatteryTrustLevel_Spare1" 4 "BatteryTrustLevel_NominalPlus15PercentAndAbove" 3 "BatteryTrustLevel_NominalPlus10Percent" 2 "BatteryTrustLevel_NominalPlus5Percent" 1 "BatteryTrustLevel_NominalAccuracy" 0 "BatteryTrustLevel_NotInitialized" ;
VAL_ 1449 BatterySOHPowerTrustLevel1_2A 15 "BatteryTrustLevel_NotAvailable" 14 "BatteryTrustLevel_Error" 13 "BatteryTrustLevel_Spare9" 12 "BatteryTrustLevel_Spare8" 11 "BatteryTrustLevel_Spare7" 10 "BatteryTrustLevel_Spare6" 9 "BatteryTrustLevel_Spare5" 8 "BatteryTrustLevel_Spare4" 7 "BatteryTrustLevel_Spare3" 6 "BatteryTrustLevel_Spare2" 5 "BatteryTrustLevel_Spare1" 4 "BatteryTrustLevel_NominalPlus15PercentAndAbove" 3 "BatteryTrustLevel_NominalPlus10Percent" 2 "BatteryTrustLevel_NominalPlus5Percent" 1 "BatteryTrustLevel_NominalAccuracy" 0 "BatteryTrustLevel_NotInitialized" ;
VAL_ 1449 BatterySOCTrustLevel_stat1_2A 15 "BatteryTrustLevel_NotAvailable" 14 "BatteryTrustLevel_Error" 13 "BatteryTrustLevel_Spare9" 12 "BatteryTrustLevel_Spare8" 11 "BatteryTrustLevel_Spare7" 10 "BatteryTrustLevel_Spare6" 9 "BatteryTrustLevel_Spare5" 8 "BatteryTrustLevel_Spare4" 7 "BatteryTrustLevel_Spare3" 6 "BatteryTrustLevel_Spare2" 5 "BatteryTrustLevel_Spare1" 4 "BatteryTrustLevel_NominalPlus15PercentAndAbove" 3 "BatteryTrustLevel_NominalPlus10Percent" 2 "BatteryTrustLevel_NominalPlus5Percent" 1 "BatteryTrustLevel_NominalAccuracy" 0 "BatteryTrustLevel_NotInitialized" ;
VAL_ 1449 BatteryExchangeDetect_2A 7 "BatteryExchangeDetectionStat_NotAvailable" 6 "BatteryExchangeDetectionStat_Error" 5 "BatteryExchangeDetectionStat_Spare2" 4 "BatteryExchangeDetectionStat_Spare1" 3 "BatteryExchangeDetectionStat_ExchangeNotDetected" 2 "BatteryExchangeDetectionStat_ExchangeDetected" 1 "BatteryExchangeDetectionStat_AlgorithmRunning" 0 "BatteryExchangeDetectionStat_AlgorithmNotRunning" ;
VAL_ 1447 BatteryExchangeDetect_2B 7 "BatteryExchangeDetectionStat_NotAvailable" 6 "BatteryExchangeDetectionStat_Error" 5 "BatteryExchangeDetectionStat_Spare2" 4 "BatteryExchangeDetectionStat_Spare1" 3 "BatteryExchangeDetectionStat_ExchangeNotDetected" 2 "BatteryExchangeDetectionStat_ExchangeDetected" 1 "BatteryExchangeDetectionStat_AlgorithmRunning" 0 "BatteryExchangeDetectionStat_AlgorithmNotRunning" ;
VAL_ 1447 BatterySOHPowerTrustLevel1_2B 15 "BatteryTrustLevel_NotAvailable" 14 "BatteryTrustLevel_Error" 13 "BatteryTrustLevel_Spare9" 12 "BatteryTrustLevel_Spare8" 11 "BatteryTrustLevel_Spare7" 10 "BatteryTrustLevel_Spare6" 9 "BatteryTrustLevel_Spare5" 8 "BatteryTrustLevel_Spare4" 7 "BatteryTrustLevel_Spare3" 6 "BatteryTrustLevel_Spare2" 5 "BatteryTrustLevel_Spare1" 4 "BatteryTrustLevel_NominalPlus15PercentAndAbove" 3 "BatteryTrustLevel_NominalPlus10Percent" 2 "BatteryTrustLevel_NominalPlus5Percent" 1 "BatteryTrustLevel_NominalAccuracy" 0 "BatteryTrustLevel_NotInitialized" ;
VAL_ 1447 BatterySOHTrustLevel_stat1_2B 15 "BatteryTrustLevel_NotAvailable" 14 "BatteryTrustLevel_Error" 13 "BatteryTrustLevel_Spare9" 12 "BatteryTrustLevel_Spare8" 11 "BatteryTrustLevel_Spare7" 10 "BatteryTrustLevel_Spare6" 9 "BatteryTrustLevel_Spare5" 8 "BatteryTrustLevel_Spare4" 7 "BatteryTrustLevel_Spare3" 6 "BatteryTrustLevel_Spare2" 5 "BatteryTrustLevel_Spare1" 4 "BatteryTrustLevel_NominalPlus15PercentAndAbove" 3 "BatteryTrustLevel_NominalPlus10Percent" 2 "BatteryTrustLevel_NominalPlus5Percent" 1 "BatteryTrustLevel_NominalAccuracy" 0 "BatteryTrustLevel_NotInitialized" ;
VAL_ 1447 BatterySOCTrustLevel_stat1_2B 15 "BatteryTrustLevel_NotAvailable" 14 "BatteryTrustLevel_Error" 13 "BatteryTrustLevel_Spare9" 12 "BatteryTrustLevel_Spare8" 11 "BatteryTrustLevel_Spare7" 10 "BatteryTrustLevel_Spare6" 9 "BatteryTrustLevel_Spare5" 8 "BatteryTrustLevel_Spare4" 7 "BatteryTrustLevel_Spare3" 6 "BatteryTrustLevel_Spare2" 5 "BatteryTrustLevel_Spare1" 4 "BatteryTrustLevel_NominalPlus15PercentAndAbove" 3 "BatteryTrustLevel_NominalPlus10Percent" 2 "BatteryTrustLevel_NominalPlus5Percent" 1 "BatteryTrustLevel_NominalAccuracy" 0 "BatteryTrustLevel_NotInitialized" ;
VAL_ 1445 BatterySOHPowerTrustLevel1_3A 15 "BatteryTrustLevel_NotAvailable" 14 "BatteryTrustLevel_Error" 13 "BatteryTrustLevel_Spare9" 12 "BatteryTrustLevel_Spare8" 11 "BatteryTrustLevel_Spare7" 10 "BatteryTrustLevel_Spare6" 9 "BatteryTrustLevel_Spare5" 8 "BatteryTrustLevel_Spare4" 7 "BatteryTrustLevel_Spare3" 6 "BatteryTrustLevel_Spare2" 5 "BatteryTrustLevel_Spare1" 4 "BatteryTrustLevel_NominalPlus15PercentAndAbove" 3 "BatteryTrustLevel_NominalPlus10Percent" 2 "BatteryTrustLevel_NominalPlus5Percent" 1 "BatteryTrustLevel_NominalAccuracy" 0 "BatteryTrustLevel_NotInitialized" ;
VAL_ 1445 BatteryExchangeDetect_3A 7 "BatteryExchangeDetectionStat_NotAvailable" 6 "BatteryExchangeDetectionStat_Error" 5 "BatteryExchangeDetectionStat_Spare2" 4 "BatteryExchangeDetectionStat_Spare1" 3 "BatteryExchangeDetectionStat_ExchangeNotDetected" 2 "BatteryExchangeDetectionStat_ExchangeDetected" 1 "BatteryExchangeDetectionStat_AlgorithmRunning" 0 "BatteryExchangeDetectionStat_AlgorithmNotRunning" ;
VAL_ 1445 BatterySOHTrustLevel_stat1_3A 15 "BatteryTrustLevel_NotAvailable" 14 "BatteryTrustLevel_Error" 13 "BatteryTrustLevel_Spare9" 12 "BatteryTrustLevel_Spare8" 11 "BatteryTrustLevel_Spare7" 10 "BatteryTrustLevel_Spare6" 9 "BatteryTrustLevel_Spare5" 8 "BatteryTrustLevel_Spare4" 7 "BatteryTrustLevel_Spare3" 6 "BatteryTrustLevel_Spare2" 5 "BatteryTrustLevel_Spare1" 4 "BatteryTrustLevel_NominalPlus15PercentAndAbove" 3 "BatteryTrustLevel_NominalPlus10Percent" 2 "BatteryTrustLevel_NominalPlus5Percent" 1 "BatteryTrustLevel_NominalAccuracy" 0 "BatteryTrustLevel_NotInitialized" ;
VAL_ 1445 BatterySOCTrustLevel_stat1_3A 15 "BatteryTrustLevel_NotAvailable" 14 "BatteryTrustLevel_Error" 13 "BatteryTrustLevel_Spare9" 12 "BatteryTrustLevel_Spare8" 11 "BatteryTrustLevel_Spare7" 10 "BatteryTrustLevel_Spare6" 9 "BatteryTrustLevel_Spare5" 8 "BatteryTrustLevel_Spare4" 7 "BatteryTrustLevel_Spare3" 6 "BatteryTrustLevel_Spare2" 5 "BatteryTrustLevel_Spare1" 4 "BatteryTrustLevel_NominalPlus15PercentAndAbove" 3 "BatteryTrustLevel_NominalPlus10Percent" 2 "BatteryTrustLevel_NominalPlus5Percent" 1 "BatteryTrustLevel_NominalAccuracy" 0 "BatteryTrustLevel_NotInitialized" ;
VAL_ 1443 BatterySOCTrustLevel_stat1_3B 15 "BatteryTrustLevel_NotAvailable" 14 "BatteryTrustLevel_Error" 13 "BatteryTrustLevel_Spare9" 12 "BatteryTrustLevel_Spare8" 11 "BatteryTrustLevel_Spare7" 10 "BatteryTrustLevel_Spare6" 9 "BatteryTrustLevel_Spare5" 8 "BatteryTrustLevel_Spare4" 7 "BatteryTrustLevel_Spare3" 6 "BatteryTrustLevel_Spare2" 5 "BatteryTrustLevel_Spare1" 4 "BatteryTrustLevel_NominalPlus15PercentAndAbove" 3 "BatteryTrustLevel_NominalPlus10Percent" 2 "BatteryTrustLevel_NominalPlus5Percent" 1 "BatteryTrustLevel_NominalAccuracy" 0 "BatteryTrustLevel_NotInitialized" ;
VAL_ 1443 BatterySOHPowerTrustLevel1_3B 15 "BatteryTrustLevel_NotAvailable" 14 "BatteryTrustLevel_Error" 13 "BatteryTrustLevel_Spare9" 12 "BatteryTrustLevel_Spare8" 11 "BatteryTrustLevel_Spare7" 10 "BatteryTrustLevel_Spare6" 9 "BatteryTrustLevel_Spare5" 8 "BatteryTrustLevel_Spare4" 7 "BatteryTrustLevel_Spare3" 6 "BatteryTrustLevel_Spare2" 5 "BatteryTrustLevel_Spare1" 4 "BatteryTrustLevel_NominalPlus15PercentAndAbove" 3 "BatteryTrustLevel_NominalPlus10Percent" 2 "BatteryTrustLevel_NominalPlus5Percent" 1 "BatteryTrustLevel_NominalAccuracy" 0 "BatteryTrustLevel_NotInitialized" ;
VAL_ 1443 BatterySOHTrustLevel_stat1_3B 15 "BatteryTrustLevel_NotAvailable" 14 "BatteryTrustLevel_Error" 13 "BatteryTrustLevel_Spare9" 12 "BatteryTrustLevel_Spare8" 11 "BatteryTrustLevel_Spare7" 10 "BatteryTrustLevel_Spare6" 9 "BatteryTrustLevel_Spare5" 8 "BatteryTrustLevel_Spare4" 7 "BatteryTrustLevel_Spare3" 6 "BatteryTrustLevel_Spare2" 5 "BatteryTrustLevel_Spare1" 4 "BatteryTrustLevel_NominalPlus15PercentAndAbove" 3 "BatteryTrustLevel_NominalPlus10Percent" 2 "BatteryTrustLevel_NominalPlus5Percent" 1 "BatteryTrustLevel_NominalAccuracy" 0 "BatteryTrustLevel_NotInitialized" ;
VAL_ 1443 BatteryExchangeDetect_3B 7 "BatteryExchangeDetectionStat_NotAvailable" 6 "BatteryExchangeDetectionStat_Error" 5 "BatteryExchangeDetectionStat_Spare2" 4 "BatteryExchangeDetectionStat_Spare1" 3 "BatteryExchangeDetectionStat_ExchangeNotDetected" 2 "BatteryExchangeDetectionStat_ExchangeDetected" 1 "BatteryExchangeDetectionStat_AlgorithmRunning" 0 "BatteryExchangeDetectionStat_AlgorithmNotRunning" ;
VAL_ 1441 BatterySOCTrustLevel_stat2_1 15 "BatteryTrustLevel_NotAvailable" 14 "BatteryTrustLevel_Error" 13 "BatteryTrustLevel_Spare9" 12 "BatteryTrustLevel_Spare8" 11 "BatteryTrustLevel_Spare7" 10 "BatteryTrustLevel_Spare6" 9 "BatteryTrustLevel_Spare5" 8 "BatteryTrustLevel_Spare4" 7 "BatteryTrustLevel_Spare3" 6 "BatteryTrustLevel_Spare2" 5 "BatteryTrustLevel_Spare1" 4 "BatteryTrustLevel_NominalPlus15PercentAndAbove" 3 "BatteryTrustLevel_NominalPlus10Percent" 2 "BatteryTrustLevel_NominalPlus5Percent" 1 "BatteryTrustLevel_NominalAccuracy" 0 "BatteryTrustLevel_NotInitialized" ;
VAL_ 1441 BatterySOCTLWeak_ISig_4 15 "BatteryTrustLevel_NotAvailable" 14 "BatteryTrustLevel_Error" 13 "BatteryTrustLevel_Spare9" 12 "BatteryTrustLevel_Spare8" 11 "BatteryTrustLevel_Spare7" 10 "BatteryTrustLevel_Spare6" 9 "BatteryTrustLevel_Spare5" 8 "BatteryTrustLevel_Spare4" 7 "BatteryTrustLevel_Spare3" 6 "BatteryTrustLevel_Spare2" 5 "BatteryTrustLevel_Spare1" 4 "BatteryTrustLevel_NominalPlus15PercentAndAbove" 3 "BatteryTrustLevel_NominalPlus10Percent" 2 "BatteryTrustLevel_NominalPlus5Percent" 1 "BatteryTrustLevel_NominalAccuracy" 0 "BatteryTrustLevel_NotInitialized" ;
VAL_ 1441 BatterySOHCapaTLWeak 15 "BatteryTrustLevel_NotAvailable" 14 "BatteryTrustLevel_Error" 13 "BatteryTrustLevel_Spare9" 12 "BatteryTrustLevel_Spare8" 11 "BatteryTrustLevel_Spare7" 10 "BatteryTrustLevel_Spare6" 9 "BatteryTrustLevel_Spare5" 8 "BatteryTrustLevel_Spare4" 7 "BatteryTrustLevel_Spare3" 6 "BatteryTrustLevel_Spare2" 5 "BatteryTrustLevel_Spare1" 4 "BatteryTrustLevel_NominalPlus15PercentAndAbove" 3 "BatteryTrustLevel_NominalPlus10Percent" 2 "BatteryTrustLevel_NominalPlus5Percent" 1 "BatteryTrustLevel_NominalAccuracy" 0 "BatteryTrustLevel_NotInitialized" ;
VAL_ 1441 BatterySOHTrustLevel_stat2_1 15 "BatteryTrustLevel_NotAvailable" 14 "BatteryTrustLevel_Error" 13 "BatteryTrustLevel_Spare9" 12 "BatteryTrustLevel_Spare8" 11 "BatteryTrustLevel_Spare7" 10 "BatteryTrustLevel_Spare6" 9 "BatteryTrustLevel_Spare5" 8 "BatteryTrustLevel_Spare4" 7 "BatteryTrustLevel_Spare3" 6 "BatteryTrustLevel_Spare2" 5 "BatteryTrustLevel_Spare1" 4 "BatteryTrustLevel_NominalPlus15PercentAndAbove" 3 "BatteryTrustLevel_NominalPlus10Percent" 2 "BatteryTrustLevel_NominalPlus5Percent" 1 "BatteryTrustLevel_NominalAccuracy" 0 "BatteryTrustLevel_NotInitialized" ;
VAL_ 1441 BatterySOHPowerTrustLevel2_1 15 "BatteryTrustLevel_NotAvailable" 14 "BatteryTrustLevel_Error" 13 "BatteryTrustLevel_Spare9" 12 "BatteryTrustLevel_Spare8" 11 "BatteryTrustLevel_Spare7" 10 "BatteryTrustLevel_Spare6" 9 "BatteryTrustLevel_Spare5" 8 "BatteryTrustLevel_Spare4" 7 "BatteryTrustLevel_Spare3" 6 "BatteryTrustLevel_Spare2" 5 "BatteryTrustLevel_Spare1" 4 "BatteryTrustLevel_NominalPlus15PercentAndAbove" 3 "BatteryTrustLevel_NominalPlus10Percent" 2 "BatteryTrustLevel_NominalPlus5Percent" 1 "BatteryTrustLevel_NominalAccuracy" 0 "BatteryTrustLevel_NotInitialized" ;
VAL_ 1441 AirIntakeValve_DiagStatus 3 "DiagStatus_NotAvailalbe" 2 "DiagStatus_Error" 1 "DiagStatus_DiagnosticOK" 0 "DiagStatus_DiagnosticNOK" ;
VAL_ 1382 BPMU_VoltageRefSwitchCmd 3 "ClosedOpen_NotAvailable" 2 "ClosedOpen_Error" 1 "ClosedOpen_Open" 0 "ClosedOpen_Closed" ;
VAL_ 1382 BPMU_Conv1_TargetOn 7 "Conv1_TargetOn_NotAvailable" 6 "Conv1_TargetOn_Error" 5 "Conv1_TargetOn_Spare0" 4 "Conv1_TargetOn_ECItoBAT24" 3 "Conv1_TargetOn_BAT24toECI" 2 "Conv1_TargetOn_BAT12toBAT24" 1 "Conv1_TargetOn_BAT24toBAT12" 0 "Conv1_TargetOn_Off" ;
VAL_ 956 BatteryEndOfChargeHSB_ISig_4 3 "FalseTrue_NotAvaiable" 2 "FalseTrue_Error" 1 "FalseTrue_True" 0 "FalseTrue_False" ;
VAL_ 956 Pto1RequestFeedback 7 "PtoRequestFeedback_NotAvailable" 6 "PtoRequestFeedback_Error" 5 "PtoRequestFeedback_Spare_2" 4 "PtoRequestFeedback_Spare_1" 3 "PtoRequestFeedback_OpenCircuit" 2 "PtoRequestFeedback_ShortCircuitToBattery" 1 "PtoRequestFeedback_ShortCircuitToGround" 0 "PtoRequestFeedback_NoError" ;
VAL_ 956 StratificationStatusHSB 3 "FalseTrue_NotAvaiable" 2 "FalseTrue_Error" 1 "FalseTrue_True" 0 "FalseTrue_False" ;
VAL_ 956 AutoLoadCutOffState_ISig_4 7 "AutoLoadCutOffState_NotAvailable" 6 "AutoLoadCutOffState_Error" 5 "AutoLoadCutOffState_Spare4" 4 "AutoLoadCutOffState_Spare3" 3 "AutoLoadCutOffState_Spare2" 2 "AutoLoadCutOffState_Spare1" 1 "AutoLoadCutOffState_RequestON" 0 "AutoLoadCutOffState_NoRequest" ;
VAL_ 956 BatteryEndOfChargeLSB_ISig_4 3 "FalseTrue_NotAvaiable" 2 "FalseTrue_Error" 1 "FalseTrue_True" 0 "FalseTrue_False" ;
VAL_ 956 FrontTargetLevelReached 3 "InactiveActive_NotAvailable" 2 "InactiveActive_Error" 1 "InactiveActive_Active" 0 "InactiveActive_Inactive" ;
VAL_ 956 Ultracap_Status_ISig_4 7 "Ultracap_Status_NotAvailable" 6 "Ultracap_Status_Error" 5 "Ultracap_Status_Spare3" 4 "Ultracap_Status_Spare2" 3 "Ultracap_Status_Spare1" 2 "Ultracap_Status_Malfunction" 1 "Ultracap_Status_ForceCharging" 0 "Ultracap_Status_Healthy" ;
VAL_ 956 AdditionEnergySourceNeeded24V 7 "AdditionEnergySourceNeeded24V_NotAvailable" 6 "AdditionEnergySourceNeeded24V_Error" 5 "AdditionEnergySourceNeeded24V_Reserved4" 4 "AdditionEnergySourceNeeded24V_Reserved3" 3 "AdditionEnergySourceNeeded24V_Reserved2" 2 "AdditionEnergySourceNeeded24V_Reserved1" 1 "AdditionEnergySourceNeeded24V_1SourceNeeded" 0 "AdditionEnergySourceNeeded24V_False" ;
VAL_ 956 Pto2RequestFeedback 7 "PtoRequestFeedback_NotAvailable" 6 "PtoRequestFeedback_Error" 5 "PtoRequestFeedback_Spare_2" 4 "PtoRequestFeedback_Spare_1" 3 "PtoRequestFeedback_OpenCircuit" 2 "PtoRequestFeedback_ShortCircuitToBattery" 1 "PtoRequestFeedback_ShortCircuitToGround" 0 "PtoRequestFeedback_NoError" ;
VAL_ 956 UltracapDisplay_Stat_ISig_4 7 "StartBatteryDisplay_NotAvailable" 6 "StartBatteryDisplay_Error" 5 "StartBatteryDisplay_StartBattery_ShortCircuit" 4 "StartBatteryDisplay_StartBattery_OverVoltage" 3 "StartBatteryDisplay_StartBattery_OpenCircuit" 2 "StartBatteryDisplay_StartBattery_Idle" 1 "StartBatteryDisplay_StartBattery_Charged" 0 "StartBatteryDisplay_StartBattery_Charging" ;
VAL_ 956 StratificationStatusLSB 3 "FalseTrue_NotAvaiable" 2 "FalseTrue_Error" 1 "FalseTrue_True" 0 "FalseTrue_False" ;
VAL_ 1313 BPMU_Conv2_TargetOn 7 "Conv2_TargetOn_NotAvailable" 6 "Conv2_TargetOn_Error" 5 "Conv2_TargetOn_Spare3" 4 "Conv2_TargetOn_Spare2" 3 "Conv2_TargetOn_Spare1" 2 "Conv2_TargetOn_SBATtoBAT24" 1 "Conv2_TargetOn_BAT24toSBAT" 0 "Conv2_TargetOn_Off" ;
VAL_ 1251 ExtraBBKingPinFeedback 3 "InactiveActive_NotAvailable" 2 "InactiveActive_Error" 1 "InactiveActive_Active" 0 "InactiveActive_Inactive" ;
VAL_ 1251 DiffLockInterWhlStatusFrAxle2 3 "DisengageEngage_NotAvailable" 2 "DisengageEngage_Error" 1 "DisengageEngage_Engage" 0 "DisengageEngage_Disengage" ;
VAL_ 1251 PluggedVehicleWakeUp_rqst 3 "NotRequested_NotAvailable" 2 "NotRequested_Error" 1 "NotRequested_Requested" 0 "NotRequested_NotRequested" ;
VAL_ 1251 GearRangeUnengaged_ISig_4 3 "GearInhibation_NotAvailable" 2 "GearInhibation_Error" 1 "GearInhibation_GearChangeInhibited" 0 "GearInhibation_NoInhibation" ;
VAL_ 1251 GChargerStatus_ISig_4 7 "GridCharger_stat_NotAvailable" 6 "GridCharger_stat_Error" 5 "GridCharger_stat_GridchargerTemperatureIssue" 4 "GridCharger_stat_Reversepolarityissue" 3 "GridCharger_stat_MaintenanceCharging" 2 "GridCharger_stat_Charging" 1 "GridCharger_stat_Connected" 0 "GridCharger_stat_NotConnected" ;
VAL_ 1251 LivBatteryCharging_stat_ISig_4 3 "NotConfirmedConfirmed_NotAvailable" 2 "NotConfirmedConfirmed_Error" 1 "NotConfirmedConfirmed_Confirmed" 0 "NotConfirmedConfirmed_NotConfirmed" ;
VAL_ 1251 FrontFactorySupportModeStatus 7 "FrontFactorySupportModeStatus_NotAvailable" 6 "FrontFactorySupportModeStatus_Error" 5 "FrontFactorySupportModeStatus_LvlNotRValvCtrlOverride" 4 "FrontFactorySupportModeStatus_LvlNotRCtrlStop" 3 "FrontFactorySupportModeStatus_LvlNotRValvOpenTimeOut" 2 "FrontFactorySupportModeStatus_LowSupPres" 1 "FrontFactorySupportModeStatus_LvlNotRLvlAdjActive" 0 "FrontFactorySupportModeStatus_LevelReached" ;
VAL_ 1251 LivBatDisconnectDetectStat_ISig_ 3 "LivBatDisconnectDetectStat_Not_Available" 2 "LivBatDisconnectDetectStat_Error" 1 "LivBatDisconnectDetectStat_Battery_Disconnected" 0 "LivBatDisconnectDetectStat_Battery_NotDisconnected" ;
VAL_ 1251 SideMarkersLight4_FailStat 7 "FailStat_NotAvailable" 6 "FailStat_Error" 5 "FailStat_Spare2" 4 "FailStat_ShortCircuitToBatteryOrOpen" 3 "FailStat_ShortCircuitToBattery" 2 "FailStat_ShortCircuitToGround" 1 "FailStat_OpenCircuit" 0 "FailStat_NoError" ;
VAL_ 1251 DiffLockInterWhlStatSplitBox2 3 "DisengageEngage_NotAvailable" 2 "DisengageEngage_Error" 1 "DisengageEngage_Engage" 0 "DisengageEngage_Disengage" ;
VAL_ 1251 StratificationStatus 3 "FalseTrue_NotAvaiable" 2 "FalseTrue_Error" 1 "FalseTrue_True" 0 "FalseTrue_False" ;
VAL_ 1251 Cab12VSupplyStatus_ISig_4 3 "Cab12VSupplyStatus_NotAvailable" 2 "Cab12VSupplyStatus_Error" 1 "Cab12VSupplyStatus_CabSupplyError" 0 "Cab12VSupplyStatus_OK" ;
VAL_ 1242 BatteryTempAlertRawData_rqst_ISi 7 "BatteryTempAlert_rqst_NotAvailable" 6 "BatteryTempAlert_rqst_Error" 5 "BatteryTempAlert_rqst_Spare3" 4 "BatteryTempAlert_rqst_Spare2" 3 "BatteryTempAlert_rqst_Spare1" 2 "BatteryTempAlert_rqst_CriticalAlertLowTemp" 1 "BatteryTempAlert_rqst_PreAlertLowTemp" 0 "BatteryTempAlert_rqst_NoAlertRequested" ;
VAL_ 1242 BatteryTempAlert_rqst_ISig_4 7 "BatteryTempAlert_rqst_NotAvailable" 6 "BatteryTempAlert_rqst_Error" 5 "BatteryTempAlert_rqst_Spare3" 4 "BatteryTempAlert_rqst_Spare2" 3 "BatteryTempAlert_rqst_Spare1" 2 "BatteryTempAlert_rqst_CriticalAlertLowTemp" 1 "BatteryTempAlert_rqst_PreAlertLowTemp" 0 "BatteryTempAlert_rqst_NoAlertRequested" ;
VAL_ 1510 ECSFrontCRC_Status 3 "CRCStatus_NotAvailable" 2 "CRCStatus_Error" 1 "CRCStatus_CRCCalculated" 0 "CRCStatus_CRCCalculationInProcess" ;
VAL_ 823 FrontLimpHomeTrigger 7 "LimpHomeTrigger_NotAvailable" 6 "LimpHomeTrigger_Error" 5 "LimpHomeTrigger_Spare_02" 4 "LimpHomeTrigger_Spare_01" 3 "LimpHomeTrigger_Spare" 2 "LimpHomeTrigger_NoControlLH" 1 "LimpHomeTrigger_ManualControlLH" 0 "LimpHomeTrigger_InactiveLH" ;
VAL_ 823 TransmLowRangeSenseSwitch_ISig_4 3 "OffOn_NotAvailable" 2 "OffOn_Error" 1 "OffOn_On" 0 "OffOn_Off" ;
VAL_ 823 ElectricalLoadReduction_rqst_ISi 7 "ElectricalLoadReduction_rqst_NotAvailable" 6 "ElectricalLoadReduction_rqst_Error" 5 "ElectricalLoadReduction_rqst_SpareValue_02" 4 "ElectricalLoadReduction_rqst_SpareValue_01" 3 "ElectricalLoadReduction_rqst_SpareValue" 2 "ElectricalLoadReduction_rqst_Level2Request" 1 "ElectricalLoadReduction_rqst_Level1Request" 0 "ElectricalLoadReduction_rqst_NoRequest" ;
VAL_ 823 TransmReverseDirectionSw_stat 3 "OffOn_NotAvailable" 2 "OffOn_Error" 1 "OffOn_On" 0 "OffOn_Off" ;
VAL_ 823 DirInd_MiddleSide_Status 7 "DirIndFaultStatus_NotAvailable" 6 "DirIndFaultStatus_Error" 5 "DirIndFaultStatus_SpareValue_01" 4 "DirIndFaultStatus_SpareValue" 3 "DirIndFaultStatus_BothLeftAndRightDirectionIndicatorsFault" 2 "DirIndFaultStatus_RightDirectionIndicatorLampFault" 1 "DirIndFaultStatus_LeftDirectionIndicatorLampFault" 0 "DirIndFaultStatus_NoError" ;
VAL_ 823 BatterySOCAlert_rqst_ISig_4 7 "BatterySOCAlert_rqst_NotAvailable" 6 "BatterySOCAlert_rqst_ErrorIndicator" 5 "BatterySOCAlert_rqst_SpareValue_02" 4 "BatterySOCAlert_rqst_SpareValue_01" 3 "BatterySOCAlert_rqst_SpareValue" 2 "BatterySOCAlert_rqst_CriticalAlert" 1 "BatterySOCAlert_rqst_PreAlert" 0 "BatterySOCAlert_rqst_NoAlertRequested" ;
VAL_ 823 DoubleFrontAxleSteeringWarning_I 3 "DoubleFrontAxleSteeringWarning_NotAvailiable" 2 "DoubleFrontAxleSteeringWarning_Error" 1 "DoubleFrontAxleSteeringWarning_DoubleFrAxleSteeringBackupMode" 0 "DoubleFrontAxleSteeringWarning_NoRequest" ;
VAL_ 823 DifferentialLockStateCentral_ISi 3 "DisengageEngage_NotAvailable" 2 "DisengageEngage_Error" 1 "DisengageEngage_Engage" 0 "DisengageEngage_Disengage" ;
VAL_ 823 FifthWheelLockingInformation_ISi 15 "FifthWheelLockingInformation_NotAvailable" 14 "FifthWheelLockingInformation_Error" 13 "FifthWheelLockingInformation_Spare_07" 12 "FifthWheelLockingInformation_Spare_06" 11 "FifthWheelLockingInformation_Spare_05" 10 "FifthWheelLockingInformation_Spare_04" 9 "FifthWheelLockingInformation_Spare_03" 8 "FifthWheelLockingInformation_Spare_02" 7 "FifthWheelLockingInformation_Spare_01" 6 "FifthWheelLockingInformation_Spare" 5 "FifthWheelLockingInformation_5thWheelSystemError" 4 "FifthWheelLockingInformation_TrailerNotCorrectlyCoupled" 3 "FifthWheelLockingInformation_HandleLockedTrailerRightConnected" 2 "FifthWheelLockingInformation_KingPinEndPosTrailerPlateInContact" 1 "FifthWheelLockingInformation_TrailerPlateInContactW_semitrailer" 0 "FifthWheelLockingInformation_TractorAlone" ;
VAL_ 823 DiffLockInterWhlStatusSplitBox 3 "DisengageEngage_NotAvailable" 2 "DisengageEngage_Error" 1 "DisengageEngage_Engage" 0 "DisengageEngage_Disengage" ;
VAL_ 823 WrknLghtChassisOutpFalr_stat 7 "ElectricalStatus_NotAvailable" 6 "ElectricalStatus_Error" 5 "ElectricalStatus_Spare_01" 4 "ElectricalStatus_Spare" 3 "ElectricalStatus_ShortCircuitToBattery" 2 "ElectricalStatus_ShortCircuitToGround" 1 "ElectricalStatus_OpenCircuit" 0 "ElectricalStatus_NoError" ;
VAL_ 823 DifferentialLockStateFrAxle1_ISi 3 "DisengageEngage_NotAvailable" 2 "DisengageEngage_Error" 1 "DisengageEngage_Engage" 0 "DisengageEngage_Disengage" ;
VAL_ 823 GearSplit_Status_ISig_4 3 "GearSplit_Status_NotAvailable" 2 "GearSplit_Status_Error" 1 "GearSplit_Status_HighSplit" 0 "GearSplit_Status_LowSplit" ;
VAL_ 823 LoadCutOffIndication_cmd_ISig_4 3 "LoadCutOffIndication_cmd_NotAvailable" 2 "LoadCutOffIndication_cmd_Error" 1 "LoadCutOffIndication_cmd_LoadCutOffIndication" 0 "LoadCutOffIndication_cmd_NoIndication" ;
VAL_ 823 FifthWheelHandleLock_ind 3 "UnlockedLocked_NotAvailable" 2 "UnlockedLocked_Error" 1 "UnlockedLocked_Locked" 0 "UnlockedLocked_Unlocked" ;
VAL_ 823 BatteryCapacity_Ack_ISig_4 3 "NokOk_NotAvailable" 2 "NokOk_Error" 1 "NokOk_OK" 0 "NokOk_NOK" ;
VAL_ 1244 EqualizerUnbalance_ISig_4 7 "NoWarning3bit_NotAvailable" 6 "NoWarning3bit_Error" 5 "NoWarning3bit_Spare4" 4 "NoWarning3bit_Spare3" 3 "NoWarning3bit_Spare2" 2 "NoWarning3bit_Spare1" 1 "NoWarning3bit_Warning" 0 "NoWarning3bit_NoWarning" ;
VAL_ 1244 ShortStopHeater_status_ISig_4 7 "ShortStopHeaterStatus_NotAvailable" 6 "ShortStopHeaterStatus_Error" 5 "ShortStopHeaterStatus_Spare3" 4 "ShortStopHeaterStatus_Spare2" 3 "ShortStopHeaterStatus_Spare1" 2 "ShortStopHeaterStatus_ActivatedAndPumpNotEngaged" 1 "ShortStopHeaterStatus_ActivatedAndPumpEngaged" 0 "ShortStopHeaterStatus_NotActivated" ;
VAL_ 1244 ExtraBBContUnlockFeedback 3 "InactiveActive_NotAvailable" 2 "InactiveActive_Error" 1 "InactiveActive_Active" 0 "InactiveActive_Inactive" ;
VAL_ 1244 TrailerRevAndFogOutput_stat_ISig 3 "TrailerRevAndFogOutput_stat_NotAvailable" 2 "TrailerRevAndFogOutput_stat_AtLeastOneLampNotOK" 1 "TrailerRevAndFogOutput_stat_AllLampsOK" 0 "TrailerRevAndFogOutput_stat_NotTested" ;
VAL_ 1244 ExtraBBSlidable5WFeedback 3 "InactiveActive_NotAvailable" 2 "InactiveActive_Error" 1 "InactiveActive_Active" 0 "InactiveActive_Inactive" ;
VAL_ 1244 TrailerBrakePres_stat 3 "InactiveActive_NotAvailable" 2 "InactiveActive_Error" 1 "InactiveActive_Active" 0 "InactiveActive_Inactive" ;
VAL_ 1237 FrontAirDumpStatus 7 "AirDumpStatus2_NotAvailable" 6 "AirDumpStatus2_Error" 5 "AirDumpStatus2_Spare2" 4 "AirDumpStatus2_Spare1" 3 "AirDumpStatus2_Idle" 2 "AirDumpStatus2_PressureUpdate" 1 "AirDumpStatus2_Active" 0 "AirDumpStatus2_Inactive" ;
VAL_ 1237 BatterySOCAlertRawData_rqst_ISig 7 "BatterySOCAlert_rqst_NotAvailable" 6 "BatterySOCAlert_rqst_ErrorIndicator" 5 "BatterySOCAlert_rqst_SpareValue_02" 4 "BatterySOCAlert_rqst_SpareValue_01" 3 "BatterySOCAlert_rqst_SpareValue" 2 "BatterySOCAlert_rqst_CriticalAlert" 1 "BatterySOCAlert_rqst_PreAlert" 0 "BatterySOCAlert_rqst_NoAlertRequested" ;
VAL_ 774 Pto1FeedbackStatus 3 "OffOn_NotAvailable" 2 "OffOn_Error" 1 "OffOn_On" 0 "OffOn_Off" ;
VAL_ 774 ReverseGearEngaged_ISig_4 3 "ReverseGearEngaged_NotAvailable" 2 "ReverseGearEngaged_Error" 1 "ReverseGearEngaged_ReverseGearEngaged" 0 "ReverseGearEngaged_ReverseGearNotEngaged" ;
VAL_ 774 PneumaticTrailerBrakeStatus_ISig 3 "BrakeStatus_NotAvailable" 2 "BrakeStatus_Error" 1 "BrakeStatus_Braking" 0 "BrakeStatus_NotBraking" ;
VAL_ 774 SWBrakeSwitch2 3 "BrakeSwitch_NotAvailable" 2 "BrakeSwitch_Error" 1 "BrakeSwitch_BrakePedalDepressed" 0 "BrakeSwitch_BrakePedalReleased" ;
VAL_ 774 NeutralSwitch_stat 3 "NeutralSwitch_stat_NotAvailable" 2 "NeutralSwitch_stat_Error" 1 "NeutralSwitch_stat_InNeutral" 0 "NeutralSwitch_stat_NotInNeutral" ;
VAL_ 774 MainSwitch_Status 3 "ClosedOpen_NotAvailable" 2 "ClosedOpen_Error" 1 "ClosedOpen_Open" 0 "ClosedOpen_Closed" ;
VAL_ 1245 JumpChargeInterface_stat_ISig_4 3 "Connection_Status_NotAvailable" 2 "Connection_Status_Error" 1 "Connection_Status_Connected" 0 "Connection_Status_NotConnected" ;
VAL_ 1245 GridCharger_stat 7 "GridCharger_stat_NotAvailable" 6 "GridCharger_stat_Error" 5 "GridCharger_stat_GridchargerTemperatureIssue" 4 "GridCharger_stat_Reversepolarityissue" 3 "GridCharger_stat_MaintenanceCharging" 2 "GridCharger_stat_Charging" 1 "GridCharger_stat_Connected" 0 "GridCharger_stat_NotConnected" ;
VAL_ 1245 StartBatteryDisplay_stat_ISig_4 7 "StartBatteryDisplay_NotAvailable" 6 "StartBatteryDisplay_Error" 5 "StartBatteryDisplay_StartBattery_ShortCircuit" 4 "StartBatteryDisplay_StartBattery_OverVoltage" 3 "StartBatteryDisplay_StartBattery_OpenCircuit" 2 "StartBatteryDisplay_StartBattery_Idle" 1 "StartBatteryDisplay_StartBattery_Charged" 0 "StartBatteryDisplay_StartBattery_Charging" ;
VAL_ 1350 BPMU_Conv1Mode_Status 7 "Conv1Mode_Status_NotAvailable" 6 "Conv1Mode_Status_Error" 5 "Conv1Mode_Status_Spare1" 4 "Conv1Mode_Status_ECItoBAT24" 3 "Conv1Mode_Status_BAT24toECI" 2 "Conv1Mode_Status_BAT12toBAT24" 1 "Conv1Mode_Status_BAT24toBAT12" 0 "Conv1Mode_Status_OFF" ;
VAL_ 1350 BPMU_Conv2Mode_Status 7 "Conv2Mode_Status_NotAvailable" 6 "Conv2Mode_Status_Error" 5 "Conv2Mode_Status_Spare3" 4 "Conv2Mode_Status_Spare2" 3 "Conv2Mode_Status_Spare1" 2 "Conv2Mode_Status_SBATtoBAT24" 1 "Conv2Mode_Status_BAT24toSBAT" 0 "Conv2Mode_Status_OFF" ;
VAL_ 1223 RedGladHand_ConfidenceLvl_ISig_4 3 "LowHigh_NotAvailable" 2 "LowHigh_Error" 1 "LowHigh_High" 0 "LowHigh_Low" ;
VAL_ 1223 RedGladHand_ConnectStatus_ISig_4 3 "TLConnectStatus_NotAvailable" 2 "TLConnectStatus_Unknown" 1 "TLConnectStatus_Attached" 0 "TLConnectStatus_Detached" ;
VAL_ 822 EPBPowerFeedRequest_ISig_4 3 "Request_NotAvailable" 2 "Request_Error" 1 "Request_RequestActive" 0 "Request_NotRequested" ;
VAL_ 949 LowAirPressureAlert_ISig_4 3 "LowAirPressureAlert_NotAvailable" 2 "LowAirPressureAlert_Error" 1 "LowAirPressureAlert_LowPressure" 0 "LowAirPressureAlert_NormalPressure" ;
VAL_ 949 ParkBrakeActuationStatus_ISig_4 7 "ParkBrakeActuationStatus_NotAvailable" 6 "ParkBrakeActuationStatus_Error" 5 "ParkBrakeActuationStatus_SpareValue_01" 4 "ParkBrakeActuationStatus_SpareValue" 3 "ParkBrakeActuationStatus_AntiCompound" 2 "ParkBrakeActuationStatus_Parked" 1 "ParkBrakeActuationStatus_PartiallyParked" 0 "ParkBrakeActuationStatus_Released" ;
SIG_GROUP_ 1723 BPMU_ParamUpdate_sg 1 : BPMU_ParamUpdate_Data BPMU_ParamUpdate_Selection;
SIG_GROUP_ 1510 ECSFrontCRC_sg 1 : ECSFrontCRC_Status ECSFrontCRC_CRC;
SIG_GROUP_ 831 BPMU_ParamRead_sg 1 : BPMU_ParamRead_Data BPMU_ParamRead_Selection;
SIG_GROUP_ 1223 RedGladHand_sg_ISig_4 1 : RedGladHand_CRC_ISig_4 RedGladHand_ConfidenceLvl_ISig_4 RedGladHand_SqC_ISig_4 RedGladHand_ConnectStatus_ISig_4;
